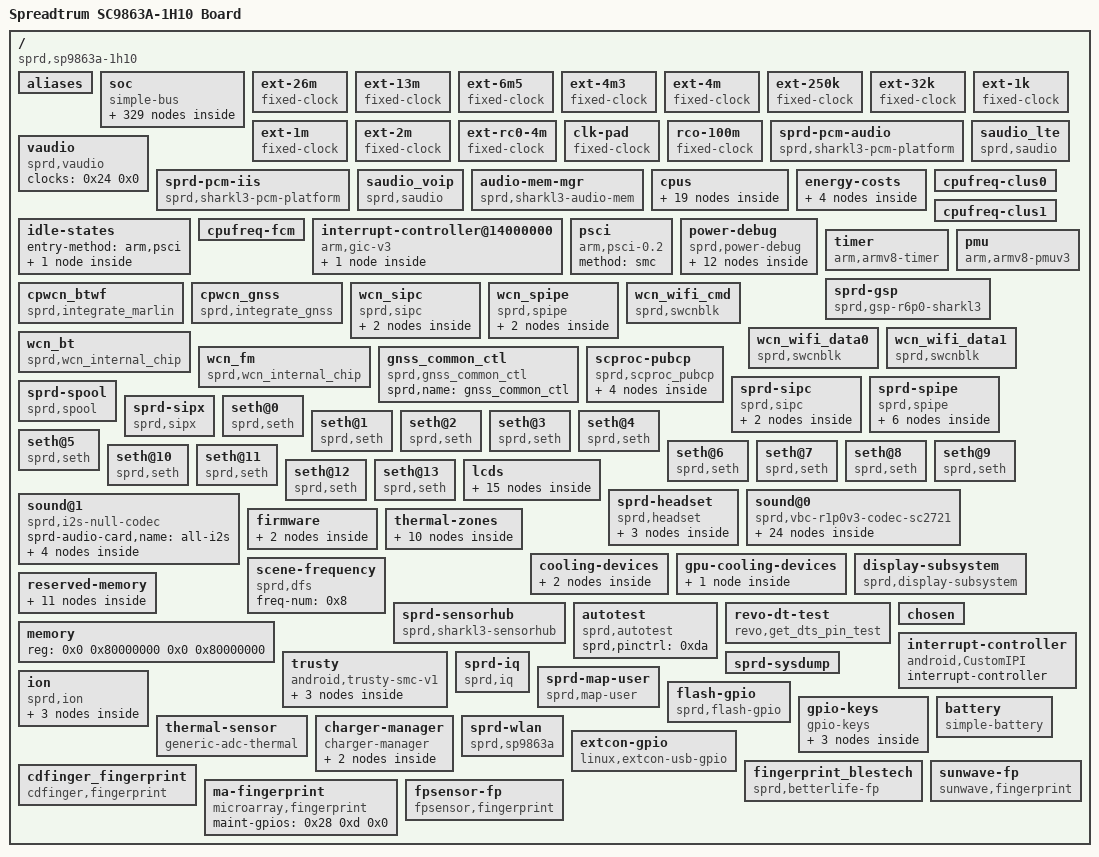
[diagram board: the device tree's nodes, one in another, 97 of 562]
/dts-v1/;

/ {
	interrupt-parent = <0x1>;
	#address-cells = <0x2>;
	#size-cells = <0x2>;
	cpuinfo_hardware = "Unisoc SC9863a";
	model = "Spreadtrum SC9863A-1H10 Board";
	compatible = "sprd,sp9863a-1h10", "sprd,sc9863a";
	sprd,sc-id = <0x2687 0x1 0x20000>;

	aliases {
		i2c0 = "/soc/ap-apb/i2c@70500000";
		i2c1 = "/soc/ap-apb/i2c@70600000";
		i2c2 = "/soc/ap-apb/i2c@70700000";
		i2c3 = "/soc/ap-apb/i2c@70800000";
		i2c4 = "/soc/ap-apb/i2c@70900000";
		i2c5 = "/soc/ap-apb/i2c@71500000";
		i2c6 = "/soc/ap-apb/i2c@71600000";
		i2c7 = "/soc/aon/i2c@40080000";
		spi0 = "/soc/ap-apb/spi@70a00000";
		spi1 = "/soc/ap-apb/spi@70b00000";
		spi2 = "/soc/ap-apb/spi@70c00000";
		spi3 = "/soc/ap-apb/spi@71400000";
		spi4 = "/soc/aon/spi@41800000";
		seth0 = "/seth@0";
		seth1 = "/seth@1";
		seth2 = "/seth@2";
		seth3 = "/seth@3";
		seth4 = "/seth@4";
		seth5 = "/seth@5";
		seth6 = "/seth@6";
		seth7 = "/seth@7";
		seth8 = "/seth@8";
		seth9 = "/seth@9";
		seth10 = "/seth@10";
		seth11 = "/seth@11";
		seth12 = "/seth@12";
		seth13 = "/seth@13";
		cooling-device0 = "/cooling-devices/cluster0-cooling";
		cooling-device1 = "/cooling-devices/cluster1-cooling";
		gpu-cooling0 = "/gpu-cooling-devices/gpu-cooling0";
		thm-sensor11 = "/thermal-zones/cpu-thmzone";
		serial0 = "/soc/ap-apb/serial@70000000";
		serial1 = "/soc/ap-apb/serial@70100000";
	};

	soc {
		compatible = "simple-bus";
		#address-cells = <0x2>;
		#size-cells = <0x2>;
		ranges;
		phandle = <0xe6>;

		modem-dbg-log@1000c000 {
			compatible = "sprd,dbg-log-sharkl3";
			reg = <0x0 0x1000c000 0x0 0x4000>;
			sprd,syscon-aon-apb = <0x2>;
			sprd,syscon-dsi-apb = <0x3>;
			sprd,syscon-pll-apb = <0x4>;
			sprd,ch-name = "TRAINING", "WTL", "MDAR", "TPIU", "DBUS", "WCN";
			sprd,ch-index = <0xf 0x1 0x0 0x2 0x3 0x4>;
			sprd,dcfix;
			sprd,mm;
			status = "okay";
			clock-names = "serdes_eb", "src0", "src1", "src2";
			clocks = <0x5 0x68 0x6 0x0 0x6 0x18 0x6 0x14>;
			phandle = <0xe7>;
		};

		syscon@20e00000 {
			compatible = "syscon";
			#syscon-cells = <0x2>;
			reg = <0x0 0x20e00000 0x0 0x10000>;
			phandle = <0x20>;
		};

		syscon@300e0000 {
			compatible = "syscon";
			#syscon-cells = <0x2>;
			reg = <0x0 0x300e0000 0x0 0x10000>;
			phandle = <0xbd>;
		};

		syscon@300f0000 {
			compatible = "syscon";
			#syscon-cells = <0x2>;
			reg = <0x0 0x300f0000 0x0 0x10000>;
			phandle = <0x73>;
		};

		mailbox@400a0000 {
			compatible = "sprd,mailbox";
			reg = <0x0 0x400a0000 0x0 0x8000 0x0 0x400a8000 0x0 0x8000>;
			syscons = <0x2 0x4 0x200000>;
			syscon-names = "clk";
			interrupts = <0x0 0x44 0x4 0x0 0x45 0x4 0x0 0x77 0x4>;
			sprd,sensor = <0x7>;
			sprd,core-cnt = <0x8>;
			sprd,version = <0x102>;
			phandle = <0xe8>;
		};

		syscon@40200000 {
			compatible = "syscon";
			#syscon-cells = <0x2>;
			reg = <0x0 0x40200000 0x0 0x10000>;
			phandle = <0xe9>;
		};

		syscon@402b0000 {
			compatible = "syscon";
			#syscon-cells = <0x2>;
			reg = <0x0 0x402b0000 0x0 0x10000>;
			phandle = <0x7>;
		};

		power-domain@402b0058 {
			compatible = "sprd,sharkl3-disp-domain";
			reg = <0x0 0x402b0058 0x0 0x20>;
			syscons = <0x7 0x58 0x2000000>;
			syscon-names = "power";
			#power-domain-cells = <0x0>;
			phandle = <0x60>;
		};

		syscon@402e0000 {
			compatible = "syscon";
			#syscon-cells = <0x2>;
			reg = <0x0 0x402e0000 0x0 0x10000>;
			phandle = <0x2>;
		};

		syscon@40350000 {
			compatible = "syscon";
			#syscon-cells = <0x2>;
			reg = <0x0 0x40350000 0x0 0x3000>;
			phandle = <0x3>;
		};

		syscon@40353000 {
			compatible = "syscon";
			#syscon-cells = <0x2>;
			reg = <0x0 0x40353000 0x0 0x6000>;
			phandle = <0x4>;
		};

		syscon@40359000 {
			compatible = "syscon";
			#syscon-cells = <0x2>;
			reg = <0x0 0x40359000 0x0 0x3000>;
			phandle = <0x21>;
		};

		syscon@4035c000 {
			compatible = "syscon";
			#syscon-cells = <0x2>;
			reg = <0x0 0x4035c000 0x0 0x3000>;
			phandle = <0x75>;
		};

		syscon@40363000 {
			compatible = "syscon";
			#syscon-cells = <0x2>;
			reg = <0x0 0x40363000 0x0 0x3000>;
			phandle = <0x29>;
		};

		syscon@40366000 {
			compatible = "syscon";
			#syscon-cells = <0x2>;
			reg = <0x0 0x40366000 0x0 0x3000>;
			phandle = <0xbe>;
		};

		syscon@403a0000 {
			compatible = "syscon";
			#syscon-cells = <0x2>;
			reg = <0x0 0x403a0000 0x0 0x10000>;
			phandle = <0xbf>;
		};

		syscon@60800000 {
			compatible = "syscon";
			#syscon-cells = <0x2>;
			reg = <0x0 0x60800000 0x0 0x10000>;
			phandle = <0x6c>;
		};

		syscon@62000000 {
			compatible = "syscon";
			#syscon-cells = <0x2>;
			reg = <0x0 0x62000000 0x0 0x10000>;
			phandle = <0x63>;
		};

		syscon@71300000 {
			compatible = "syscon";
			#syscon-cells = <0x2>;
			reg = <0x0 0x71300000 0x0 0x40000>;
			phandle = <0x1c>;
		};

		syscon@40500000 {
			compatible = "syscon";
			#syscon-cells = <0x2>;
			reg = <0x0 0x40500000 0x0 0x10000>;
			phandle = <0xaa>;
		};

		syscon@40510000 {
			compatible = "syscon";
			#syscon-cells = <0x2>;
			reg = <0x0 0x40510000 0x0 0x10000>;
			phandle = <0xab>;
		};

		syscon@40520000 {
			compatible = "syscon";
			#syscon-cells = <0x2>;
			reg = <0x0 0x40520000 0x0 0x10000>;
			phandle = <0xac>;
		};

		syscon@40530000 {
			compatible = "syscon";
			#syscon-cells = <0x2>;
			reg = <0x0 0x40530000 0x0 0x10000>;
			phandle = <0xad>;
		};

		syscon@40540000 {
			compatible = "syscon";
			#syscon-cells = <0x2>;
			reg = <0x0 0x40540000 0x0 0x10000>;
			phandle = <0xae>;
		};

		syscon@40550000 {
			compatible = "syscon";
			#syscon-cells = <0x2>;
			reg = <0x0 0x40550000 0x0 0x10000>;
			phandle = <0xaf>;
		};

		ap-apb {
			compatible = "simple-bus";
			#address-cells = <0x1>;
			#size-cells = <0x1>;
			ranges;

			serial@70000000 {
				compatible = "sprd,sc9863-uart", "sprd,sc9836-uart";
				reg = <0x70000000 0x100>;
				interrupts = <0x0 0x2 0x4>;
				clock-names = "enable", "uart", "source";
				clocks = <0x8 0xc 0x9 0x9 0xa>;
				status = "okay";
				phandle = <0xea>;
			};

			serial@70100000 {
				compatible = "sprd,sc9863-uart", "sprd,sc9836-uart";
				reg = <0x70100000 0x100>;
				interrupts = <0x0 0x3 0x4>;
				clock-names = "enable", "uart", "source";
				clocks = <0x8 0xd 0x9 0xa 0xa>;
				status = "okay";
				phandle = <0xeb>;
			};

			serial@70200000 {
				compatible = "sprd,sc9863-uart", "sprd,sc9836-uart";
				reg = <0x70200000 0x100>;
				interrupts = <0x0 0x4 0x4>;
				clock-names = "enable", "uart", "source";
				clocks = <0x8 0xe 0x9 0xb 0xa>;
				status = "disabled";
				phandle = <0xec>;
			};

			serial@70300000 {
				compatible = "sprd,sc9863-uart", "sprd,sc9836-uart";
				reg = <0x70300000 0x100>;
				interrupts = <0x0 0x5 0x4>;
				clock-names = "enable", "uart", "source";
				clocks = <0x8 0xf 0x9 0xc 0xa>;
				status = "disabled";
				phandle = <0xed>;
			};

			serial@70400000 {
				compatible = "sprd,sc9863-uart", "sprd,sc9836-uart";
				reg = <0x70400000 0x100>;
				interrupts = <0x0 0x6 0x4>;
				clock-names = "enable", "uart", "source";
				clocks = <0x8 0x10 0x9 0xd 0xa>;
				status = "disabled";
				phandle = <0xee>;
			};

			i2c@70500000 {
				compatible = "sprd,sharkl3-i2c";
				reg = <0x70500000 0x1000>;
				interrupts = <0x0 0xb 0x4>;
				clock-names = "enable", "i2c", "source";
				clock-frequency = <0x61a80>;
				#address-cells = <0x1>;
				#size-cells = <0x0>;
				status = "okay";
				clocks = <0x8 0x7 0x9 0xe 0xa>;
				phandle = <0xef>;

				sensor-main@20 {
					compatible = "sprd,sensor-main";
					reg = <0x20>;
					clock-names = "clk_src", "sensor_eb", "clk_96m", "clk_76m8", "clk_48m", "clk_26m";
					clocks = <0xb 0x30 0xc 0xb 0x6 0x4 0x6 0x10 0x6 0x5 0xa>;
					vddio-supply = <0xd>;
					vddcama-supply = <0xe>;
					vddcamd-supply = <0xf>;
					vddcammot-supply = <0x10>;
					sprd,phyid = <0x1>;
					csi = <0x11>;
					reset-gpios = <0x12 0x2c 0x0>;
					power-down-gpios = <0x12 0x2e 0x0>;
					avdd-gpios = <0x12 0x49 0x0>;
					phandle = <0xf0>;
				};
			};

			i2c@70600000 {
				compatible = "sprd,sharkl3-i2c";
				reg = <0x70600000 0x1000>;
				interrupts = <0x0 0xc 0x4>;
				clock-names = "enable", "i2c", "source";
				clock-frequency = <0x61a80>;
				#address-cells = <0x1>;
				#size-cells = <0x0>;
				status = "okay";
				clocks = <0x8 0x8 0x9 0xf 0xa>;
				phandle = <0xf1>;

				sensor-sub@20 {
					compatible = "sprd,sensor-sub";
					reg = <0x20>;
					clock-names = "clk_src", "sensor_eb", "clk_96m", "clk_76m8", "clk_48m", "clk_26m";
					clocks = <0xb 0x31 0xc 0xc 0x6 0x4 0x6 0x10 0x6 0x5 0xa>;
					vddio-supply = <0xd>;
					vddcama-supply = <0xe>;
					vddcamd-supply = <0xf>;
					vddcammot-supply = <0x10>;
					sprd,phyid = <0x0>;
					csi = <0x11>;
					reset-gpios = <0x12 0x29 0x0>;
					power-down-gpios = <0x12 0x28 0x0>;
					phandle = <0xf2>;
				};

				sensor-main2@6C {
					compatible = "sprd,sensor-main2";
					reg = <0x6c>;
					clock-names = "clk_src", "sensor_eb", "clk_96m", "clk_76m8", "clk_48m", "clk_26m";
					clocks = <0xb 0x31 0xc 0xc 0x6 0x4 0x6 0x10 0x6 0x5 0xa>;
					vddio-supply = <0xd>;
					vddcama-supply = <0xe>;
					vddcamd-supply = <0xf>;
					vddcammot-supply = <0x10>;
					sprd,phyid = <0x2>;
					csi = <0x13>;
					dvdd-gpios = <0x12 0x3e 0x0>;
					reset-gpios = <0x12 0x2d 0x0>;
					power-down-gpios = <0x12 0x2f 0x0>;
					phandle = <0xf3>;
				};
			};

			i2c@70700000 {
				compatible = "sprd,sharkl3-i2c";
				reg = <0x70700000 0x1000>;
				interrupts = <0x0 0xd 0x4>;
				clock-names = "enable", "i2c", "source";
				clock-frequency = <0x186a0>;
				#address-cells = <0x1>;
				#size-cells = <0x0>;
				status = "disabled";
				clocks = <0x8 0x9 0x9 0x10 0xa>;
				phandle = <0xf4>;
			};

			i2c@70800000 {
				compatible = "sprd,sharkl3-i2c";
				reg = <0x70800000 0x1000>;
				interrupts = <0x0 0xe 0x4>;
				clock-names = "enable", "i2c", "source";
				clock-frequency = <0x61a80>;
				#address-cells = <0x1>;
				#size-cells = <0x0>;
				status = "okay";
				clocks = <0x8 0xa 0x9 0x11 0xa>;
				phandle = <0xf5>;

				goodix_ts@5d {
					compatible = "goodix,gt1x";
					reg = <0x5d>;
					pinctrl-names = "pmx_ts_wakeup", "pmx_ts_normal", "pmx_ts_poweroff", "pmx_ts_sleep";
					pinctrl-0 = <0x14 0x15>;
					pinctrl-1 = <0x16 0x15>;
					pinctrl-2 = <0x17 0x18>;
					pinctrl-3 = <0x17 0x15>;
					reset-gpio = <0x12 0x91 0x0>;
					irq-gpio = <0x12 0x90 0x0>;
					goodix,default-config0 = [4b d0 02 f0 05 25 34 08 20 41 04 0a 78 5a 53 01 01 01 00 00 14 17 19 1d 18 04 00 00 0c 0f 00 00 53 00 14 00 00 00 00 00 00 00 00 64 28 32 8b 2d 0c 3c 3e a2 07 61 3b 62 1b 02 24 00 00 32 5a c0 14 02 00 00 53 a4 38 96 3f 8a 45 7f 4c 78 53 71 00 00 00 00 00 00 00 f0 50 3c aa aa 07 00 00 00 00 00 00 00 00 00 00 00 00 00 00 00 00 3c 00 00 00 00 00 00 00 00 00 00 00 00 00 00 00 00 00 00 df 07 32 10 64 50 50 00 00 00 00 00 01 08 02 09 03 0a 04 0b 05 0c 06 0d ff ff 00 01 02 03 04 05 06 07 08 09 0a 0b 17 16 15 14 13 12 11 10 0f 0e 0d 0c 18 19 00 00 00 00 00 00 00 00 00 00 00 00 00 20 1e 00 05 1e 00 03 1c 1e 19 14 02 00 03 0a 05 32 64 00 00 00 03 00 01 ff e4 84 33 03 eb 06 18 00 14 1e 44 28 3c 28 20 00 00 08 13 94 01];
				};

				tlsc6x@2e {
					compatible = "tlsc6x,tlsc6x_ts";
					reg = <0x2e>;
					reset-gpio = <0x12 0x91 0x0>;
					irq-gpio = <0x12 0x90 0x0>;
				};

				msg2xxx@26 {
					compatible = "msg,msg2xxx";
					reg = <0x26>;
					reset-gpio = <0x12 0x91 0x0>;
					irq-gpio = <0x12 0x90 0x0>;
				};

				focaltech@38 {
					compatible = "focaltech,fts";
					reg = <0x38>;
					reset-gpio = <0x12 0x91 0x0>;
					irq-gpio = <0x12 0x90 0x0>;
					pinctrl-names = "pmx_ts_active", "pmx_ts_suspend", "pmx_ts_release";
					pinctrl-0 = <0x16 0x15>;
					pinctrl-1 = <0x17 0x15>;
					pinctrl-2 = <0x17 0x18>;
					focaltech,reset-gpio = <0x12 0x91 0x0>;
					focaltech,irq-gpio = <0x12 0x90 0x0>;
					focaltech,max-touch-number = <0xa>;
				};

				cst3xx@1a {
					compatible = "cst3xx,cst3xx_ts";
					reg = <0x1a>;
					reset-gpio = <0x12 0x91 0x0>;
					irq-gpio = <0x12 0x90 0x0>;
				};

				himax@48 {
					compatible = "himax,himax_ts";
					reg = <0x48>;
					reset-gpio = <0x12 0x91 0x0>;
					irq-gpio = <0x12 0x90 0x0>;
				};

				ilitek@41 {
					compatible = "tchip,ilitek";
					reg = <0x41>;
					touch,irq-gpio = <0x12 0x90 0x1>;
					touch,reset-gpio = <0x12 0x91 0x1>;
				};
			};

			i2c@70900000 {
				compatible = "sprd,sharkl3-i2c";
				reg = <0x70900000 0x1000>;
				interrupts = <0x0 0xf 0x4>;
				clock-names = "enable", "i2c", "source";
				clock-frequency = <0x61a80>;
				#address-cells = <0x1>;
				#size-cells = <0x0>;
				status = "okay";
				clocks = <0x8 0xb 0x9 0x12 0xa>;
				phandle = <0xf6>;

				charger@6a {
					compatible = "fairchild,fan54015_chg";
					reg = <0x6a>;
					phys = <0x19>;
					monitored-battery = <0x1a>;
					extcon = <0x1b>;
					phandle = <0xf7>;

					otg-vbus {
						regulator-name = "vddvbus";
						phandle = <0x1f>;
					};
				};

				flash-ic@63 {
					compatible = "sprd,flash-ocp8137";
					reg = <0x63>;
					sprd,flash-ic = <0x1fc9>;
					sprd,torch = <0x1>;
					sprd,preflash = <0x1>;
					sprd,highlight = <0x1>;
					sprd,torch-level = <0x80>;
					sprd,preflash-level = <0x80>;
					sprd,highlight-level = <0x80>;
					sprd,lvfm-enable = <0x1>;
					flash-torch-en-gpios = <0x12 0x58 0x0>;
					flash-chip-en-gpios = <0x12 0x59 0x0>;
					flash-en-gpios = <0x12 0x4c 0x0>;
					flash-sync-gpios = <0x12 0x8d 0x0>;
					phandle = <0xf8>;
				};
			};

			spi@70a00000 {
				compatible = "sprd,sc9863-spi";
				reg = <0x70a00000 0x1000>;
				interrupts = <0x0 0x7 0x4>;
				#address-cells = <0x1>;
				#size-cells = <0x0>;
				status = "okay";
				clock-names = "enable", "spi", "source";
				clocks = <0x8 0x4 0x9 0x15 0x6 0x3>;
				phandle = <0xf9>;
			};

			spi@70b00000 {
				compatible = "sprd,sc9863-spi";
				reg = <0x70b00000 0x1000>;
				interrupts = <0x0 0x8 0x4>;
				#address-cells = <0x1>;
				#size-cells = <0x0>;
				status = "disabled";
				clock-names = "enable", "spi", "source";
				clocks = <0x8 0x5 0x9 0x16 0x6 0x3>;
				phandle = <0xfa>;
			};

			spi@70c00000 {
				compatible = "sprd,sc9863-spi";
				reg = <0x70c00000 0x1000>;
				interrupts = <0x0 0x9 0x4>;
				#address-cells = <0x1>;
				#size-cells = <0x0>;
				status = "disabled";
				clock-names = "enable", "spi", "source";
				clocks = <0x8 0x6 0x9 0x17 0x6 0x3>;
				phandle = <0xfb>;
			};

			i2s@70d00000 {
				compatible = "sprd,i2s";
				reg = <0x70d00000 0x100000>;
				sprd,dai_name = "i2s_bt_sco0";
				sprd,hw_port = <0x0>;
				sprd,syscon-ap-apb = <0x1c>;
				#sound-dai-cells = <0x0>;
				status = "okay";
				clock-names = "clk_iis0", "clk_twpll_128m", "clk_twpll_153m6";
				clocks = <0x9 0x19 0x6 0xa 0x6 0xf>;
				sprd,config_type = "pcm";
				sprd,slave_timeout = <0xf11>;
				sprd,_hw_port = <0x0>;
				sprd,fs = <0x1f40>;
				sprd,bus_type = <0x1>;
				sprd,rtx_mode = <0x3>;
				sprd,byte_per_chan = <0x1>;
				sprd,slave_mode = <0x0>;
				sprd,lsb = <0x0>;
				sprd,lrck = <0x0>;
				sprd,low_for_left = <0x1>;
				sprd,clk_inv = <0x0>;
				sprd,pcm_short_frame = <0x1>;
				sprd,pcm_slot = <0x1>;
				sprd,pcm_cycle = <0x1>;
				sprd,tx_watermark = <0xc>;
				sprd,rx_watermark = <0x14>;
				phandle = <0xd1>;
			};

			spi@71400000 {
				compatible = "sprd,sc9863-spi";
				reg = <0x71400000 0x1000>;
				interrupts = <0x0 0x13 0x4>;
				#address-cells = <0x1>;
				#size-cells = <0x0>;
				status = "disabled";
				clock-names = "enable", "spi", "source";
				clocks = <0x8 0x12 0x9 0x18 0x6 0x3>;
				phandle = <0xfc>;
			};

			i2c@71500000 {
				compatible = "sprd,sharkl3-i2c";
				reg = <0x71500000 0x1000>;
				interrupts = <0x0 0x74 0x4>;
				clock-names = "enable", "i2c", "source";
				clock-frequency = <0x186a0>;
				#address-cells = <0x1>;
				#size-cells = <0x0>;
				status = "disabled";
				clocks = <0x8 0x13 0x9 0x13 0xa>;
				phandle = <0xfd>;
			};

			i2c@71600000 {
				compatible = "sprd,sharkl3-i2c";
				reg = <0x71600000 0x1000>;
				interrupts = <0x0 0x75 0x4>;
				clock-names = "enable", "i2c", "source";
				clock-frequency = <0x186a0>;
				#address-cells = <0x1>;
				#size-cells = <0x0>;
				status = "disabled";
				clocks = <0x8 0x14 0x9 0x14 0xa>;
				phandle = <0xfe>;
			};
		};

		ap-ahb {
			compatible = "simple-bus";
			#address-cells = <0x1>;
			#size-cells = <0x1>;
			ranges;

			dma-controller@20100000 {
				compatible = "sprd,sharkl3-dma";
				reg = <0x20100000 0x4000>;
				interrupts = <0x0 0x32 0x4>;
				#dma-cells = <0x1>;
				#dma-channels = <0x1c>;
				clock-names = "enable";
				clocks = <0x1d 0x1>;
				phandle = <0x9b>;
			};

			usb@20200000 {
				compatible = "sprd,sharkl3-musb";
				reg = <0x20200000 0x2000>;
				interrupts = <0x0 0x37 0x4>;
				interrupt-names = "mc";
				clocks = <0x1d 0x0>;
				clock-names = "core_clk";
				phy-type = "usb20_sprd_phy";
				usb-phy = <0x19>;
				phy-names = "usb";
				dr-mode = "peripheral";
				sprd,cable-detection-method = "typec";
				extcon = <0x1b 0x1e>;
				vbus-supply = <0x1f>;
				phandle = <0xff>;
			};

			hsphy@20e00000 {
				compatible = "sprd,sharkl3-phy";
				reg = <0x20e00000 0x3030>;
				reg-names = "phy_glb_regs";
				sprd,syscon-enable = <0x2>;
				sprd,syscon-apahb = <0x20>;
				sprd,syscon-anag4 = <0x21>;
				sprd,vdd-voltage = <0x2e8a10>;
				io-channels = <0x22 0x1e 0x22 0x1f>;
				io-channel-names = "dp", "dm";
				#phy-cells = <0x0>;
				vdd-supply = <0x23>;
				extcon = <0x1b>;
				phandle = <0x19>;
			};

			sdio@20600000 {
				compatible = "sprd,sdhc-r11p1";
				reg = <0x20600000 0x1000>;
				interrupts = <0x0 0x3c 0x4>;
				status = "okay";
				clock-names = "sdio_clk", "sdio_clk_source", "sdio_ahb_enable";
				clocks = <0xb 0x21 0x24 0x2 0x1d 0x7>;
				sprd,hs400es-dly = <0x55 0x7f 0x38 0x38>;
				sprd,hs400-dly = <0x55 0xd3 0x35 0x35>;
				sprd,hs200-dly = <0x7f 0xcd 0xcd 0xcd>;
				sprd,ddr52-dly = <0x32 0x23 0x18 0x18>;
				vmmc-supply = <0x25>;
				voltage-ranges = <0xbb8 0xbb8>;
				bus-width = <0x8>;
				non-removable;
				cap-mmc-hw-reset;
				mmc-hs400-enhanced-strobe;
				mmc-hs400-1_8v;
				mmc-hs200-1_8v;
				mmc-ddr-1_8v;
				sprd,name = "sdio_emmc";
				sprd,sdio-adma;
				no-sdio;
				no-sd;
				phandle = <0x100>;
			};

			sdio@20300000 {
				compatible = "sprd,sdhc-r11p1";
				reg = <0x20300000 0x1000>;
				interrupts = <0x0 0x39 0x4>;
				status = "okay";
				clock-names = "sdio_clk", "sdio_clk_source", "sdio_ahb_enable";
				clocks = <0xb 0x1e 0x24 0x2 0x1d 0x4>;
				sprd,sdr104-dly = <0x7f 0xd1 0xd1 0xd1>;
				sprd,sdr50-dly = <0x7f 0xff 0xff 0xff>;
				sprd,sdhs-dly = <0x7f 0x23 0x22 0x22>;
				vmmc-supply = <0x26>;
				vqmmc-supply = <0x27>;
				voltage-ranges = <0xbb8 0xbb8>;
				bus-width = <0x4>;
				sd-uhs-sdr104;
				sd-uhs-sdr50;
				sprd,name = "sdio_sd";
				sprd,sdio-adma;
				no-sdio;
				no-mmc;
				cd-gpios = <0x28 0x9 0x0>;
				phandle = <0x101>;
			};
		};

		aon {
			compatible = "simple-bus";
			#address-cells = <0x1>;
			#size-cells = <0x1>;
			ranges;

			audio-codec@40000000 {
				compatible = "sprd,sharkl3-audio-codec";
				reg = <0x40000000 0x2000>;
				interrupts = <0x0 0x14 0x0>;
				sprd,syscon-aon-apb = <0x2>;
				sprd,anlg-phy-g-syscon = <0x29>;
				phandle = <0x5e>;
			};

			vbc@40020000 {
				compatible = "sprd,vbc-r1p0v3";
				#sound-dai-cells = <0x1>;
				reg = <0x40020000 0x10000>;
				sprd,clk-stable = <0x402d0060 0x4>;
				sprd,syscon-aon-apb = <0x2>;
				sprd,syscon-pmu-apb = <0x7>;
				sprd,dynamic-eq-support = <0x0>;
				sprd,vbc-iis-lr-invert = <0x0 0x1 0x1>;
				sprd,vbc-use-dma-type = <0x0 0x0 0x0 0x0>;
				sprd,vbc-use-ad01-only = <0x1>;
				sprd,iis_bt_fm_loop = <0x3 0x4>;
				pinctrl-names = "vbc_iis1_0", "ap_iis0_0", "ap_iis1_0", "tgdsp_iis0_0", "tgdsp_iis1_0", "pubcp_iis0_0", "vbc_iis1_3", "ap_iis0_3", "tgdsp_iis0_3", "tgdsp_iis1_3", "pubcp_iis0_3", "wcn_iis0_3", "vbc_iis1_4", "ap_iis0_4", "tgdsp_iis0_4", "tgdsp_iis1_4", "pubcp_iis0_4", "wcn_iis0_4", "iis_bt_fm_loop_3_4_enable", "iis_bt_fm_loop_3_4_disable";
				pinctrl-0 = <0x2a>;
				pinctrl-1 = <0x2b>;
				pinctrl-2 = <0x2c>;
				pinctrl-3 = <0x2d>;
				pinctrl-4 = <0x2e>;
				pinctrl-5 = <0x2f>;
				pinctrl-6 = <0x30>;
				pinctrl-7 = <0x31>;
				pinctrl-8 = <0x32>;
				pinctrl-9 = <0x33>;
				pinctrl-10 = <0x34>;
				pinctrl-11 = <0x35>;
				pinctrl-12 = <0x36>;
				pinctrl-13 = <0x37>;
				pinctrl-14 = <0x38>;
				pinctrl-15 = <0x39>;
				pinctrl-16 = <0x3a>;
				pinctrl-17 = <0x3b>;
				pinctrl-18 = <0x3c>;
				pinctrl-19 = <0x3d>;
				phandle = <0xcd>;
			};

			dma-controller@40100000 {
				compatible = "sprd,sharkl3-dma";
				reg = <0x40100000 0x4000>;
				#dma-cells = <0x1>;
				#dma-channels = <0x9>;
				clock-names = "enable";
				clocks = <0x5 0x32>;
				phandle = <0x9a>;
			};

			gpio@40210000 {
				compatible = "sprd,sharkl3-eic-debounce";
				reg = <0x40210000 0x80 0x40370000 0x80>;
				gpio-controller;
				#gpio-cells = <0x2>;
				interrupt-controller;
				#interrupt-cells = <0x2>;
				interrupts = <0x0 0x25 0x4>;
				phandle = <0xe5>;
			};

			gpio@40210080 {
				compatible = "sprd,sharkl3-eic-latch";
				reg = <0x40210080 0x20 0x40370080 0x20>;
				gpio-controller;
				#gpio-cells = <0x2>;
				interrupt-controller;
				#interrupt-cells = <0x2>;
				interrupts = <0x0 0x25 0x4>;
				phandle = <0x102>;
			};

			gpio@402100a0 {
				compatible = "sprd,sharkl3-eic-async";
				reg = <0x402100a0 0x20 0x403700a0 0x20>;
				gpio-controller;
				#gpio-cells = <0x2>;
				interrupt-controller;
				#interrupt-cells = <0x2>;
				interrupts = <0x0 0x25 0x4>;
				phandle = <0x28>;
			};

			gpio@402100c0 {
				compatible = "sprd,sharkl3-eic-sync";
				reg = <0x402100c0 0x20 0x403700c0 0x20>;
				gpio-controller;
				#gpio-cells = <0x2>;
				interrupt-controller;
				#interrupt-cells = <0x2>;
				interrupts = <0x0 0x25 0x4>;
				phandle = <0x103>;
			};

			timer@40230000 {
				compatible = "sprd,syst-timer";
				reg = <0x40230000 0x10>;
				clocks = <0x3e>;
				phandle = <0x104>;
			};

			timer@40040000 {
				compatible = "sprd,sysfrt-timer";
				reg = <0x40040000 0x10>;
				clocks = <0x3f>;
				phandle = <0x105>;
			};

			timer@40050000 {
				compatible = "sprd,sharkl3-timer";
				reg = <0x40050000 0x14>;
				interrupts = <0x0 0x1b 0x4>;
				clocks = <0x3f>;
			};

			timer@40050020 {
				compatible = "sprd,sharkl3-suspend-timer";
				reg = <0x40050020 0x14>;
				interrupts = <0x0 0x1c 0x4>;
				clocks = <0x3f>;
			};

			efuse@40240000 {
				compatible = "sprd,sharkl3-efuse";
				reg = <0x40240000 0x10000>;
				clock-names = "enable";
				hwlocks = <0x40 0x8>;
				clocks = <0x5 0xd>;
				phandle = <0x106>;

				gthm-delta@21 {
					reg = <0x21 0x4>;
					bits = <0x1 0x7>;
					phandle = <0x51>;
				};

				cthm-sign@22 {
					reg = <0x22 0x4>;
					bits = <0x0 0x1>;
					phandle = <0x52>;
				};

				cthm-ratio@22 {
					reg = <0x22 0x4>;
					bits = <0x1 0x7>;
					phandle = <0x53>;
				};

				cthm-delta@23 {
					reg = <0x23 0x4>;
					bits = <0x0 0x7>;
					phandle = <0x54>;
				};

				wcn-alpha@14 {
					reg = <0x14 0x4>;
					phandle = <0xc3>;
				};

				wcn-beta@18 {
					reg = <0x18 0x4>;
					phandle = <0xc4>;
				};

				wcn-gamma@1c {
					reg = <0x1c 0x4>;
					phandle = <0xc5>;
				};

				wcn-delta@20 {
					reg = <0x20 0x4>;
					phandle = <0xc7>;
				};

				dvfs-bin-dsu@a {
					reg = <0xa 0x4>;
					bits = <0x4 0x4>;
					phandle = <0xa9>;
				};

				dvfs-bin-cpu0@9 {
					reg = <0x9 0x4>;
					bits = <0x0 0x4>;
					phandle = <0xa5>;
				};

				dvfs-bin-cpu1@9 {
					reg = <0x9 0x4>;
					bits = <0x4 0x4>;
					phandle = <0xa7>;
				};
			};

			pwm@40260000 {
				compatible = "sprd,sharkl3-pwm", "sprd,sharkl5-pwm";
				reg = <0x40260000 0x10000>;
				clock-names = "clk_parent", "clk_pwm0", "clk_pwm0_eb", "clk_pwm1", "clk_pwm1_eb", "clk_pwm2", "clk_pwm2_eb";
				clocks = <0xa 0xb 0xf 0x5 0x4 0xb 0x10 0x5 0x5 0xb 0x11 0x5 0x6>;
				#pwm-cells = <0x2>;
				phandle = <0x107>;
			};

			pinctrl@402a0000 {
				compatible = "sprd,sharkl3-pinctrl";
				reg = <0x402a0000 0x10000>;
				pinctrl-names = "gpio_121", "gpio_122", "gpio_123", "gpio_124", "gpio_125", "gpio_126", "gpio_144", "gpio_145", "gpio_146", "gpio_147", "shutdown";
				pinctrl-0 = <0x41>;
				pinctrl-1 = <0x42>;
				pinctrl-2 = <0x43>;
				pinctrl-3 = <0x44>;
				pinctrl-4 = <0x45>;
				pinctrl-5 = <0x46>;
				pinctrl-6 = <0x47>;
				pinctrl-7 = <0x48>;
				pinctrl-8 = <0x49>;
				pinctrl-9 = <0x4a>;
				pinctrl-10 = <0x4b 0x4c 0x4d 0x4e 0x4f 0x50>;
				phandle = <0xda>;

				iismtx-inf0-8 {
					pins = "SHARKL3_IIS_INF0_SYS_SEL";
					sprd,control = <0x8>;
					phandle = <0x2a>;
				};

				iismtx-inf0-0 {
					pins = "SHARKL3_IIS_INF0_SYS_SEL";
					sprd,control = <0x0>;
					phandle = <0x2b>;
				};

				iismtx-inf0-1 {
					pins = "SHARKL3_IIS_INF0_SYS_SEL";
					sprd,control = <0x1>;
					phandle = <0x2c>;
				};

				iismtx-inf0-4 {
					pins = "SHARKL3_IIS_INF0_SYS_SEL";
					sprd,control = <0x4>;
					phandle = <0x2d>;
				};

				iismtx-inf0-5 {
					pins = "SHARKL3_IIS_INF0_SYS_SEL";
					sprd,control = <0x5>;
					phandle = <0x2e>;
				};

				iismtx-inf0-3 {
					pins = "SHARKL3_IIS_INF0_SYS_SEL";
					sprd,control = <0x3>;
					phandle = <0x2f>;
				};

				iismtx-inf3-8 {
					pins = "SHARKL3_IIS_INF3_SYS_SEL";
					sprd,control = <0x8>;
					phandle = <0x30>;
				};

				iismtx-inf3-0 {
					pins = "SHARKL3_IIS_INF3_SYS_SEL";
					sprd,control = <0x0>;
					phandle = <0x31>;
				};

				iismtx-inf3-4 {
					pins = "SHARKL3_IIS_INF3_SYS_SEL";
					sprd,control = <0x4>;
					phandle = <0x32>;
				};

				iismtx-inf3-5 {
					pins = "SHARKL3_IIS_INF3_SYS_SEL";
					sprd,control = <0x5>;
					phandle = <0x33>;
				};

				iismtx-inf3-3 {
					pins = "SHARKL3_IIS_INF3_SYS_SEL";
					sprd,control = <0x3>;
					phandle = <0x34>;
				};

				iismtx-inf3-11 {
					pins = "SHARKL3_IIS_INF3_SYS_SEL";
					sprd,control = <0xb>;
					phandle = <0x35>;
				};

				iismtx-inf4-8 {
					pins = "SHARKL3_IIS_INF4_SYS_SEL";
					sprd,control = <0x8>;
					phandle = <0x36>;
				};

				iismtx-inf4-0 {
					pins = "SHARKL3_IIS_INF4_SYS_SEL";
					sprd,control = <0x0>;
					phandle = <0x37>;
				};

				iismtx-inf4-4 {
					pins = "SHARKL3_IIS_INF4_SYS_SEL";
					sprd,control = <0x4>;
					phandle = <0x38>;
				};

				iismtx-inf4-5 {
					pins = "SHARKL3_IIS_INF4_SYS_SEL";
					sprd,control = <0x5>;
					phandle = <0x39>;
				};

				iismtx-inf4-3 {
					pins = "SHARKL3_IIS_INF4_SYS_SEL";
					sprd,control = <0x3>;
					phandle = <0x3a>;
				};

				iismtx-inf4-11 {
					pins = "SHARKL3_IIS_INF4_SYS_SEL";
					sprd,control = <0xb>;
					phandle = <0x3b>;
				};

				iismtx-inf3-inf4-loop-1 {
					pins = "SHARKL3_IIS_INF4_INF3_LOOP";
					sprd,control = <0x1>;
					phandle = <0x3c>;
				};

				iismtx-inf3-inf4-loop-0 {
					pins = "SHARKL3_IIS_INF4_INF3_LOOP";
					sprd,control = <0x0>;
					phandle = <0x3d>;
				};

				ts_int_pullup {
					pins = "SHARKL3_EXTINT0_MISC";
					drive-strength = <0x8>;
					bias-pull-up;
					phandle = <0x14>;
				};

				ts_int_nopull {
					pins = "SHARKL3_EXTINT0_MISC";
					drive-strength = <0x2>;
					bias-disable;
					phandle = <0x16>;
				};

				ts_int_pulldown {
					pins = "SHARKL3_EXTINT0_MISC";
					drive-strength = <0x2>;
					bias-pull-down;
					phandle = <0x17>;
				};

				ts_reset_pullup {
					pins = "SHARKL3_EXTINT1_MISC";
					drive-strength = <0x8>;
					bias-pull-up;
					phandle = <0x15>;
				};

				ts_reset_pulldown {
					pins = "SHARKL3_EXTINT1_MISC";
					drive-strength = <0x2>;
					bias-pull-down;
					phandle = <0x18>;
				};

				keyout0 {
					pins = "SHARKL3_KEYOUT0";
					function = "func4";
					phandle = <0x41>;
				};

				keyout1 {
					pins = "SHARKL3_KEYOUT1";
					function = "func4";
					phandle = <0x42>;
				};

				keyout2 {
					pins = "SHARKL3_KEYOUT2";
					function = "func4";
					phandle = <0x43>;
				};

				keyin0 {
					pins = "SHARKL3_KEYIN0";
					function = "func4";
					phandle = <0x44>;
				};

				keyin1 {
					pins = "SHARKL3_KEYIN1";
					function = "func4";
					phandle = <0x45>;
				};

				keyin2 {
					pins = "SHARKL3_KEYIN2";
					function = "func4";
					phandle = <0x46>;
				};

				extint0 {
					pins = "SHARKL3_EXTINT0";
					function = "func4";
					phandle = <0x47>;
				};

				extint1 {
					pins = "SHARKL3_EXTINT1";
					function = "func4";
					phandle = <0x48>;
				};

				scl3 {
					pins = "SHARKL3_SCL3";
					function = "func4";
					phandle = <0x49>;
				};

				sda3 {
					pins = "SHARKL3_SDA3";
					function = "func4";
					phandle = <0x4a>;
				};

				rfsen0 {
					pins = "SHARKL3_RFSEN0";
					function = "func4";
					phandle = <0x4b>;
				};

				rfsck0 {
					pins = "SHARKL3_RFSCK0";
					function = "func4";
					phandle = <0x4c>;
				};

				rfsda0 {
					pins = "SHARKL3_RFSDA0";
					function = "func4";
					phandle = <0x4d>;
				};

				rfsen1 {
					pins = "SHARKL3_RFSEN1";
					function = "func4";
					phandle = <0x4e>;
				};

				rfsck1 {
					pins = "SHARKL3_RFSCK1";
					function = "func4";
					phandle = <0x4f>;
				};

				rfsda1 {
					pins = "SHARKL3_RFSDA1";
					function = "func4";
					phandle = <0x50>;
				};
			};

			gpio-controller@402c0000 {
				compatible = "sprd,sharkl3-gpio-plus";
				reg = <0x402c0000 0x1000>;
				gpio-controller;
				#gpio-cells = <0x2>;
				interrupt-controller;
				#interrupt-cells = <0x2>;
				interrupts = <0x0 0x82 0x4>;
				phandle = <0x12>;
			};

			gpu-thm@402f0000 {
				compatible = "sprd,sharkl3-thermal";
				reg = <0x402f0000 0x10000>;
				clock-names = "enable";
				clocks = <0x5 0x20>;
				#thermal-sensor-cells = <0x1>;
				sprd,algor_ver = <0x2>;
				nvmem-cells = <0x51>;
				nvmem-cell-names = "thm_delta_cal";
				phandle = <0xd6>;
			};

			cpu-thm@40390000 {
				compatible = "sprd,sharkl3-thermal";
				reg = <0x40390000 0x10000>;
				clock-names = "enable";
				clocks = <0x5 0x20>;
				#thermal-sensor-cells = <0x1>;
				sprd,algor_ver = <0x1>;
				nvmem-cells = <0x52 0x53 0x54>;
				nvmem-cell-names = "thm_sign_cal", "thm_ratio_cal", "thm_delta_cal";
				phandle = <0xd2>;
			};

			hwspinlock@40060000 {
				compatible = "sprd,hwspinlock-r3p0";
				reg = <0x40060000 0x10000>;
				#hwlock-cells = <0x1>;
				clock-names = "enable";
				clocks = <0x5 0x16>;
				phandle = <0x40>;
			};

			i2c@40080000 {
				compatible = "sprd,sharkl3-hw-i2c";
				reg = <0x40080000 0x1000>;
				interrupts = <0x0 0x22 0x4>;
				clock-names = "enable", "i2c", "source", "clk_hw_i2c";
				clock-frequency = <0x61a80>;
				#address-cells = <0x1>;
				#size-cells = <0x0>;
				status = "okay";
				phandle = <0x108>;

				regulator@60 {
					compatible = "fcs,fan53555";
					reg = <0x60>;
					regulator-name = "fan53555";
					regulator-min-microvolt = <0x93378>;
					regulator-max-microvolt = <0x1587b8>;
					regulator-ramp-delay = <0xfa00>;
					regulator-always-on;
					fcs,suspend-voltage-selector = <0x1>;
					phandle = <0x9c>;
				};
			};

			hwdvfs@40300000 {
				compatible = "sprd,sharkl3-hwdvfs";
				sprd,syscon-enable = <0x2>;
				sprd,anlg-phy-g4-ctrl = <0x21>;
				reg = <0x40300000 0x1000>;
				interrupts = <0x0 0x79 0x4>;
				phandle = <0x109>;

				cluster@0 {
					reg = <0x0>;
					dcdc-ctrl = <0x55>;
					phandle = <0x10a>;
				};

				cluster@1 {
					reg = <0x1>;
					dcdc-ctrl = <0x56>;
					phandle = <0x10b>;
				};

				dsu@0 {
					reg = <0x0>;
					dcdc-ctrl = <0x56>;
					phandle = <0x10c>;
				};

				dcdc-controller@0 {
					reg = <0x0 0x0>;
					volt-via-adi;
					volt-hold-us = <0x32>;
					volt-pause-us = <0x5>;
					volt-timeout-us = <0x320>;
					volt-stable-us = <0x5>;
					volt-max-step-microvolt = <0x61a8>;
					phandle = <0x56>;
				};

				dcdc-controller@1 {
					reg = <0x1 0x2>;
					volt-via-i2c;
					volt-hold-us = <0x19>;
					volt-pause-us = <0x14>;
					volt-timeout-us = <0x320>;
					volt-stable-us = <0x19>;
					volt-max-step-microvolt = <0x124f84>;
					phandle = <0x55>;
				};
			};

			sprd-swdvfs {
				compatible = "sprd,sharkl3-swdvfs";
				phandle = <0x10d>;
			};

			watchdog@40310000 {
				compatible = "sprd,sharkl3-wdt";
				reg = <0x40310000 0x1000>;
				interrupts = <0x0 0x7c 0x4>;
				timeout-sec = <0x1e>;
				clock-names = "enable", "rtc_enable";
				clocks = <0x5 0x26 0x5 0x42>;
			};

			djtag@40340000 {
				compatible = "sprd,djtag";
				reg = <0x40340000 0x1000>;
				syscon-names = "soft_rst";
				syscons = <0x2 0x130 0x80>;
				clock-names = "enable", "tck";
				clocks = <0x5 0x30 0x5 0x29>;
				hwlocks = <0x40 0xa>;
				hwlock-names = "djtag";
				#address-cells = <0x1>;
				#size-cells = <0x0>;
				phandle = <0x10e>;

				aon-busmonitor@3 {
					compatible = "sprd,sharkl3-busmonitor";
					interrupts = <0x0 0x5c 0x4>;
					reg = <0x3>;
					sprd,bm-num = <0x7>;
					sprd,bm-name = "AP", "WTLCP", "PUBCP", "SP", "DMA", "EAXI", "WCN";
					sprd,bm-type = <0x1 0x1 0x1 0x1 0x1 0x1 0x1>;
					sprd,bm-dap = <0x0 0x2 0x1 0x3 0x4 0x5 0x9>;
					sprd,bm-config = <0x0 0x1 0x1 0x0 0x1 0x1 0x0 0x1 0x1 0x0 0x1 0x1 0x0 0x1 0x1 0x0 0x1 0x1 0x0 0x1 0x1>;
					sprd,bm-id = <0x0 0x0 0x0 0x0 0x0 0x0 0x0 0x0 0x0 0x0 0x0 0x0 0x0 0x0 0x0 0x0 0x0 0x0 0x0 0x0 0x0>;
					sprd,bm-ranges = <0x0 0x0 0x0 0x0 0x0 0x0 0x0 0x0 0x0 0x0 0x0 0x0 0x0 0x0>;
				};

				apcpu-busmonitor@7 {
					compatible = "sprd,sharkl3-busmonitor";
					interrupts = <0x0 0x57 0x4>;
					reg = <0x7>;
					sprd,bm-num = <0x2>;
					sprd,bm-name = "ACE", "AP";
					sprd,bm-type = <0x1 0x1>;
					sprd,bm-dap = <0x1 0x2>;
					sprd,bm-config = <0x0 0x1 0x1 0x0 0x1 0x1>;
					sprd,bm-id = <0x0 0x0 0x0 0x0 0x0 0x0>;
					sprd,bm-ranges = <0x0 0x0 0x0 0x0>;
				};
			};

			spi@41800000 {
				compatible = "sprd,sharkl3-adi";
				reg = <0x41800000 0x200000>;
				#address-cells = <0x1>;
				#size-cells = <0x0>;
				sprd,hw-channels = <0x21 0x8c20 0x23 0x8cc4 0x24 0x8cd0 0x13 0x8c44 0x14 0x8c44 0x15 0x8c44 0x16 0x8c44>;
				phandle = <0x10f>;

				pmic@0 {
					compatible = "sprd,sc2721";
					reg = <0x0>;
					spi-max-frequency = <0x18cba80>;
					interrupts = <0x0 0x26 0x4>;
					interrupt-controller;
					#interrupt-cells = <0x2>;
					#address-cells = <0x1>;
					#size-cells = <0x0>;
					phandle = <0x57>;

					led-controller@180 {
						compatible = "sprd,sc27xx-bltc", "sprd,sc2721-bltc";
						#address-cells = <0x1>;
						#size-cells = <0x0>;
						reg = <0x180>;

						led@0 {
							label = "red";
							reg = <0x0>;
						};

						led@1 {
							label = "green";
							reg = <0x1>;
						};

						led@2 {
							label = "blue";
							reg = <0x2>;
						};
					};

					rtc@200 {
						compatible = "sprd,sc27xx-rtc", "sprd,sc2721-rtc";
						reg = <0x200>;
						interrupt-parent = <0x57>;
						interrupts = <0x1 0x4>;
					};

					gpio-controller@280 {
						compatible = "sprd,sc27xx-eic", "sprd,sc2721-eic";
						reg = <0x280>;
						interrupts = <0x4 0x4>;
						interrupt-parent = <0x57>;
						gpio-controller;
						#gpio-cells = <0x2>;
						interrupt-controller;
						#interrupt-cells = <0x2>;
						phandle = <0x5c>;
					};

					flash@2a8 {
						compatible = "sprd,sc27xx-flash", "sprd,sc2721-flash", "sprd,isink-flash";
						reg = <0x2a8>;
						status = "okay";
						phandle = <0x110>;
					};

					prox_kpled {
						compatible = "sprd,sc27xx-keypad-led", "sprd,prox-kpled";
						status = "okay";
					};

					efuse@300 {
						compatible = "sprd,sc27xx-efuse", "sprd,sc2721-efuse";
						reg = <0x300>;
						#address-cells = <0x1>;
						#size-cells = <0x1>;
						hwlocks = <0x40 0xc>;

						calib@6 {
							reg = <0x6 0x2>;
							phandle = <0x5d>;
						};

						calib@24 {
							reg = <0x24 0x2>;
							phandle = <0x5a>;
						};

						calib@26 {
							reg = <0x26 0x2>;
							phandle = <0x5b>;
						};

						calib@1a {
							reg = <0x1a 0x2>;
							phandle = <0x58>;
						};

						calib@0 {
							reg = <0x0 0x2>;
							phandle = <0xc8>;
						};

						calib@28 {
							reg = <0x28 0x2>;
							phandle = <0xc9>;
						};

						calib@2c {
							reg = <0x2c 0x2>;
							phandle = <0xca>;
						};
					};

					typec@380 {
						compatible = "sprd,sc27xx-typec", "sprd,sc2721-typec";
						interrupt-parent = <0x57>;
						interrupts = <0xa 0x4>;
						reg = <0x380>;
						mode = <0x2>;
						nvmem-cells = <0x58>;
						nvmem-cell-names = "cc_calib";
						status = "okay";
						phandle = <0x1e>;
					};

					adc@400 {
						compatible = "sprd,sc27xx-adc", "sprd,sc2721-adc";
						reg = <0x400>;
						verf-supply = <0x59>;
						interrupt-parent = <0x57>;
						interrupts = <0x0 0x4>;
						#io-channel-cells = <0x1>;
						hwlocks = <0x40 0x4>;
						nvmem-cells = <0x5a 0x5b>;
						nvmem-cell-names = "big_scale_calib", "small_scale_calib";
						phandle = <0x22>;
					};

					fgu@a00 {
						compatible = "sprd,sc27xx-fgu", "sprd,sc2720-fgu", "sprd,sc2721-fgu";
						reg = <0xa00>;
						bat-detect-gpio = <0x5c 0x9 0x0>;
						nvmem-cell-names = "fgu_calib";
						nvmem-cells = <0x5d>;
						io-channels = <0x22 0x0 0x22 0xe>;
						io-channel-names = "bat-temp", "charge-vol";
						interrupt-parent = <0x57>;
						interrupts = <0x3 0x4>;
						monitored-battery = <0x1a>;
						sprd,calib-resistance-real = <0x4dbc>;
						sprd,calib-resistance-spec = <0x4e20>;
						first-calib-voltage = <0x36a060>;
						first-calib-capacity = <0x28>;
						phandle = <0x111>;
					};

					syscon@c00 {
						compatible = "sprd,sc27xx-syscon";
						reg = <0xc00 0xecc 0xec0>;
					};

					audio-codec@700 {
						compatible = "sprd,sc2721-audio-codec", "sprd,sc27xx-audio-codec";
						#sound-dai-cells = <0x1>;
						reg = <0x700>;
						interrupts = <0x6 0x0>;
						sprd,syscon-pmu-apb = <0x7>;
						status = "okay";
						digital-codec = <0x5e>;
						phandle = <0xce>;
					};

					power-controller@c00 {
						compatible = "sprd,sc27xx-regulator", "sprd,sc2721-regulator";

						DCDC_CPU {
							regulator-name = "vddcpu";
							regulator-min-microvolt = <0x61a80>;
							regulator-max-microvolt = <0x1e74e0>;
							regulator-ramp-delay = <0x61a8>;
							regulator-always-on;
							phandle = <0xa1>;
						};

						DCDC_CORE {
							regulator-name = "vddcore";
							regulator-min-microvolt = <0x61a80>;
							regulator-max-microvolt = <0x1e74e0>;
							regulator-ramp-delay = <0x61a8>;
							regulator-always-on;
							phandle = <0x112>;
						};

						DCDC_MEM {
							regulator-name = "vddmem";
							regulator-min-microvolt = <0x61a80>;
							regulator-max-microvolt = <0x36e24b>;
							regulator-ramp-delay = <0x61a8>;
							regulator-always-on;
							phandle = <0x113>;
						};

						DCDC_GEN {
							regulator-name = "vddgen";
							regulator-min-microvolt = <0x927c0>;
							regulator-max-microvolt = <0x39ef8b>;
							regulator-ramp-delay = <0x61a8>;
							regulator-always-on;
							phandle = <0x114>;
						};

						LDO_VDDCAMA {
							regulator-name = "vddcama";
							regulator-min-microvolt = <0x124f80>;
							regulator-max-microvolt = <0x393870>;
							regulator-ramp-delay = <0x61a8>;
							phandle = <0xe>;
						};

						LDO_VDDCAMMOT {
							regulator-name = "vddcammot";
							regulator-min-microvolt = <0x124f80>;
							regulator-max-microvolt = <0x393870>;
							regulator-ramp-delay = <0x61a8>;
							phandle = <0x10>;
						};

						LDO_VDDSIM2 {
							regulator-name = "vddsim2";
							regulator-min-microvolt = <0x124f80>;
							regulator-max-microvolt = <0x393870>;
							regulator-ramp-delay = <0x61a8>;
							status = "disabled";
							phandle = <0x115>;
						};

						LDO_VDDEMMCCORE {
							regulator-name = "vddemmccore";
							regulator-min-microvolt = <0x124f80>;
							regulator-max-microvolt = <0x393870>;
							regulator-ramp-delay = <0x61a8>;
							phandle = <0x25>;
						};

						LDO_VDDSDCORE {
							regulator-name = "vddsdcore";
							regulator-min-microvolt = <0x124f80>;
							regulator-max-microvolt = <0x393870>;
							regulator-ramp-delay = <0x61a8>;
							phandle = <0x26>;
						};

						LDO_VDDSDIO {
							regulator-name = "vddsdio";
							regulator-min-microvolt = <0x124f80>;
							regulator-max-microvolt = <0x393870>;
							regulator-ramp-delay = <0x61a8>;
							phandle = <0x27>;
						};

						LDO_VDD28 {
							regulator-name = "vdd28";
							regulator-min-microvolt = <0x124f80>;
							regulator-max-microvolt = <0x393870>;
							regulator-ramp-delay = <0x61a8>;
							regulator-always-on;
							phandle = <0x59>;
						};

						LDO_VDDWIFIPA {
							regulator-name = "vddwifipa";
							regulator-min-microvolt = <0x124f80>;
							regulator-max-microvolt = <0x393870>;
							regulator-ramp-delay = <0x61a8>;
							phandle = <0xc2>;
						};

						LDO_VDDDCXO {
							regulator-name = "vdddcxo";
							regulator-min-microvolt = <0x124f80>;
							regulator-max-microvolt = <0x393870>;
							regulator-ramp-delay = <0x61a8>;
							regulator-always-on;
							phandle = <0x116>;
						};

						LDO_VDDUSB33 {
							regulator-name = "vddusb33";
							regulator-min-microvolt = <0x124f80>;
							regulator-max-microvolt = <0x393870>;
							regulator-ramp-delay = <0x61a8>;
							phandle = <0x23>;
						};

						LDO_VDDCAMD {
							regulator-name = "vddcamd";
							regulator-min-microvolt = <0xf5aaa>;
							regulator-max-microvolt = <0x16e360>;
							regulator-ramp-delay = <0x61a8>;
							phandle = <0xf>;
						};

						LDO_VDDCON {
							regulator-name = "vddcon";
							regulator-min-microvolt = <0x10e14a>;
							regulator-max-microvolt = <0x186a00>;
							regulator-ramp-delay = <0x61a8>;
							phandle = <0xc1>;
						};

						LDO_VDDCAMIO {
							regulator-name = "vddcamio";
							regulator-min-microvolt = <0x10e14a>;
							regulator-max-microvolt = <0x1cfde0>;
							regulator-ramp-delay = <0x61a8>;
							phandle = <0xd>;
						};

						LDO_VDD18 {
							regulator-name = "vdd18";
							regulator-min-microvolt = <0x10e14a>;
							regulator-max-microvolt = <0x1cfde0>;
							regulator-ramp-delay = <0x61a8>;
							regulator-always-on;
							phandle = <0x117>;
						};

						LDO_VDDRF18 {
							regulator-name = "vddrf18";
							regulator-min-microvolt = <0x10e14a>;
							regulator-max-microvolt = <0x1cfde0>;
							regulator-ramp-delay = <0x61a8>;
							regulator-always-on;
							phandle = <0x118>;
						};

						LDO_VDDRF125 {
							regulator-name = "vddrf125";
							regulator-min-microvolt = <0x10e14a>;
							regulator-max-microvolt = <0x155cc0>;
							regulator-ramp-delay = <0x61a8>;
							regulator-always-on;
							phandle = <0x119>;
						};

						LDO_VDDLDOMEM {
							regulator-name = "vddldomem";
							regulator-min-microvolt = <0x10e14a>;
							regulator-max-microvolt = <0x155cc0>;
							regulator-ramp-delay = <0x61a8>;
							regulator-always-on;
							phandle = <0x11a>;
						};

						LDO_VDDKPLED {
							regulator-name = "vddkpled";
							regulator-min-microvolt = <0x124f80>;
							regulator-max-microvolt = <0x393870>;
							regulator-ramp-delay = <0x61a8>;
							phandle = <0x11b>;
						};
					};

					poweroff@c20 {
						compatible = "sprd,sc27xx-poweroff", "sprd,sc2721-poweroff";
						reg = <0xc20>;
					};

					vibrator@eb4 {
						compatible = "sprd,sc27xx-vibrator", "sprd,sc2721-vibrator";
						reg = <0xeb4>;
					};

					hw_reset@eec {
						compatible = "sprd,sc27xx-7sreset", "sprd,sc2721-7sreset";
						reg = <0xf1c 0xeec>;
					};

					charger@ec0 {
						compatible = "sprd,sc27xx-charger", "sprd,sc2721-charger";
						reg = <0xec0>;
						nvmem-cell-names = "cccv_calib";
						nvmem-cells = <0x58>;
						status = "okay";
						phys = <0x19>;
						monitored-battery = <0x1a>;
						phandle = <0x11c>;
					};
				};
			};
		};

		mm {
			compatible = "simple-bus";
			#address-cells = <0x1>;
			#size-cells = <0x1>;
			ranges;

			cam-domain {
				compatible = "sprd,cam-domain";
				syscons = <0x7 0x1c 0x1000000 0x7 0x1c 0x2000000 0x7 0xbc 0xf8000000 0x7 0x6ec 0x80000 0x2 0x50 0x1f3f8>;
				syscon-names = "shutdown_en", "force_shutdown", "pwr_status0", "bus_status0", "init_dis_bits";
				clock-names = "clk_cphy_cfg_gate_eb", "clk_mm_eb", "clk_mm_ahb", "clk_mm_ahb_parent", "clk_mm_emc", "clk_mm_emc_parent";
				clocks = <0x5 0x66 0x5 0x19 0xb 0x2a 0x6 0xf 0xb 0x29 0x6 0x8>;
				phandle = <0x11d>;
			};

			gpu@60000000 {
				compatible = "sprd,rogue";
				reg = <0x60000000 0x100000>;
				syscons = <0x7 0x20 0x2000000 0x7 0x124 0x2000000 0x7 0x124 0x1000000>;
				syscon-names = "top_force_shutdown", "core_force_shutdown", "core_auto_shutdown";
				interrupts = <0x0 0x27 0x4>;
				operating-points = <0x3e800 0x0 0x5dc00 0x0 0x86470 0x0>;
				sprd,dvfs-lists = <0x3e800 0x0 0x5 0x1 0x5dc00 0x0 0x7 0x1 0x86470 0x0 0x9 0x1>;
				sprd,dvfs-default = <0x0>;
				sprd,dvfs-scene-extreme = <0x2>;
				sprd,dvfs-scene-high = <0x1>;
				sprd,dvfs-scene-medium = <0x1>;
				sprd,dvfs-scene-low = <0x0>;
				sprd,dvfs-range-max = <0x2>;
				sprd,dvfs-range-min = <0x0>;
				clocks = <0x5 0x4c 0xb 0x27 0xb 0x28 0x6 0xf 0x6 0x3 0x6 0x9 0x6 0xc 0x6 0x2 0x6 0x8 0x6 0x17>;
				phandle = <0x11e>;
			};

			dpu@63000000 {
				compatible = "sprd,display-processor";
				reg = <0x63000000 0x1000>;
				interrupts = <0x0 0x2e 0x4>;
				status = "okay";
				iommus = <0x5f>;
				power-domains = <0x60>;
				dma-coherent;
				sprd,ip = "dpu-r2p0";
				sprd,soc = "sharkl3";
				sprd,logo-memory = <0x61>;
				syscons = <0x2 0xc 0x100000>;
				syscon-names = "reset";
				clock-names = "clk_src_128m", "clk_src_153m6", "clk_src_192m", "clk_src_256m", "clk_src_384m", "clk_dpu_core", "clk_dpu_dpi", "clk_aon_apb_disp_eb";
				clocks = <0x6 0xa 0x6 0xf 0x6 0x3 0x6 0x9 0x6 0x2 0xb 0x22 0xb 0x23 0x5 0x4d>;
				phandle = <0x11f>;

				port {
					phandle = <0xd8>;

					endpoint {
						remote-endpoint = <0x62>;
						phandle = <0x68>;
					};
				};
			};

			gsp@63000000 {
				compatible = "sprd,gsp-core";
				reg = <0x63000000 0x2000>;
				core-id = <0x0>;
				kcfg-num = <0x10>;
				interrupts = <0x0 0x33 0x4>;
				iommus = <0x5f>;
				clock-names = "clk_dpu_core_src", "clk_dpu_core", "clk_aon_apb_disp_eb";
				clocks = <0x6 0x2 0xb 0x22 0x5 0x4d>;
				phandle = <0xbc>;
			};

			iommu@63000000 {
				compatible = "sprd,iommuexl3-dispc";
				reg = <0x63000000 0x800 0x63000800 0x80>;
				iova-base = <0x30000000>;
				iova-size = <0x10000000>;
				reg_name = "mmu_interrupt_reg", "mmu_reg";
				status = "okay";
				#iommu-cells = <0x0>;
				phandle = <0x5f>;
			};

			video-codec@62200000 {
				compatible = "sprd,sharkl3-vsp";
				reg = <0x62200000 0xc000>;
				interrupts = <0x0 0x2b 0x4>;
				syscons = <0x63 0x4 0xc 0x7 0x30 0x2000000 0x7 0x30 0x1000000 0x7 0x128 0x1f 0x2 0x4 0x4000>;
				syscon-names = "reset", "pmu_vsp_force_shutdown", "pmu_vsp_auto_shutdown", "pmu_pwr_status", "vsp_domain_eb";
				iommus = <0x64>;
				status = "okay";
				clock-names = "clk_mm_eb", "clk_ahb_gate_vsp_eb", "clk_axi_gate_vsp", "clk_vsp_ahb_mmu_eb", "clk_ahb_vsp", "clk_ahb_vsp_parent", "clk_emc_vsp", "clk_emc_vsp_parent", "clk_src_76m8", "clk_src_128m", "clk_src_256m", "clk_src_307m2", "clk_src_384m", "clk_vsp";
				clocks = <0x5 0x2c 0x5 0x51 0x65 0x0 0x65 0x1 0xb 0x34 0x6 0xf 0xb 0x33 0x6 0x19 0x6 0x10 0x6 0xa 0x6 0x9 0x6 0xc 0x6 0x2 0xb 0x35>;
				phandle = <0x120>;
			};

			iommu@62201000 {
				compatible = "sprd,iommuexl3-vsp";
				reg = <0x62201000 0xb000 0x62200000 0x80>;
				iova-base = <0x20000000>;
				iova-size = <0x10000000>;
				reg_name = "mmu_interrupt_reg", "mmu_reg";
				status = "okay";
				#iommu-cells = <0x0>;
				phandle = <0x64>;
			};

			jpeg-codec@62300000 {
				compatible = "sprd,sharkl3-jpg";
				reg = <0x62300000 0x8000>;
				interrupts = <0x0 0x2a 0x4>;
				syscons = <0x63 0x4 0x20 0x2 0x0 0x2000000>;
				syscon-names = "reset", "aon_apb_eb";
				iommus = <0x66>;
				status = "okay";
				clock-names = "jpg_domain_eb", "clk_aon_jpg_emc_eb", "jpg_dev_eb", "jpg_ckg_eb", "clk_ahb_vsp", "clk_ahb_vsp_parent", "clk_emc_vsp", "clk_emc_vsp_parent", "clk_src_256m", "clk_src_307m2", "jpg_clk";
				clocks = <0x5 0x2c 0x5 0x51 0x65 0x0 0x65 0x2 0xb 0x34 0x6 0xf 0xb 0x33 0x6 0x19 0x6 0x9 0x6 0xc 0xb 0x2e>;
				phandle = <0x121>;
			};

			iommu@62300000 {
				compatible = "sprd,iommuexl3-jpg";
				reg = <0x62300000 0x300 0x62300300 0x400>;
				iova-base = <0x70000000>;
				iova-size = <0x10000000>;
				reg_name = "mmu_interrupt_reg", "mmu_reg";
				status = "okay";
				#iommu-cells = <0x0>;
				phandle = <0x66>;
			};

			dsi@63100000 {
				compatible = "sprd,dsi-host";
				reg = <0x63100000 0x1000>;
				interrupts = <0x0 0x30 0x4 0x0 0x31 0x4>;
				status = "okay";
				power-domains = <0x60>;
				sprd,ip = "sprd,dsi-ctrl", "r3p0";
				sprd,soc = "sharkl3";
				syscons = <0x2 0x628 0x4>;
				syscon-names = "reset";
				clock-names = "clk_aon_apb_disp_eb";
				clocks = <0x5 0x4d>;
				#address-cells = <0x1>;
				#size-cells = <0x0>;
				phandle = <0x122>;

				ports {
					#address-cells = <0x1>;
					#size-cells = <0x0>;

					port@0 {
						reg = <0x0>;

						endpoint {
							remote-endpoint = <0x67>;
							phandle = <0x6b>;
						};
					};

					port@1 {
						reg = <0x1>;

						endpoint {
							remote-endpoint = <0x68>;
							phandle = <0x62>;
						};
					};
				};

				panel {
					compatible = "sprd,generic-mipi-panel";
					#address-cells = <0x1>;
					#size-cells = <0x0>;
					reg = <0x0>;
					avdd-gpio = <0x12 0x4 0x0>;
					avee-gpio = <0x12 0x5 0x0>;
					reset-gpio = <0x12 0x32 0x0>;
					phandle = <0x123>;

					port {
						reg = <0x1>;

						endpoint {
							remote-endpoint = <0x69>;
							phandle = <0x6a>;
						};
					};
				};
			};

			dphy {
				compatible = "sprd,dsi-phy";
				#address-cells = <0x1>;
				#size-cells = <0x0>;
				reg = <0x63100000 0x1000>;
				status = "okay";
				sprd,ip = "sprd,megacores-sharkle";
				sprd,soc = "sharkl3";
				syscons = <0x2 0xb0 0x1800000 0x2 0x24 0x8000 0x2 0x24 0x4000 0x2 0x24 0x8000000>;
				syscon-names = "enable", "power_small", "power_large", "power_iso";
				sprd,ulps-disabled;
				phandle = <0x124>;

				port@0 {
					reg = <0x0>;

					endpoint {
						remote-endpoint = <0x6a>;
						phandle = <0x69>;
					};
				};

				port@1 {
					reg = <0x1>;

					endpoint {
						remote-endpoint = <0x6b>;
						phandle = <0x67>;
					};
				};
			};

			mipi-csi-phy0 {
				compatible = "sprd,mipi-csi-phy";
				sprd,phyid = <0x0>;
				sprd,phyname = "2p2";
				status = "disabled";
				phandle = <0x125>;
			};

			mipi-csi-phy1 {
				compatible = "sprd,mipi-csi-phy";
				sprd,phyid = <0x1>;
				sprd,phyname = "4lane";
				status = "disabled";
				phandle = <0x126>;
			};

			mipi-csi-phy2 {
				compatible = "sprd,mipi-csi-phy";
				sprd,phyid = <0x2>;
				sprd,phyname = "2lane";
				status = "disabled";
				phandle = <0x127>;
			};

			mipi-csi-phy0-s {
				compatible = "sprd,mipi-csi-phy";
				sprd,phyid = <0x3>;
				sprd,phyname = "2p2_m";
				status = "disabled";
				phandle = <0x128>;
			};

			mipi-csi-phy0-m {
				compatible = "sprd,mipi-csi-phy";
				sprd,phyid = <0x4>;
				sprd,phyname = "2p2_s";
				status = "disabled";
				phandle = <0x129>;
			};

			mipi-csi-phy0-m1 {
				compatible = "sprd,mipi-csi-phy";
				sprd,phyid = <0x4>;
				sprd,phyname = "2p2_s";
				status = "disabled";
				phandle = <0x12a>;
			};

			dcam@60a00000 {
				compatible = "sprd,sharkl3-cam";
				reg = <0x60a00000 0x1000 0x60a01000 0x1000 0x60a02000 0x1000 0x60a03000 0x1000>;
				reg_name = "dcam0_reg", "dcam1_reg", "dcam2_reg", "axi_ctrl_reg";
				interrupts = <0x0 0x2d 0x4 0x0 0x9e 0x4 0x0 0x9f 0x4>;
				interrupts_name = "dcam0", "dcam1", "dcam2";
				syscons = <0x6c 0x4 0x40 0x6c 0x4 0x4 0x6c 0x4 0x8 0x6c 0x4 0x10>;
				syscon-names = "dcam_all_reset", "dcam0_reset", "dcam1_reset", "dcam2_reset";
				sprd,aon-apb-syscon = <0x2>;
				sprd,cam-ahb-syscon = <0x6c>;
				sprd,isp = <0x6d>;
				sprd,dcam-count = <0x3>;
				sprd,project-id = <0x0>;
				iommus = <0x6e>;
				status = "okay";
				clock-names = "dcam_eb", "dcam_axi_eb", "clk_cphy_cfg_gate_eb", "clk_mm_eb", "clk_mm_ahb", "clk_mm_ahb_parent", "clk_mm_emc", "clk_mm_emc_parent", "dcam_clk", "dcam_clk_256m", "dcam_clk_307m2", "dcam_clk_384m", "dcam_clk_parent", "dcam_bpc_clk", "dcam_bpc_clk_parent";
				clocks = <0xc 0x1 0xc 0x6 0x5 0x66 0x5 0x19 0xb 0x2a 0x6 0xf 0xb 0x29 0x6 0x8 0xb 0x2c 0x6 0x9 0x6 0xc 0x6 0x2 0x6 0x2 0xb 0x2b 0x6f 0x3>;
				phandle = <0x12b>;
			};

			iommu@60a00040 {
				compatible = "sprd,iommuexl3-dcam";
				reg = <0x60a00000 0xc000 0x60a0c000 0x60>;
				iova-base = <0x40000000>;
				iova-size = <0x20000000>;
				reg_name = "mmu_interrupt_reg", "mmu_reg", "iova pool";
				status = "okay";
				#iommu-cells = <0x0>;
				phandle = <0x6e>;
			};

			isp@60b00000 {
				compatible = "sprd,isp";
				reg = <0x60b00000 0x100000>;
				interrupts = <0x0 0x2c 0x4 0x0 0x7d 0x4>;
				interrupts_name = "ch0", "ch1";
				syscons = <0x6c 0x4 0x80>;
				syscon-names = "reset";
				sprd,cam-ahb-syscon = <0x6c>;
				sprd,isp-count = <0x1>;
				iommus = <0x70>;
				status = "okay";
				clock-names = "isp_eb", "isp_axi_eb", "isp_clk", "isp_clk_128m", "isp_clk_256m", "isp_clk_307m2", "isp_clk_384m", "isp_clk_468m", "isp_clk_parent";
				clocks = <0xc 0x2 0xc 0x7 0xb 0x2d 0x6 0xa 0x6 0x9 0x6 0xc 0x6 0x2 0x6 0x19 0x6 0x19>;
				phandle = <0x6d>;
			};

			iommu@60b00000 {
				compatible = "sprd,iommuexl3-isp";
				reg = <0x60b00000 0xffc00 0x60bffc00 0x400>;
				iova-base = <0x50000000>;
				iova-size = <0x20000000>;
				reg_name = "mmu_interrupt_reg", "mmu_reg", "iova pool";
				status = "okay";
				#iommu-cells = <0x0>;
				phandle = <0x70>;
			};

			csi@60c00000 {
				compatible = "sprd,csi-controller";
				reg = <0x60c00000 0x1000>;
				interrupts = <0x0 0x28 0x4 0x0 0x29 0x4>;
				sprd,aon-apb-syscon = <0x2>;
				sprd,cam-ahb-syscon = <0x6c>;
				sprd,anlg_phy_g1_controller = <0x3>;
				sprd,csi-id = <0x0>;
				sprd,dcam-id = <0x0>;
				sprd,ip-version = <0x200>;
				status = "okay";
				clock-names = "clk_mipi_csi_gate_eb", "clk_csi_eb", "mipi_csi_src_eb", "clk_gate_eb";
				clocks = <0xc 0x8 0xc 0x3 0x71 0x0 0xc 0x0>;
				phandle = <0x11>;
			};

			csi@60d00000 {
				compatible = "sprd,csi-controller";
				reg = <0x60d00000 0x1000>;
				interrupts = <0x0 0x47 0x4 0x0 0x48 0x4>;
				sprd,aon-apb-syscon = <0x2>;
				sprd,cam-ahb-syscon = <0x6c>;
				sprd,anlg_phy_g1_controller = <0x3>;
				sprd,csi-id = <0x1>;
				sprd,dcam-id = <0x1>;
				sprd,ip-version = <0x200>;
				status = "okay";
				clock-names = "clk_mipi_csi_gate_eb", "clk_csi_eb", "mipi_csi_src_eb", "clk_gate_eb";
				clocks = <0xc 0x9 0xc 0x4 0x71 0x1 0xc 0x0>;
				phandle = <0x13>;
			};

			csi@60e00000 {
				compatible = "sprd,csi-controller";
				reg = <0x60e00000 0x1000>;
				interrupts = <0x0 0x9c 0x4 0x0 0x9d 0x4>;
				sprd,aon-apb-syscon = <0x2>;
				sprd,cam-ahb-syscon = <0x6c>;
				sprd,anlg_phy_g1_controller = <0x3>;
				sprd,csi-id = <0x2>;
				sprd,dcam-id = <0x2>;
				sprd,ip-version = <0x200>;
				status = "okay";
				clock-names = "clk_mipi_csi_gate_eb", "clk_csi_eb", "mipi_csi_src_eb", "clk_gate_eb";
				clocks = <0xc 0xa 0xc 0x5 0x71 0x2 0xc 0x0>;
				phandle = <0x12c>;
			};

			cpp@62400000 {
				compatible = "sprd,cpp";
				reg = <0x62400000 0x1000>;
				interrupts = <0x0 0x7e 0x4>;
				syscons = <0x63 0x4 0x3c0 0x63 0x4 0x80 0x63 0x4 0x100 0x63 0x4 0x200>;
				syscon-names = "cpp_rst", "path0_rst", "path1_rst", "dma_rst";
				iommus = <0x72>;
				status = "okay";
				clock-names = "cpp_eb", "cpp_clk", "cpp_clk_parent", "clk_mm_vsp_eb", "clk_mm_vsp_emc", "clk_mm_vsp_emc_parent";
				clocks = <0x65 0x3 0xb 0x2f 0x6 0xc 0x5 0x2c 0xb 0x33 0x6 0x19>;
				phandle = <0x12d>;
			};

			iommu@62400000 {
				compatible = "sprd,iommuexl3-cpp";
				reg = <0x62400000 0x200 0x62400200 0x60>;
				iova-base = <0x60000000>;
				iova-size = <0x8000000>;
				reg_name = "mmu_interrupt_reg", "mmu_reg", "iova pool";
				status = "okay";
				#iommu-cells = <0x0>;
				phandle = <0x72>;
			};
		};

		pub {
			compatible = "simple-bus";
			#address-cells = <0x2>;
			#size-cells = <0x2>;
			ranges;

			dmc-controller@30000000 {
				compatible = "sprd,sharkl3-dmc";
				reg = <0x0 0x30000000 0x0 0x1000>;
				phandle = <0x12e>;
			};

			ptm@30010000 {
				compatible = "sprd,sharkl3-ptm";
				reg = <0x0 0x30010000 0x0 0x10000 0x0 0x10001000 0x0 0x1000 0x0 0x10003000 0x0 0x1000 0x0 0x10004000 0x0 0x1000>;
				interrupts = <0x0 0x56 0x4>;
				clock-names = "clk_cs", "cs_src";
				clocks = <0xb 0x18 0x6 0xf>;
				sprd,funnel-port = <0x2>;
				sprd,ddr-chn = <0x8>;
				sprd,chn-name = "MM", "GPU", "DPU", "CPU", "AP/PUBCP", "WTLCP", "WCN/AON/ETR", "VSP";
				phandle = <0x12f>;
			};

			dmc-mpu@300e0000 {
				compatible = "sprd,sharkl3-dmc-mpu";
				reg = <0x0 0x300e0000 0x0 0x10000>;
				interrupts = <0x0 0x3d 0x4>;
				syscon-names = "irq_clr", "irq_en";
				syscons = <0x73 0x40 0x2 0x73 0x40 0x1>;
				sprd,channel-num = <0x8>;
				sprd,mpu-num = <0x10>;
				sprd,channel-names = "MM", "GPU", "DPU", "CPU", "AP/PUBCP", "WTLCP", "AON/WCN/ETR", "VSP", "SHARED0", "SHARED1", "SHARED2", "SHARED3", "SHARED4", "SHARED5", "SHARED6", "SHARED7";
				sprd,ranges = <0x0 0x0 0x0 0x0 0x0 0x0 0x0 0x0 0x0 0x0 0x0 0x0 0x0 0x0 0x0 0x0 0x0 0x0 0x0 0x0 0x0 0x0 0x0 0x0 0x0 0x0 0x0 0x0 0x0 0x0 0x0 0x0 0x0 0x0 0x0 0x0 0x0 0x0 0x0 0x0 0x0 0x0 0x0 0x0 0x0 0x0 0x0 0x0 0x0 0x0 0x0 0x0 0x0 0x0 0x0 0x0 0x0 0x0 0x0 0x0 0x0 0x0 0x0 0x0>;
				sprd,chn-config = <0x0 0x1 0x1 0x0 0x1 0x1 0x0 0x1 0x1 0x0 0x1 0x1 0x0 0x1 0x1 0x0 0x1 0x1 0x0 0x1 0x1 0x0 0x1 0x1 0x0 0x1 0x1 0x0 0x1 0x1 0x0 0x1 0x1 0x0 0x1 0x1 0x0 0x1 0x1 0x0 0x1 0x1 0x0 0x1 0x1 0x0 0x1 0x1>;
				sprd,id-config = <0x0 0x0 0xffff 0x0 0x0 0xffff 0x0 0x0 0xffff 0x0 0x0 0xffff 0x0 0x0 0xffff 0x0 0x0 0xffff 0x0 0x0 0xffff 0x0 0x0 0xffff 0x0 0x0 0xffff 0x0 0x0 0xffff 0x0 0x0 0xffff 0x0 0x0 0xffff 0x0 0x0 0xffff 0x0 0x0 0xffff 0x0 0x0 0xffff 0x0 0x0 0xffff>;
				sprd,port-map = <0x0 0x1 0x2 0x3 0x4 0x5 0x6 0x7 0x0 0x0 0x0 0x0 0x0 0x0 0x0 0x0>;
				sprd,ddr-offset = <0x80000000>;
				status = "disabled";
				phandle = <0x130>;
			};
		};

		pmu-gate {
			compatible = "sprd,sc9863a-pmu-gate";
			sprd,syscon = <0x7>;
			clocks = <0xa>;
			#clock-cells = <0x1>;
			phandle = <0x74>;
		};

		pll {
			compatible = "sprd,sc9863a-pll";
			sprd,syscon = <0x4>;
			clocks = <0x74 0x0>;
			#clock-cells = <0x1>;
			phandle = <0x6>;
		};

		mpll {
			compatible = "sprd,sc9863a-mpll";
			sprd,syscon = <0x21>;
			clocks = <0x74 0x0>;
			#clock-cells = <0x1>;
			phandle = <0xa6>;
		};

		rpll {
			compatible = "sprd,sc9863a-rpll";
			sprd,syscon = <0x75>;
			clocks = <0x74 0x0>;
			#clock-cells = <0x1>;
			phandle = <0x24>;
		};

		dpll {
			compatible = "sprd,sc9863a-dpll";
			sprd,syscon = <0x29>;
			clocks = <0x74 0x0>;
			#clock-cells = <0x1>;
			phandle = <0x6f>;
		};

		clock-controller@21500000 {
			compatible = "sprd,sc9863a-ap-clk";
			reg = <0x0 0x21500000 0x0 0x1000>;
			clocks = <0x3f 0xa 0x6 0x0 0x24 0x0>;
			#clock-cells = <0x1>;
			phandle = <0x9>;
		};

		clock-controller@402d0000 {
			compatible = "sprd,sc9863a-aon-clk";
			reg = <0x0 0x402d0000 0x0 0x1000>;
			clocks = <0xa 0x6 0x0 0x24 0x0 0x6f 0x0>;
			#clock-cells = <0x1>;
			phandle = <0xb>;
		};

		apahb-gate {
			compatible = "sprd,sc9863a-apahb-gate";
			sprd,syscon = <0x20>;
			clocks = <0xb 0x1d>;
			#clock-cells = <0x1>;
			phandle = <0x1d>;
		};

		aonapb-gate {
			compatible = "sprd,sc9863a-aonapb-gate";
			sprd,syscon = <0x2>;
			clocks = <0xb 0x9>;
			#clock-cells = <0x1>;
			phandle = <0x5>;
		};

		clock-controller@60900000 {
			compatible = "sprd,sc9863a-mm-clk";
			reg = <0x0 0x60900000 0x0 0x1000>;
			clocks = <0xb 0x2a>;
			#clock-cells = <0x1>;
			phandle = <0x71>;
		};

		mm-gate {
			compatible = "sprd,sc9863a-mm-gate";
			sprd,syscon = <0x6c>;
			syscons = <0x2 0x0 0x2000000 0x7 0x1c 0x2000000>;
			syscon-names = "enable", "power";
			clocks = <0xb 0x2a>;
			#clock-cells = <0x1>;
			phandle = <0xc>;
		};

		vspahb-gate {
			compatible = "sprd,sc9863a-vspahb-gate";
			sprd,syscon = <0x63>;
			syscons = <0x2 0x4 0x4000 0x7 0x30 0x2000000>;
			syscon-names = "enable", "power";
			clocks = <0xb 0x2a>;
			#clock-cells = <0x1>;
			phandle = <0x65>;
		};

		apapb-gate {
			compatible = "sprd,sc9863a-apapb-gate";
			sprd,syscon = <0x1c>;
			clocks = <0xa>;
			#clock-cells = <0x1>;
			phandle = <0x8>;
		};

		funnel@10001000 {
			compatible = "arm,coresight-funnel", "arm,primecell";
			reg = <0x0 0x10001000 0x0 0x1000>;
			clocks = <0xa>;
			clock-names = "apb_pclk";

			ports {
				#address-cells = <0x1>;
				#size-cells = <0x0>;

				port@0 {
					reg = <0x0>;

					endpoint {
						remote-endpoint = <0x76>;
						phandle = <0x78>;
					};
				};

				port@1 {
					reg = <0x0>;

					endpoint {
						slave-mode;
						remote-endpoint = <0x77>;
						phandle = <0x82>;
					};
				};
			};
		};

		etb@10003000 {
			compatible = "arm,coresight-tmc", "arm,primecell";
			reg = <0x0 0x10003000 0x0 0x1000>;
			clocks = <0xa>;
			clock-names = "apb_pclk";

			port {

				endpoint {
					slave-mode;
					remote-endpoint = <0x78>;
					phandle = <0x76>;
				};
			};
		};

		funnel@12001000 {
			compatible = "arm,coresight-funnel", "arm,primecell";
			reg = <0x0 0x12001000 0x0 0x1000>;
			clocks = <0xa>;
			clock-names = "apb_pclk";

			ports {
				#address-cells = <0x1>;
				#size-cells = <0x0>;

				port@0 {
					reg = <0x0>;

					endpoint {
						remote-endpoint = <0x79>;
						phandle = <0x7f>;
					};
				};

				port@1 {
					reg = <0x0>;

					endpoint {
						slave-mode;
						remote-endpoint = <0x7a>;
						phandle = <0x8b>;
					};
				};

				port@2 {
					reg = <0x1>;

					endpoint {
						slave-mode;
						remote-endpoint = <0x7b>;
						phandle = <0x8d>;
					};
				};

				port@3 {
					reg = <0x2>;

					endpoint {
						slave-mode;
						remote-endpoint = <0x7c>;
						phandle = <0x8f>;
					};
				};

				port@4 {
					reg = <0x3>;

					endpoint {
						slave-mode;
						remote-endpoint = <0x7d>;
						phandle = <0x91>;
					};
				};
			};
		};

		etf@12002000 {
			compatible = "arm,coresight-tmc", "arm,primecell";
			reg = <0x0 0x12002000 0x0 0x1000>;
			clocks = <0xa>;
			clock-names = "apb_pclk";

			port@0 {

				endpoint {
					remote-endpoint = <0x7e>;
					phandle = <0x83>;
				};
			};

			port@1 {

				endpoint {
					slave-mode;
					remote-endpoint = <0x7f>;
					phandle = <0x79>;
				};
			};
		};

		etf@12003000 {
			compatible = "arm,coresight-tmc", "arm,primecell";
			reg = <0x0 0x12003000 0x0 0x1000>;
			clocks = <0xa>;
			clock-names = "apb_pclk";

			port@0 {

				endpoint {
					remote-endpoint = <0x80>;
					phandle = <0x84>;
				};
			};

			port@1 {

				endpoint {
					slave-mode;
					remote-endpoint = <0x81>;
					phandle = <0x85>;
				};
			};
		};

		funnel@12004000 {
			compatible = "arm,coresight-funnel", "arm,primecell";
			reg = <0x0 0x12004000 0x0 0x1000>;
			clocks = <0xa>;
			clock-names = "apb_pclk";

			ports {
				#address-cells = <0x1>;
				#size-cells = <0x0>;

				port@0 {
					reg = <0x0>;

					endpoint {
						remote-endpoint = <0x82>;
						phandle = <0x77>;
					};
				};

				port@1 {
					reg = <0x0>;

					endpoint {
						slave-mode;
						remote-endpoint = <0x83>;
						phandle = <0x7e>;
					};
				};

				port@2 {
					reg = <0x1>;

					endpoint {
						slave-mode;
						remote-endpoint = <0x84>;
						phandle = <0x80>;
					};
				};
			};
		};

		funnel@12005000 {
			compatible = "arm,coresight-funnel", "arm,primecell";
			reg = <0x0 0x12005000 0x0 0x1000>;
			clocks = <0xa>;
			clock-names = "apb_pclk";

			ports {
				#address-cells = <0x1>;
				#size-cells = <0x0>;

				port@0 {
					reg = <0x0>;

					endpoint {
						remote-endpoint = <0x85>;
						phandle = <0x81>;
					};
				};

				port@1 {
					reg = <0x0>;

					endpoint {
						slave-mode;
						remote-endpoint = <0x86>;
						phandle = <0x93>;
					};
				};

				port@2 {
					reg = <0x1>;

					endpoint {
						slave-mode;
						remote-endpoint = <0x87>;
						phandle = <0x95>;
					};
				};

				port@3 {
					reg = <0x2>;

					endpoint {
						slave-mode;
						remote-endpoint = <0x88>;
						phandle = <0x97>;
					};
				};

				port@4 {
					reg = <0x3>;

					endpoint {
						slave-mode;
						remote-endpoint = <0x89>;
						phandle = <0x99>;
					};
				};
			};
		};

		etm@13040000 {
			compatible = "arm,coresight-etm4x", "arm,primecell";
			reg = <0x0 0x13040000 0x0 0x1000>;
			cpu = <0x8a>;
			clocks = <0xa>;
			clock-names = "apb_pclk";

			port {

				endpoint {
					remote-endpoint = <0x8b>;
					phandle = <0x7a>;
				};
			};
		};

		etm@13140000 {
			compatible = "arm,coresight-etm4x", "arm,primecell";
			reg = <0x0 0x13140000 0x0 0x1000>;
			cpu = <0x8c>;
			clocks = <0xa>;
			clock-names = "apb_pclk";

			port {

				endpoint {
					remote-endpoint = <0x8d>;
					phandle = <0x7b>;
				};
			};
		};

		etm@13240000 {
			compatible = "arm,coresight-etm4x", "arm,primecell";
			reg = <0x0 0x13240000 0x0 0x1000>;
			cpu = <0x8e>;
			clocks = <0xa>;
			clock-names = "apb_pclk";

			port {

				endpoint {
					remote-endpoint = <0x8f>;
					phandle = <0x7c>;
				};
			};
		};

		etm@13340000 {
			compatible = "arm,coresight-etm4x", "arm,primecell";
			reg = <0x0 0x13340000 0x0 0x1000>;
			cpu = <0x90>;
			clocks = <0xa>;
			clock-names = "apb_pclk";

			port {

				endpoint {
					remote-endpoint = <0x91>;
					phandle = <0x7d>;
				};
			};
		};

		etm@13440000 {
			compatible = "arm,coresight-etm4x", "arm,primecell";
			reg = <0x0 0x13440000 0x0 0x1000>;
			cpu = <0x92>;
			clocks = <0xa>;
			clock-names = "apb_pclk";

			port {

				endpoint {
					remote-endpoint = <0x93>;
					phandle = <0x86>;
				};
			};
		};

		etm@13540000 {
			compatible = "arm,coresight-etm4x", "arm,primecell";
			reg = <0x0 0x13540000 0x0 0x1000>;
			cpu = <0x94>;
			clocks = <0xa>;
			clock-names = "apb_pclk";

			port {

				endpoint {
					remote-endpoint = <0x95>;
					phandle = <0x87>;
				};
			};
		};

		etm@13640000 {
			compatible = "arm,coresight-etm4x", "arm,primecell";
			reg = <0x0 0x13640000 0x0 0x1000>;
			cpu = <0x96>;
			clocks = <0xa>;
			clock-names = "apb_pclk";

			port {

				endpoint {
					remote-endpoint = <0x97>;
					phandle = <0x88>;
				};
			};
		};

		etm@13740000 {
			compatible = "arm,coresight-etm4x", "arm,primecell";
			reg = <0x0 0x13740000 0x0 0x1000>;
			cpu = <0x98>;
			clocks = <0xa>;
			clock-names = "apb_pclk";

			port {

				endpoint {
					remote-endpoint = <0x99>;
					phandle = <0x89>;
				};
			};
		};
	};

	ext-26m {
		compatible = "fixed-clock";
		#clock-cells = <0x0>;
		clock-frequency = <0x18cba80>;
		clock-output-names = "ext-26m";
		phandle = <0xa>;
	};

	ext-13m {
		compatible = "fixed-clock";
		#clock-cells = <0x0>;
		clock-frequency = <0xc65d40>;
		clock-output-names = "ext_13m";
		phandle = <0x131>;
	};

	ext-6m5 {
		compatible = "fixed-clock";
		#clock-cells = <0x0>;
		clock-frequency = <0x632ea0>;
		clock-output-names = "ext_6m5";
		phandle = <0x132>;
	};

	ext-4m3 {
		compatible = "fixed-clock";
		#clock-cells = <0x0>;
		clock-frequency = <0x419ce0>;
		clock-output-names = "ext_4m3";
		phandle = <0x133>;
	};

	ext-4m {
		compatible = "fixed-clock";
		#clock-cells = <0x0>;
		clock-frequency = <0x3d0900>;
		clock-output-names = "ext_4m";
		phandle = <0x134>;
	};

	ext-250k {
		compatible = "fixed-clock";
		#clock-cells = <0x0>;
		clock-frequency = <0x3d090>;
		clock-output-names = "ext_250k";
		phandle = <0x135>;
	};

	ext-32k {
		compatible = "fixed-clock";
		#clock-cells = <0x0>;
		clock-frequency = <0x8000>;
		clock-output-names = "ext_32k";
		phandle = <0x3f>;
	};

	ext-1k {
		compatible = "fixed-clock";
		#clock-cells = <0x0>;
		clock-frequency = <0x400>;
		clock-output-names = "ext_1k";
		phandle = <0x3e>;
	};

	ext-1m {
		compatible = "fixed-clock";
		#clock-cells = <0x0>;
		clock-frequency = <0xf4240>;
		clock-output-names = "ext_1m";
		phandle = <0x136>;
	};

	ext-2m {
		compatible = "fixed-clock";
		#clock-cells = <0x0>;
		clock-frequency = <0x1e8480>;
		clock-output-names = "ext_2m";
		phandle = <0x137>;
	};

	ext-rc0-4m {
		compatible = "fixed-clock";
		#clock-cells = <0x0>;
		clock-frequency = <0x3d0900>;
		clock-output-names = "ext_rc0_4m";
		phandle = <0x138>;
	};

	clk-pad {
		compatible = "fixed-clock";
		#clock-cells = <0x0>;
		clock-frequency = <0x3d09000>;
		clock-output-names = "clk_pad";
		phandle = <0x139>;
	};

	rco-100m {
		compatible = "fixed-clock";
		#clock-cells = <0x0>;
		clock-frequency = <0x5f5e100>;
		clock-output-names = "rco-100m";
		phandle = <0x13a>;
	};

	sprd-pcm-audio {
		compatible = "sprd,sharkl3-pcm-platform";
		#sound-dai-cells = <0x0>;
		dmas = <0x9a 0x1 0x9a 0x2 0x9a 0x3 0x9a 0x4 0x9a 0x5 0x9a 0x6 0x9a 0x7 0x9a 0x8 0x9a 0x5 0x9a 0x6>;
		dma-names = "da01-l", "da01-r", "da23-l", "da23-r", "normal-2stage-p", "normal-2stage-c", "deep-2stage-p", "ad23-2stage-c", "ad01-l", "ad01-r";
		sprd,dma-2stage-usecase = <0x2>;
		sprd,node-count-2stage-level-1 = <0x1>;
		sprd,syscon-pmu-apb = <0x7>;
		sprd,dma-2stage-level-1-int-source = <0x1>;
		phandle = <0xcc>;
	};

	vaudio {
		compatible = "sprd,vaudio";
		#sound-dai-cells = <0x1>;
		clock-names = "tuned_26m";
		clocks = <0x24 0x0>;
		phandle = <0xcf>;
	};

	sprd-pcm-iis {
		compatible = "sprd,sharkl3-pcm-platform";
		#sound-dai-cells = <0x0>;
		dmas = <0x9b 0x5 0x9b 0x6>;
		dma-names = "iis0_tx", "iis0_rx";
		sprd,dma-2stage-usecase = <0x2>;
		sprd,node-count-2stage-level-1 = <0x1>;
		sprd,syscon-pmu-apb = <0x7>;
		sprd,dma-2stage-level-1-int-source = <0x1>;
		phandle = <0xd0>;
	};

	saudio_lte {
		compatible = "sprd,saudio";
		sprd,saudio-dst-id = <0x5>;
		sprd,ctrl_channel = <0xa>;
		sprd,playback_channel = <0xb 0x83 0x84>;
		sprd,capture_channel = <0xc>;
		sprd,monitor_channel = <0xd>;
		sprd,device = <0x3>;
		sprd,saudio-names = "saudiolte";
	};

	saudio_voip {
		compatible = "sprd,saudio";
		sprd,saudio-dst-id = <0x5>;
		sprd,ctrl_channel = <0xe>;
		sprd,playback_channel = <0xf 0x97>;
		sprd,capture_channel = <0x10>;
		sprd,monitor_channel = <0x11>;
		sprd,device = <0x2>;
		sprd,saudio-names = "saudiovoip";
	};

	audio-mem-mgr {
		compatible = "sprd,sharkl3-audio-mem";
		sprd,iram_phy_addr = <0x2000 0xb000>;
		sprd,iram_normal = <0x2000 0x0>;
		sprd,iram_deepbuf = <0x2000 0xa000>;
		sprd,iram_4arm7 = <0xc000 0x1000>;
	};

	cpus {
		#address-cells = <0x2>;
		#size-cells = <0x0>;

		cpu-map {

			cluster0 {

				core0 {
					cpu = <0x8a>;
				};

				core1 {
					cpu = <0x8c>;
				};

				core2 {
					cpu = <0x8e>;
				};

				core3 {
					cpu = <0x90>;
				};
			};

			cluster1 {

				core0 {
					cpu = <0x92>;
				};

				core1 {
					cpu = <0x94>;
				};

				core2 {
					cpu = <0x96>;
				};

				core3 {
					cpu = <0x98>;
				};
			};
		};

		cpu@0 {
			device_type = "cpu";
			compatible = "arm,cortex-a55", "arm,armv8";
			reg = <0x0 0x0>;
			enable-method = "psci";
			cpu-supply = <0x9c>;
			cpufreq-data-v1 = <0x9d>;
			cpu-idle-states = <0x9e>;
			sched-energy-costs = <0x9f 0xa0>;
			capacity-dmips-mhz = <0x400>;
			sugov_slack_timer;
			phandle = <0x8a>;
		};

		cpu@100 {
			device_type = "cpu";
			compatible = "arm,cortex-a55", "arm,armv8";
			reg = <0x0 0x100>;
			enable-method = "psci";
			cpu-supply = <0x9c>;
			cpufreq-data-v1 = <0x9d>;
			cpu-idle-states = <0x9e>;
			sched-energy-costs = <0x9f 0xa0>;
			capacity-dmips-mhz = <0x400>;
			phandle = <0x8c>;
		};

		cpu@200 {
			device_type = "cpu";
			compatible = "arm,cortex-a55", "arm,armv8";
			reg = <0x0 0x200>;
			enable-method = "psci";
			cpu-supply = <0x9c>;
			cpufreq-data-v1 = <0x9d>;
			cpu-idle-states = <0x9e>;
			sched-energy-costs = <0x9f 0xa0>;
			capacity-dmips-mhz = <0x400>;
			phandle = <0x8e>;
		};

		cpu@300 {
			device_type = "cpu";
			compatible = "arm,cortex-a55", "arm,armv8";
			reg = <0x0 0x300>;
			enable-method = "psci";
			cpu-supply = <0x9c>;
			cpufreq-data-v1 = <0x9d>;
			cpu-idle-states = <0x9e>;
			sched-energy-costs = <0x9f 0xa0>;
			capacity-dmips-mhz = <0x400>;
			phandle = <0x90>;
		};

		cpu@400 {
			device_type = "cpu";
			compatible = "arm,cortex-a55", "arm,armv8";
			reg = <0x0 0x400>;
			enable-method = "psci";
			cpu-supply = <0xa1>;
			cpufreq-data-v1 = <0xa2>;
			cpu-idle-states = <0x9e>;
			sched-energy-costs = <0xa3 0xa4>;
			capacity-dmips-mhz = <0x400>;
			phandle = <0x92>;
		};

		cpu@500 {
			device_type = "cpu";
			compatible = "arm,cortex-a55", "arm,armv8";
			reg = <0x0 0x500>;
			enable-method = "psci";
			cpu-supply = <0xa1>;
			cpufreq-data-v1 = <0xa2>;
			cpu-idle-states = <0x9e>;
			sched-energy-costs = <0xa3 0xa4>;
			capacity-dmips-mhz = <0x400>;
			phandle = <0x94>;
		};

		cpu@600 {
			device_type = "cpu";
			compatible = "arm,cortex-a55", "arm,armv8";
			reg = <0x0 0x600>;
			enable-method = "psci";
			cpu-supply = <0xa1>;
			cpufreq-data-v1 = <0xa2>;
			cpu-idle-states = <0x9e>;
			sched-energy-costs = <0xa3 0xa4>;
			capacity-dmips-mhz = <0x400>;
			phandle = <0x96>;
		};

		cpu@700 {
			device_type = "cpu";
			compatible = "arm,cortex-a55", "arm,armv8";
			reg = <0x0 0x700>;
			enable-method = "psci";
			cpu-supply = <0xa1>;
			cpufreq-data-v1 = <0xa2>;
			cpu-idle-states = <0x9e>;
			sched-energy-costs = <0xa3 0xa4>;
			capacity-dmips-mhz = <0x400>;
			phandle = <0x98>;
		};
	};

	energy-costs {

		core-cost0 {
			busy-cost-data = <0x1ec 0x50 0x236 0x65 0x280 0x7d 0x2c0 0x97 0x300 0xb5>;
			idle-cost-data = <0x19 0x19 0x0>;
			phandle = <0x9f>;
		};

		core-cost1 {
			busy-cost-data = <0x1ec 0x6e 0x2a0 0xa0 0x310 0xce 0x380 0x102 0x3c0 0x131 0x400 0x160>;
			idle-cost-data = <0x2c 0x2c 0x0>;
			phandle = <0xa3>;
		};

		cluster-cost0 {
			busy-cost-data = <0x1ec 0x1 0x236 0x2 0x280 0x3 0x2c0 0x4 0x300 0x5>;
			idle-cost-data = <0x0 0x0 0x0>;
			phandle = <0xa0>;
		};

		cluster-cost1 {
			busy-cost-data = <0x1ec 0x44 0x2a0 0x55 0x310 0x6a 0x380 0x82 0x3c0 0x99 0x400 0xb3>;
			idle-cost-data = <0x2a 0x2a 0x2a>;
			phandle = <0xa4>;
		};
	};

	idle-states {
		entry-method = "arm,psci";

		core_pd {
			compatible = "arm,idle-state";
			entry-latency-us = <0x3e8>;
			exit-latency-us = <0x1f4>;
			min-residency-us = <0x9c4>;
			local-timer-stop;
			arm,psci-suspend-param = <0x10000>;
			phandle = <0x9e>;
		};
	};

	cpufreq-clus0 {
		cpufreq-cluster-id = <0x0>;
		nvmem-cells = <0xa5>;
		nvmem-cell-names = "dvfs_bin";
		sprd,cpufreq-temp-threshold = <0x41>;
		clocks = <0xb 0x36 0xb 0x37 0xb 0x38 0xb 0x39 0x6 0x1 0xa6 0x0>;
		clock-names = "core_clk", "core1_clk", "core2_clk", "core3_clk", "low_freq_clk_parent", "high_freq_clk_parent";
		clock-latency = <0xc350>;
		voltage-tolerance = <0x190d>;
		volt-share-masters-bits = <0x1>;
		operating-points = <0x124f80 0x111e53 0x10c8e0 0x106738 0xf4240 0xfb01d 0xd7d20 0xee098 0xbb800 0xe04de>;
		operating-points-1 = <0x124f80 0x100590 0x10c8e0 0xf5aaa 0xf4240 0xea38f 0xd7d20 0xdc7d5 0xbb800 0xdbba0>;
		operating-points-2 = <0x124f80 0x10c8e0 0x10c8e0 0x101dfa 0xf4240 0xf66df 0xd7d20 0xe8b25 0xbb800 0xdbba0>;
		operating-points-3 = <0x124f80 0x118c30 0x10c8e0 0x10e14a 0xf4240 0x102a2f 0xd7d20 0xf4e75 0xbb800 0xe7ef0>;
		operating-points-1-65 = <0x124f80 0x105b03 0x10c8e0 0xfa3e8 0xf4240 0xeeccd 0xd7d20 0xe1d48 0xbb800 0xdbba0>;
		operating-points-2-65 = <0x124f80 0x111e53 0x10c8e0 0x106738 0xf4240 0xfb01d 0xd7d20 0xee098 0xbb800 0xe04de>;
		operating-points-3-65 = <0x10c8e0 0x112a88 0xf4240 0x10736d 0xd7d20 0xfa3e8 0xbb800 0xec82e>;
		phandle = <0x9d>;
	};

	cpufreq-clus1 {
		cpufreq-cluster-id = <0x1>;
		nvmem-cells = <0xa7>;
		nvmem-cell-names = "dvfs_bin";
		sprd,cpufreq-temp-threshold = <0x41>;
		cpufreq-sub-clusters = <0xa8>;
		clocks = <0xb 0x3a 0xb 0x3b 0xb 0x3c 0xb 0x3d 0x6 0x1 0xa6 0x1>;
		clock-names = "core_clk", "core1_clk", "core2_clk", "core3_clk", "low_freq_clk_parent", "high_freq_clk_parent";
		clock-latency = <0xc350>;
		voltage-tolerance = <0x0>;
		volt-share-masters-bits = <0xa>;
		freq-sync-slaves-bits = <0x8>;
		operating-points = <0x186a00 0x111e53 0x16e360 0x108bd7 0x155cc0 0x100590 0x12b128 0xf0537 0x100590 0xe1113 0xbb800 0xdbba0>;
		operating-points-1 = <0x186a00 0x100590 0x16e360 0xf7f49 0x155cc0 0xeeccd 0x12b128 0xdf8a9 0x100590 0xdbba0 0xbb800 0xdbba0>;
		operating-points-2 = <0x186a00 0x10c8e0 0x16e360 0x104299 0x155cc0 0xfb01d 0x12b128 0xebbf9 0x100590 0xdc7d5 0xbb800 0xdbba0>;
		operating-points-3 = <0x186a00 0x118c30 0x16e360 0x1105e9 0x155cc0 0x10736d 0x12b128 0xf7f49 0x100590 0xe8b25 0xbb800 0xdbba0>;
		operating-points-1-65 = <0x186a00 0x105b03 0x16e360 0xfc887 0x155cc0 0xf4240 0x12b128 0xe41e7 0x100590 0xdbba0 0xbb800 0xdbba0>;
		operating-points-2-65 = <0x186a00 0x111e53 0x16e360 0x108bd7 0x155cc0 0x100590 0x12b128 0xf0537 0x100590 0xe1113 0xbb800 0xdbba0>;
		operating-points-3-65 = <0x16e360 0x114f27 0x155cc0 0x10c8e0 0x12b128 0xfc887 0x100590 0xed463 0xbb800 0xdbba0>;
		phandle = <0xa2>;
	};

	cpufreq-fcm {
		cpufreq-cluster-id = <0x3>;
		nvmem-cells = <0xa9>;
		nvmem-cell-names = "dvfs_bin";
		sprd,cpufreq-temp-threshold = <0x41>;
		clocks = <0xb 0x3e 0x6 0x1 0xa6 0x2>;
		clock-names = "clk", "clk_low", "clk_high";
		clock-latency = <0xc350>;
		voltage-tolerance = <0x0>;
		volt-share-masters-bits = <0xa>;
		freq-sync-hosts-bits = <0x2>;
		operating-points = <0x1312d0 0x111e53 0x11e220 0x108bd7 0x10b558 0x100590 0xea218 0xf0537 0xc92c0 0xe1113 0xbb800 0xdbba0>;
		operating-points-1 = <0x1312d0 0x100590 0x11e220 0xf7f49 0x10b558 0xeeccd 0xea218 0xdf8a9 0xc92c0 0xdbba0 0xbb800 0xdbba0>;
		operating-points-2 = <0x1312d0 0x10c8e0 0x11e220 0x104299 0x10b558 0xfb01d 0xea218 0xebbf9 0xc92c0 0xdc7d5 0xbb800 0xdbba0>;
		operating-points-3 = <0x1312d0 0x118c30 0x11e220 0x1105e9 0x10b558 0x10736d 0xea218 0xf7f49 0xc92c0 0xe8b25 0xbb800 0xe1d48>;
		operating-points-1-65 = <0x1312d0 0x105b03 0x11e220 0xfc887 0x10b558 0xf4240 0xea218 0xe41e7 0xc92c0 0xdbba0 0xbb800 0xdbba0>;
		operating-points-2-65 = <0x1312d0 0x111e53 0x11e220 0x108bd7 0x10b558 0x100590 0xea218 0xf0537 0xc92c0 0xe1113 0xbb800 0xe04de>;
		operating-points-3-65 = <0x11e220 0x114f27 0x10b558 0x10c8e0 0xea218 0xfc887 0xc92c0 0xed463 0xbb800 0xec82e>;
		phandle = <0xa8>;
	};

	interrupt-controller@14000000 {
		compatible = "arm,gic-v3";
		#interrupt-cells = <0x3>;
		#address-cells = <0x2>;
		#size-cells = <0x2>;
		ranges;
		redistributor-stride = <0x0 0x20000>;
		#redistributor-regions = <0x1>;
		interrupt-controller;
		reg = <0x0 0x14000000 0x0 0x20000 0x0 0x14040000 0x0 0x100000>;
		interrupts = <0x1 0x9 0x4>;
		phandle = <0x1>;

		v2m@0 {
			compatible = "arm,gic-v2m-frame";
			msi-controller;
			reg = <0x0 0x0 0x0 0x1000>;
			phandle = <0x13b>;
		};
	};

	psci {
		compatible = "arm,psci-0.2";
		method = "smc";
	};

	power-debug {
		compatible = "sprd,power-debug";
		#address-cells = <0x1>;
		#size-cells = <0x0>;
		sprd,sys-ap-ahb = <0x20>;
		sprd,ap-ahb-reg-tbl = <0x0 0xf8000ff0 0x0>;
		sprd,sys-ap-apb = <0x1c>;
		sprd,ap-apb-reg-tbl = <0x0 0x3fffef 0x0>;
		sprd,sys-pmu-apb = <0x7>;
		sprd,pmu-apb-reg-tbl = <0xcc 0x7f3f3f3f 0xffffffff 0xd4 0xf0ffff 0x0 0x270 0xffffffff 0xffffffff 0xd0 0xffc11d77 0x0 0x2a0 0xffffffff 0x0 0x2a4 0xffffffff 0x0 0x2a8 0xffffffff 0x0 0x2ac 0xffffffff 0x0 0x2b0 0xffffffff 0x0 0x2b4 0xffffffff 0x0 0x2b8 0xffffffff 0x0 0x2bc 0xffff 0x0 0x2c0 0xffffffff 0x0 0x2c4 0xffff 0x0>;
		sprd,sys-aon-apb = <0x2>;
		sprd,aon-apb-reg-tbl = <0x0 0xf7ffffff 0x0 0x4 0xffffffbf 0x0 0xb0 0x1fffefff 0x0>;
		sprd,sys-ap-intc = <0xaa 0xab 0xac 0xad 0xae 0xaf>;
		sprd,ap-intc = <0xb0 0xb1 0xb2 0xb3 0xb4 0xb5>;
		sprd,pdm-name = <0xb6 0xb7 0xb8 0xb9 0xba 0xbb>;
		phandle = <0x13c>;

		pwr-status@bc {
			reg = <0xbc>;
			sprd,bit-width = <0x5>;
			sprd,bit-index = <0x0 0x5 0xa 0x11 0x16 0x1b>;
			sprd,pdm-names = "PD_CPU_TOP_STATE", "PD_CA53_LIT_MP2_STATE", "PD_CA53_BIG_MP2_STATE", "PD_AP_SYS_STATE", "PD_GPU_TOP_STATE", "PD_MM_TOP_STATE";
			phandle = <0xb6>;
		};

		pwr-status@c0 {
			reg = <0xc0>;
			sprd,bit-width = <0x5>;
			sprd,bit-index = <0x0 0x5 0xa 0xf 0x14 0x19>;
			sprd,pdm-names = "PD_WTLCP_HU3GE_B_STATE", "PD_WTLCP_HU3GE_A_STATE", "PD_WTLCP_TGDSP_STATE", "PD_WTLCP_LDSP_STATE", "PD_WTLCP_LTE_P2_STATE", "PD_WTLCP_LTE_P1_STATE";
			phandle = <0xb7>;
		};

		pwr-status@c4 {
			reg = <0xc4>;
			sprd,bit-width = <0x5>;
			sprd,bit-index = <0x0 0x5 0xa 0xf 0x14 0x19>;
			sprd,pdm-names = "PD_WTLCP_SYS", "PD_PUBCP_SYS", "PD_WTLCP_LTE_P3", "PD_DISP", "PD_PUB_SYS", "PD_WTLCP_TD";
			phandle = <0xb8>;
		};

		pwr-status@48c {
			reg = <0x48c>;
			sprd,bit-width = <0x5>;
			sprd,bit-index = <0x0 0x5 0xa 0xf>;
			sprd,pdm-names = "PD_CPU_LIT_C0", "PD_CPU_LIT_C1", "PD_CPU_BIG_C0", "PD_CPU_BIG_C1";
			phandle = <0xb9>;
		};

		pwr-status@490 {
			reg = <0x490>;
			sprd,bit-width = <0x5>;
			sprd,bit-index = <0x0 0x5 0xa 0xf 0x14>;
			sprd,pdm-names = "PD_DBG_SYS", "PD_CPU_MP8", "PD_WCN_SYS", "PD_WIFI_WRAP", "PD_GNSS_WRAP";
			phandle = <0xba>;
		};

		pwr-status@128 {
			reg = <0x128>;
			sprd,bit-width = <0x5>;
			sprd,bit-index = <0x0 0x5 0xa 0xf 0x14 0x19>;
			sprd,pdm-names = "PD_MM_VSP", "PD_GPU_CORE", "PD_CPU_LIT_C2", "PD_CPU_LIT_C3", "PD_CPU_BIG_C2", "PD_CPU_BIG_C3";
			phandle = <0xbb>;
		};

		ap-intc@0 {
			reg = <0x0>;
			sprd,int-names = "null", "null", "AP_UART0", "AP_UART1", "AP_UART2", "AP_UART3", "AP_UART4", "AP_SPI0", "AP_SPI1", "AP_SPI2", "AP_SIM", "AP_I2C0", "AP_I2C1", "AP_I2C2", "AP_I2C3", "AP_I2C4", "AP_IIS0", "AP_IIS1", "AP_IIS2", "AP_SPI3", "AUD", "AON_VBC_DAC23", "AON_VBC_DAC01", "AON_VBC_ADC01", "null", "ADI", "THM0", "AON_TMR0", "AON_TMR1", "AON_TMR2", "AON_FOR_AP", "AP_SYST";
			phandle = <0xb0>;
		};

		ap-intc@1 {
			reg = <0x0>;
			sprd,int-names = "null", "null", "I2C", "GPIO", "KPD", "EIC", "ANA", "GPU", "CSI2_R1", "CSI2_R2", "JPG", "VSP", "ISP_CH0", "DCAM0", "AP_DISPC", "AP_DSI_PLL", "AP_DSI_0", "AP_DSI_1", "AP_DMA", "AP_GSP", "AP_SEC_DMA", "AP_CE_SEC", "AP_CE_PUB", "AP_OTG", "AON_SEC_CNT", "AP_SDIO0", "AP_SDIO1", "AP_SDIO2", "AP_EMMC", "MPU_VIO", "SEC_EIC", "SEC_GPIO";
			phandle = <0xb1>;
		};

		ap-intc@2 {
			reg = <0x0>;
			sprd,int-names = "null", "null", "AP_NANDC", "null", "MBOX_SRC_AP", "MBOX_TAR_AP", "AON_DMA_AP", "CSI2_R2_S", "CSI2_R1_S", "SEC_RME2", "SEC_TMR1", "SEC_TMR0", "CSI_CAL_DONE", "null", "CHN_START_CHN_0", "CHN_START_CHN_1", "CHN_START_CHN_2", "CHN_START_CHN_3", "SEC_REQ_DMA", "PCP_WDG", "CP1_WDG", "SEC_WDG", "PUB_BUSMON", "APCPU_BUSMON", "null", "null", "WTLCP_BUSMON", "PUBCP_BUSMON", "AON_ANY_BUSMON", "BUSMON_AXI_BDG", "GPU_BUSMON", "CSI2_CAL_FAILED";
			phandle = <0xb2>;
		};

		ap-intc@3 {
			reg = <0x0>;
			sprd,int-names = "null", "null", "NCOMMIR_0", "NCOMMIR_1", "NCOMMIR_2", "NCOMMIR_3", "NCOMMIR_4", "NCOMMIR_5", "NCOMMIR_6", "NCOMMIR_7", "NCTIIRQ_0", "NCTIIRQ_1", "NCTIIRQ_2", "NCTIIRQ_3", "NCTIIRQ_4", "NCTIIRQ_5", "NCTIIRQ_6", "NCTIIRQ_7", "WDG_WCN_GNSS", "WDG_WCN_BTWF", "AP_I2C5", "AP_I2C6", "null", "MBOX_TAR_AP_UNWAKE", "null", "DVFS_IRQ_LVL", "SCC", "AP_WDG", "CA53_WDG", "ISP_CH1", "CPP", "CLK_32K_DET";
			phandle = <0xb3>;
		};

		ap-intc@4 {
			reg = <0x0>;
			sprd,int-names = "null", "null", "GPIO_PLUS_AP", "GPIO_PLUS_AP_SEC", "null", "null", "null", "null", "NCNTVIRQ_0", "NCNTVIRQ_1", "NCNTVIRQ_2", "NCNTVIRQ_3", "NCNTVIRQ_4", "NCNTVIRQ_5", "NCNTVIRQ_6", "NCNTVIRQ_7", "NPMUIRQ_0", "NPMUIRQ_1", "NPMUIRQ_2", "NPMUIRQ_3", "NPMUIRQ_4", "NPMUIRQ_5", "NPMUIRQ_6", "NPMUIRQ_7", "SLV_FW", "MEM_FW", "NCLUSTERPMUIRQ", "SYSMON_EVENT_IRQ_AP", "CSI2_R2_T", "CSI2_R1_T", "DCAM1", "DCAM2";
			phandle = <0xb4>;
		};

		ap-intc@5 {
			reg = <0x0>;
			sprd,int-names = "null", "null", "APCPU_GIC_PMU_INT", "APCPU_GIC_FAULT_INT", "NCNTHPIRQ_0", "NCNTHPIRQ_1", "NCNTHPIRQ_2", "NCNTHPIRQ_3", "NCNTHPIRQ_4", "NCNTHPIRQ_5", "NCNTHPIRQ_6", "NCNTHPIRQ_7", "NCNTPSIRQ_0", "NCNTPSIRQ_1", "NCNTPSIRQ_2", "NCNTPSIRQ_3", "NCNTPSIRQ_4", "NCNTPSIRQ_5", "NCNTPSIRQ_6", "NCNTPSIRQ_7", "NCNTPNSIRQ_0", "NCNTPNSIRQ_1", "NCNTPNSIRQ_2", "NCNTPNSIRQ_3", "NCNTPNSIRQ_4", "NCNTPNSIRQ_5", "NCNTPNSIRQ_6", "NCNTPNSIRQ_7", "APCPU_GIC_ERR_INT", "APCPU_CLUSTER_NFAULT", "APCPU_CLUSTER_NERRIRQ", "null";
			phandle = <0xb5>;
		};
	};

	timer {
		compatible = "arm,armv8-timer";
		interrupts = <0x1 0xd 0x4 0x1 0xe 0x4 0x1 0xb 0x4 0x1 0xa 0x4>;
		arm,no-tick-in-suspend;
	};

	pmu {
		compatible = "arm,armv8-pmuv3";
		interrupts = <0x0 0x90 0x4 0x0 0x91 0x4 0x0 0x92 0x4 0x0 0x93 0x4 0x0 0x94 0x4 0x0 0x95 0x4 0x0 0x96 0x4 0x0 0x97 0x4>;
	};

	sprd-gsp {
		compatible = "sprd,gsp-r6p0-sharkl3";
		core-cnt = <0x1>;
		io-cnt = <0x7>;
		cores = <0xbc>;
		power-domains = <0x60>;
		phandle = <0xd9>;
	};

	cpwcn_btwf {
		compatible = "sprd,integrate_marlin";
		sprd,name = "wcn_btwf";
		sprd,syscon-ap-apb = <0x2>;
		sprd,syscon-ap-pmu = <0x7>;
		sprd,syscon-ap-pub-apb = <0xbd>;
		sprd,syscon-anlg-wrap-wcn = <0xbe>;
		sprd,syscon-wcn-reg = <0xbf>;
		sprd,syscon-anlg-phy-g5 = <0x75>;
		sprd,ctrl-probe-num = <0x2>;
		sprd,ctrl-reg = <0x2004 0x3198 0x2100 0x20cc 0x20b0 0x1008>;
		sprd,ctrl-mask = <0x3000000 0x7ff 0x3000000 0x80000 0x10400 0x80>;
		sprd,ctrl-value = <0x3000000 0x102 0x3000000 0x80000 0x10400 0x80>;
		sprd,ctrl-rw-offset = <0x2000 0x0 0x2000 0x2000 0x2000 0x1000>;
		sprd,ctrl-us-delay = <0xa 0xa 0xa 0xa 0xa 0xa>;
		sprd,ctrl-type = <0x3 0x0 0x1 0x1 0x1 0x3>;
		sprd,ctrl-shutdown-reg = <0x2008 0x10b0>;
		sprd,ctrl-shutdown-mask = <0x80 0x400>;
		sprd,ctrl-shutdown-value = <0x80 0x400>;
		sprd,ctrl-shutdown-rw-offset = <0x2000 0x1000>;
		sprd,ctrl-shutdown-us-delay = <0xa 0xa>;
		sprd,ctrl-shutdown-type = <0x3 0x1>;
		reg = <0x0 0x84000000 0x0 0x180000>;
		sprd,file-name = "/dev/block/platform/soc/soc:ap-ahb/20600000.sdio/by-name/wcnmodem";
		sprd,file-length = <0x178000>;
		memory_region = <0xc0>;
		vddwcn-supply = <0xc1>;
		vddwifipa-supply = <0xc2>;
		#address-cells = <0x1>;
		#size-cells = <0x1>;
		nvmem-cells = <0xc3 0xc4 0xc5>;
		nvmem-cell-names = "wcn_efuse_blk0", "wcn_efuse_blk1", "wcn_efuse_blk2";
		phandle = <0x13d>;
	};

	cpwcn_gnss {
		compatible = "sprd,integrate_gnss";
		sprd,name = "wcn_gnss";
		sprd,syscon-ap-apb = <0x2>;
		sprd,syscon-ap-pmu = <0x7>;
		sprd,syscon-ap-pub-apb = <0xbd>;
		sprd,syscon-anlg-wrap-wcn = <0xbe>;
		sprd,syscon-wcn-reg = <0xbf>;
		sprd,syscon-anlg-phy-g5 = <0x75>;
		sprd,ctrl-probe-num = <0x2>;
		sprd,ctrl-reg = <0x1004 0x3198 0x2100 0x20cc 0x20b0 0x1008>;
		sprd,ctrl-mask = <0xffffff 0x7ff 0x3000000 0x80000 0x10800 0x40>;
		sprd,ctrl-value = <0x300000 0x102 0x3000000 0x80000 0x10800 0x40>;
		sprd,ctrl-rw-offset = <0x1000 0x0 0x2000 0x2000 0x2000 0x1000>;
		sprd,ctrl-us-delay = <0xa 0xa 0xa 0xa 0xa 0xa>;
		sprd,ctrl-type = <0x3 0x0 0x1 0x1 0x1 0x3>;
		sprd,ctrl-shutdown-reg = <0x2008 0x10b0>;
		sprd,ctrl-shutdown-mask = <0x40 0x800>;
		sprd,ctrl-shutdown-value = <0x40 0x800>;
		sprd,ctrl-shutdown-rw-offset = <0x2000 0x1000>;
		sprd,ctrl-shutdown-us-delay = <0xa 0xa>;
		sprd,ctrl-shutdown-type = <0x3 0x1>;
		reg = <0x0 0x84300000 0x0 0x100000>;
		sprd,file-name = "/dev/block/platform/soc/soc:ap-ahb/20600000.sdio/by-name/gpsgl";
		sprd,file-name-ext = "/dev/block/platform/soc/soc:ap-ahb/20600000.sdio/by-name/gpsbd";
		sprd,file-length = <0x100000>;
		memory_region = <0xc6>;
		vddwcn-supply = <0xc1>;
		#address-cells = <0x1>;
		#size-cells = <0x1>;
		nvmem-cells = <0xc7 0xc4 0xc5>;
		nvmem-cell-names = "gnss_efuse_blk0", "gnss_efuse_blk1", "gnss_efuse_blk2";
		phandle = <0x13e>;
	};

	wcn_sipc {
		compatible = "sprd,sipc";

		sipc@84180000 {
			sprd,name = "sipc-wcn";
			sprd,dst = <0x3 0x5>;
			sprd,smem-info = <0x84180000 0x180000 0x180000>;
			phandle = <0x13f>;
		};

		sipc@8441b000 {
			sprd,name = "sipc-gnss";
			sprd,dst = <0x4 0x6>;
			sprd,smem-info = <0x8441b000 0x11b000 0x32000>;
			phandle = <0x140>;
		};
	};

	wcn_spipe {
		compatible = "sprd,spipe";

		spipe_cpwcn {
			sprd,name = "spipe_wcn";
			sprd,dst = <0x3>;
			sprd,channel = <0x4>;
			sprd,ringnr = <0x10>;
			sprd,size-rxbuf = <0x2400>;
			sprd,size-txbuf = <0x2400>;
		};

		spipe_gnss {
			sprd,name = "sttygnss0";
			sprd,dst = <0x4>;
			sprd,channel = <0x4>;
			sprd,ringnr = <0x1>;
			sprd,size-rxbuf = <0x19000>;
			sprd,size-txbuf = <0xc800>;
		};
	};

	wcn_wifi_cmd {
		compatible = "sprd,swcnblk";
		sprd,name = "wcn_wifi_cmd";
		sprd,dst = <0x3>;
		sprd,channel = <0x7>;
		sprd,tx-blksize = <0x800>;
		sprd,tx-blknum = <0x4>;
		sprd,rx-blksize = <0x800>;
		sprd,rx-blknum = <0x10>;
	};

	wcn_wifi_data0 {
		compatible = "sprd,swcnblk";
		sprd,name = "wcn_wifi_data0";
		sprd,dst = <0x3>;
		sprd,channel = <0x8>;
		sprd,tx-blksize = <0x680>;
		sprd,tx-blknum = <0x40>;
		sprd,rx-blksize = <0x680>;
		sprd,rx-blknum = <0x100>;
	};

	wcn_wifi_data1 {
		compatible = "sprd,swcnblk";
		sprd,name = "wcn_wifi_data1";
		sprd,dst = <0x3>;
		sprd,channel = <0x9>;
		sprd,tx-blksize = <0x680>;
		sprd,tx-blknum = <0x40>;
		sprd,rx-blksize = <0x0>;
		sprd,rx-blknum = <0x0>;
	};

	wcn_bt {
		compatible = "sprd,wcn_internal_chip";
		sprd,name = "ttyBT";
		sprd,dst = <0x3>;
		sprd,channel = <0x4>;
		sprd,tx_bufid = <0xb>;
		sprd,rx_bufid = <0xa>;
	};

	wcn_fm {
		compatible = "sprd,wcn_internal_chip";
		sprd,name = "fm";
		sprd,dst = <0x3>;
		sprd,tx_channel = <0x4>;
		sprd,rx_channel = <0x4>;
		sprd,tx_bufid = <0xe>;
		sprd,rx_bufid = <0xd>;
	};

	gnss_common_ctl {
		compatible = "sprd,gnss_common_ctl";
		sprd,name = "gnss_common_ctl";
	};

	scproc-pubcp {
		compatible = "sprd,scproc_pubcp";
		#address-cells = <0x2>;
		#size-cells = <0x2>;
		ranges;

		scproc@800000 {
			sprd,name = "pmic";
			syscons = <0x2 0xff 0x0 0x7 0xff 0x100000 0x7 0xb0 0x80 0x2 0xff 0x0 0x2 0xff 0x0>;
			syscon-names = "shutdown", "deepsleep", "corereset", "sysreset", "getstatus";
			reg = <0x0 0x800000 0x0 0x40000>;
			#address-cells = <0x1>;
			#size-cells = <0x1>;
			ranges = <0x0 0x0 0x800000 0x3b000 0x3b000 0x0 0x83b000 0x5000>;
			phandle = <0xde>;

			pm-sys@0 {
				cproc,name = "pm_sys";
				reg = <0x0 0x3b000>;
			};

			cali_lib@3b000 {
				cproc,name = "cali_lib";
				reg = <0x3b000 0x5000>;
			};
		};

		scproc@f000 {
			sprd,decoup = "cproc-use-decoup";
			sprd,name = "cptl";
			syscons = <0x7 0x48 0x2000000 0x7 0xcc 0x40000 0x2 0x284 0x400 0x7 0xb0 0x2 0x2 0xff 0x0 0x2 0x130 0x30000>;
			syscon-names = "shutdown", "deepsleep", "corereset", "sysreset", "getstatus", "dspreset";
			reg = <0x0 0xf000 0x0 0x1000>;
			interrupts = <0x0 0x53 0x0>;
			phandle = <0x141>;
		};
	};

	sprd-sipc {
		compatible = "sprd,sipc";

		sipc@87800000 {
			sprd,name = "sipc-lte";
			sprd,dst = <0x5 0x2>;
			sprd,smem-info = <0x87800000 0x87800000 0x800000>;
			phandle = <0x142>;
		};

		sipc@d000 {
			sprd,name = "sipc-pmsys";
			sprd,dst = <0x6 0x1 0x7>;
			sprd,smem-info = <0xd000 0x2000b000 0x2000>;
			phandle = <0x143>;
		};
	};

	sprd-spipe {
		compatible = "sprd,spipe";

		spipe@0 {
			sprd,name = "spipe_pm";
			sprd,dst = <0x6>;
			sprd,channel = <0x4>;
			sprd,ringnr = <0x2>;
			sprd,size-rxbuf = <0xb00>;
			sprd,size-txbuf = <0x180>;
		};

		spipe@1 {
			sprd,name = "slog_pm";
			sprd,dst = <0x6>;
			sprd,channel = <0x5>;
			sprd,ringnr = <0x1>;
			sprd,size-rxbuf = <0x5c0>;
			sprd,size-txbuf = <0x20>;
		};

		spipe@2 {
			sprd,name = "sctl_pm";
			sprd,dst = <0x6>;
			sprd,channel = <0x6>;
			sprd,ringnr = <0x1>;
			sprd,size-rxbuf = <0x40>;
			sprd,size-txbuf = <0x20>;
		};

		spipe@3 {
			sprd,name = "spipe_lte";
			sprd,dst = <0x5>;
			sprd,channel = <0x4>;
			sprd,ringnr = <0xf>;
			sprd,size-rxbuf = <0x1000>;
			sprd,size-txbuf = <0x1000>;
		};

		spipe@4 {
			sprd,name = "sdiag_lte";
			sprd,dst = <0x5>;
			sprd,channel = <0x15>;
			sprd,ringnr = <0x1>;
			sprd,size-rxbuf = <0x20000>;
			sprd,size-txbuf = <0x8000>;
		};

		spipe@5 {
			sprd,name = "stty_lte";
			sprd,dst = <0x5>;
			sprd,channel = <0x6>;
			sprd,ringnr = <0x20>;
			sprd,size-rxbuf = <0x800>;
			sprd,size-txbuf = <0x800>;
		};
	};

	sprd-spool {
		compatible = "sprd,spool";
		sprd,name = "slog_lte";
		sprd,dst = <0x5>;
		sprd,channel = <0x5>;
		sprd,tx-blksize = <0x0>;
		sprd,tx-blknum = <0x0>;
		sprd,rx-blksize = <0x10000>;
		sprd,rx-blknum = <0x4>;
	};

	sprd-sipx {
		compatible = "sprd,sipx";
		sprd,name = "sipx_lte";
		sprd,dst = <0x5>;
		sprd,dl-pool = <0x800>;
		sprd,dl-ack-pool = <0x40>;
		sprd,ul-pool = <0x800>;
		sprd,ul-ack-pool = <0x400>;
	};

	seth@0 {
		compatible = "sprd,seth";
		sprd,dst = <0x5>;
		sprd,channel = <0x7>;
		sprd,blknum = <0x100>;
		phandle = <0x144>;
	};

	seth@1 {
		compatible = "sprd,seth";
		sprd,dst = <0x5>;
		sprd,channel = <0x8>;
		sprd,blknum = <0x100>;
		phandle = <0x145>;
	};

	seth@2 {
		compatible = "sprd,seth";
		sprd,dst = <0x5>;
		sprd,channel = <0x9>;
		sprd,blknum = <0x100>;
		phandle = <0x146>;
	};

	seth@3 {
		compatible = "sprd,seth";
		sprd,dst = <0x5>;
		sprd,channel = <0x12>;
		sprd,blknum = <0x100>;
		phandle = <0x147>;
	};

	seth@4 {
		compatible = "sprd,seth";
		sprd,dst = <0x5>;
		sprd,channel = <0x13>;
		sprd,blknum = <0x100>;
		phandle = <0x148>;
	};

	seth@5 {
		compatible = "sprd,seth";
		sprd,dst = <0x5>;
		sprd,channel = <0x14>;
		sprd,blknum = <0x100>;
		phandle = <0x149>;
	};

	seth@6 {
		compatible = "sprd,seth";
		sprd,dst = <0x5>;
		sprd,channel = <0x18>;
		sprd,blknum = <0x100>;
		phandle = <0x14a>;
	};

	seth@7 {
		compatible = "sprd,seth";
		sprd,dst = <0x5>;
		sprd,channel = <0x19>;
		sprd,blknum = <0x100>;
		phandle = <0x14b>;
	};

	seth@8 {
		compatible = "sprd,seth";
		sprd,dst = <0x5>;
		sprd,channel = <0x1a>;
		sprd,blknum = <0x100>;
		phandle = <0x14c>;
	};

	seth@9 {
		compatible = "sprd,seth";
		sprd,dst = <0x5>;
		sprd,channel = <0x1b>;
		sprd,blknum = <0x100>;
		phandle = <0x14d>;
	};

	seth@10 {
		compatible = "sprd,seth";
		sprd,dst = <0x5>;
		sprd,channel = <0x1c>;
		sprd,blknum = <0x100>;
		phandle = <0x14e>;
	};

	seth@11 {
		compatible = "sprd,seth";
		sprd,dst = <0x5>;
		sprd,channel = <0x1d>;
		sprd,blknum = <0x100>;
		phandle = <0x14f>;
	};

	seth@12 {
		compatible = "sprd,seth";
		sprd,dst = <0x5>;
		sprd,channel = <0x1e>;
		sprd,blknum = <0x100>;
		phandle = <0x150>;
	};

	seth@13 {
		compatible = "sprd,seth";
		sprd,dst = <0x5>;
		sprd,channel = <0x1f>;
		sprd,blknum = <0x100>;
		phandle = <0x151>;
	};

	lcds {

		lcd_dummy_mipi_hd {
			sprd,dsi-work-mode = <0x1>;
			sprd,dsi-lane-number = <0x4>;
			sprd,dsi-color-format = "rgb888";
			sprd,initial-command = [13 78 00 01 11 13 64 00 01 29];
			sprd,sleep-in-command = [13 0a 00 01 28 13 78 00 01 10];
			sprd,sleep-out-command = [13 78 00 01 11 13 64 00 01 29];
			phandle = <0x152>;

			display-timings {

				timing0 {
					clock-frequency = <0x493e000>;
					hactive = <0x2d0>;
					vactive = <0x500>;
					hback-porch = <0x3c>;
					hfront-porch = <0x50>;
					vback-porch = <0xc>;
					vfront-porch = <0x26>;
					hsync-len = <0x3c>;
					vsync-len = <0x4>;
				};
			};
		};

		lcd_hx83102d_mipi {
			sprd,dsi-work-mode = <0x1>;
			sprd,dsi-lane-number = <0x3>;
			sprd,dsi-color-format = "rgb888";
			sprd,phy-bit-clock = <0xb3b00>;
			sprd,width-mm = <0x4b>;
			sprd,height-mm = <0x96>;
			sprd,esd-check-enable = <0x0>;
			sprd,esd-check-mode = <0x1>;
			sprd,esd-check-period = <0x7d0>;
			sprd,esd-check-register = <0xa>;
			sprd,esd-check-value = <0x9d>;
			sprd,reset-on-sequence = <0x1 0x5 0x0 0xa 0x1 0x32>;
			sprd,reset-off-sequence = <0x0 0x14>;
			sprd,initial-command = [23 64 00 02 11 00 39 00 00 04 b9 83 10 2d 39 00 00 0c b1 22 22 31 31 31 41 43 25 08 08 08 39 00 00 0f b2 00 00 06 40 00 08 be 37 00 00 00 00 14 a0 39 00 00 0f b4 01 5c 01 5c 01 5c 01 5c 03 ff 03 03 00 ff 23 00 00 02 cc 02 39 00 00 1d d3 00 00 01 00 00 08 00 37 00 33 4f 0f 0f 00 00 32 10 0b 00 0b 32 16 4f 06 4f 32 10 00 39 00 00 2d d5 25 24 19 19 18 18 18 18 18 18 18 18 18 18 07 06 07 06 05 04 05 04 03 02 03 02 01 00 01 00 21 20 18 18 18 18 18 18 18 18 18 18 18 18 39 00 00 2d d6 20 21 18 18 18 18 18 18 19 19 18 18 18 18 00 01 00 01 02 03 02 03 04 05 04 05 06 07 06 07 24 25 18 18 18 18 18 18 18 18 18 18 18 18 39 00 00 03 e7 ff 0f 23 00 00 02 bd 01 23 00 00 02 e7 01 23 00 00 02 bd 00 39 00 00 04 b6 45 45 e0 39 00 00 2f e0 00 3b 4a 52 5a aa be c1 c2 ba cd cc cb d3 cb cc d0 dd d8 68 6e 77 7f 00 3b 4a 52 5a aa be c1 c2 ba cd cc cb d3 cb cc d0 dd d8 68 6e 77 7f 39 00 00 14 ba 71 23 a8 93 b2 c0 c0 01 10 00 00 00 0d 3d 82 77 04 01 40 39 00 00 08 bf fc 00 04 9e f6 00 5d 39 00 00 06 cb 00 13 00 02 58 23 00 00 02 bd 01 23 00 00 02 cb 01 23 00 00 02 bd 02 39 00 00 09 b4 42 00 33 00 33 88 b3 00 39 00 00 04 b1 7f 03 f5 23 00 00 02 bd 00 39 00 00 07 c0 30 30 00 00 19 21 23 00 00 02 35 00 23 0a 00 02 29 00];
			sprd,sleep-in-command = [13 32 00 01 28 13 78 00 01 10];
			sprd,sleep-out-command = [13 78 00 01 11 13 32 00 01 29];
			phandle = <0x153>;

			display-timings {

				timing0 {
					clock-frequency = <0x493e000>;
					hactive = <0x2d0>;
					vactive = <0x640>;
					hfront-porch = <0x18>;
					hback-porch = <0x14>;
					hsync-len = <0x13>;
					vfront-porch = <0xbe>;
					vback-porch = <0x10>;
					vsync-len = <0x2>;
				};
			};
		};

		lcd_ft8006_mipi {
			sprd,dsi-work-mode = <0x1>;
			sprd,dsi-lane-number = <0x4>;
			sprd,dsi-color-format = "rgb888";
			sprd,phy-bit-clock = <0xa8b38>;
			sprd,width-mm = <0x41>;
			sprd,height-mm = <0x91>;
			sprd,esd-check-enable = <0x0>;
			sprd,esd-check-mode = <0x1>;
			sprd,esd-check-period = <0x7d0>;
			sprd,reset-on-sequence = <0x1 0x5 0x0 0xa 0x1 0x78>;
			sprd,reset-off-sequence = <0x0 0x14>;
			sprd,initial-command = [23 00 00 02 41 5a 23 00 00 02 4c 03 29 00 00 03 41 5a 24 23 00 00 02 90 5a 29 00 00 03 41 5a 03 29 00 00 03 80 05 01 29 00 00 03 41 5a 08 29 00 00 04 80 c8 2c 01 29 00 00 03 41 5a 09 29 00 00 11 80 5a 51 b5 2a 6c e5 4a 01 40 62 0f 82 20 08 f0 b7 29 00 00 11 90 00 24 42 0a e3 91 a4 f0 ae c3 66 20 2d a1 26 00 29 00 00 11 a0 51 55 55 00 a0 4c 06 11 0d 60 5a ff ff 03 a5 e6 29 00 00 11 b0 08 c9 16 64 0b 00 00 11 07 60 00 ff ff 03 ff 34 29 00 00 09 c0 0c 3f 1f 9f 0f 00 08 00 29 00 00 03 41 5a 0a 29 00 00 11 80 ff 51 a3 02 00 0d 1a 2a 3b 4e 53 86 5e 97 a1 6f 29 00 00 11 90 90 68 63 52 40 30 1d 0b 00 0d 1a 2a 3b 4e 53 86 29 00 00 0e a0 5e 97 a1 6f 90 68 63 52 40 30 1d 0b 00 29 00 00 03 41 5a 0b 29 00 00 11 80 00 00 20 44 08 00 60 47 00 00 10 22 04 00 b0 23 29 00 00 03 90 15 00 29 00 00 03 41 5a 0c 29 00 00 11 80 fa 68 68 01 32 64 20 08 00 60 15 00 50 15 56 51 29 00 00 11 90 15 55 61 15 00 60 15 00 50 15 56 51 15 55 61 95 29 00 00 11 a0 ab 18 00 05 00 05 00 05 80 4c 29 84 52 01 09 00 29 00 00 03 b0 00 00 29 00 00 03 41 5a 0d 29 00 00 08 80 f0 b1 71 ef 4b c0 80 29 00 00 03 41 5a 0e 29 00 00 09 80 ff 01 55 55 23 88 88 1c 29 00 00 03 41 5a 0f 29 00 00 11 80 d1 07 6e c0 12 08 64 08 52 51 58 49 03 52 4c 4c 29 00 00 11 90 68 68 68 4c 4c 7c 14 00 20 06 c2 00 04 06 0c 00 29 00 00 05 a0 00 92 00 00 29 00 00 03 41 5a 10 29 00 00 11 80 00 00 03 e7 1f 17 10 48 80 aa d0 18 30 88 41 8a 29 00 00 10 90 39 28 a9 c5 9a 7b f0 07 7e e0 07 7e 20 10 00 29 00 00 03 41 5a 11 29 00 00 11 80 46 77 03 40 ca f3 ff 83 30 08 c4 06 a1 d8 24 18 29 00 00 11 90 30 c6 66 c1 80 31 15 cb e5 d2 68 6c 36 1d 04 c8 29 00 00 11 a0 b0 d9 88 60 b0 81 40 1a 1b 48 63 03 b9 00 1c 80 29 00 00 11 b0 50 30 00 e0 e1 01 00 28 0e 06 43 55 55 55 55 55 29 00 00 11 c0 95 88 88 88 88 88 c8 08 86 c6 e3 81 00 20 00 21 29 00 00 11 d0 42 88 00 00 00 00 40 00 00 31 04 41 06 00 00 00 29 00 00 11 e0 00 92 04 00 92 04 00 00 00 00 92 04 00 85 11 0c 29 00 00 10 f0 00 00 40 00 00 00 00 5e 4a 01 78 00 08 00 00 29 00 00 03 41 5a 12 29 00 00 11 80 00 00 00 00 00 02 03 00 00 00 00 02 03 01 41 37 29 00 00 11 90 f1 e7 00 00 00 00 00 00 00 00 00 00 00 2d 23 05 29 00 00 08 a0 fb 08 2d 23 05 fb 0c 29 00 00 03 41 5a 13 29 00 00 11 80 fd 0f 00 0c 00 00 00 00 01 08 01 1c 44 0c ce e7 29 00 00 0f 90 62 0e 24 98 ac 21 01 00 d0 93 24 49 06 20 29 00 00 03 41 5a 14 29 00 00 11 80 01 02 41 36 e9 ef f7 fb fd 7e 01 00 00 90 c5 06 29 00 00 11 90 39 4d 20 26 c8 69 02 b3 40 4e 13 98 01 72 9a 00 29 00 00 11 a0 00 fc 7e 00 00 e0 f7 03 00 20 83 b5 e2 f7 47 00 29 00 00 11 b0 d8 89 df 1f 01 00 10 00 00 2c b2 22 2b 00 40 a1 29 00 00 11 c0 50 78 0f e4 f4 80 51 1c ef 80 9c 1e 30 8a e3 05 29 00 00 11 d0 90 d3 03 46 71 bc 04 72 7a c0 28 0e d7 40 4e 0b 29 00 00 11 e0 18 c5 e1 22 c8 69 01 a3 38 5c 05 39 2d 60 14 87 29 00 00 11 f0 cb 20 a7 05 8c e2 18 01 bf df 08 00 00 00 00 00 29 00 00 03 41 5a 15 29 00 00 11 80 00 00 00 00 00 00 00 00 00 00 00 00 02 d9 e0 f7 29 00 00 11 90 53 00 20 63 c5 a8 c5 07 c9 90 5d 31 6a f1 41 8c 29 00 00 11 a0 78 00 00 00 00 00 00 00 00 00 00 00 00 00 00 00 29 00 00 11 b0 00 00 00 00 00 00 00 00 13 00 f0 00 94 75 5d 2d 29 00 00 11 c0 ca 20 04 00 92 da b6 6d db b6 6d db b6 5d d7 35 29 00 00 11 d0 9a 8a 23 18 ae aa 6d db b6 6d db b6 6d db 75 5d 29 00 00 11 e0 af ea 28 86 20 9a da b6 6d db b6 6d db b6 5d d7 29 00 00 11 f0 15 92 08 03 10 2c aa 6d db b6 6d db b6 6d 5b c0 29 00 00 03 41 5a 16 29 00 00 11 80 c3 43 41 01 00 00 00 00 00 00 00 00 00 00 00 00 29 00 00 07 90 00 00 00 00 f0 20 29 00 00 03 41 5a 18 29 00 00 11 80 ef bd f7 de 7b ef bd 07 08 08 0a 0c 0c 0c 0c 0c 29 00 00 11 90 0c 0c 0c 5c 09 a8 aa aa aa aa aa aa aa aa aa 5a 29 00 00 11 a0 59 59 59 59 59 59 59 59 59 59 59 09 04 ff 00 80 29 00 00 10 b0 80 00 04 20 00 01 08 40 00 02 10 80 00 04 00 29 00 00 03 41 5a 19 29 00 00 11 80 c0 af a3 9b 92 8d 8a 86 84 83 82 81 00 50 f6 cf 29 00 00 11 90 fc 2f f3 ef cf bf 0f ff af b5 71 0e 6c 4a 69 08 29 00 00 05 a0 00 00 08 00 29 00 00 03 41 5a 1a 29 00 00 11 80 00 04 08 0c 00 10 14 18 1c 00 20 28 30 38 00 40 29 00 00 11 90 48 50 58 00 60 68 70 78 00 80 88 90 98 00 a0 a8 29 00 00 11 a0 b0 b8 00 c0 c8 d0 d8 00 e0 e8 f0 f8 00 fc fe ff 29 00 00 11 b0 00 00 04 08 0c 00 10 14 18 1c 00 20 28 30 38 00 29 00 00 11 c0 40 48 50 58 00 60 68 70 78 00 80 88 90 98 00 a0 29 00 00 11 d0 a8 b0 b8 00 c0 c8 d0 d8 00 e0 e8 f0 f8 00 fc fe 29 00 00 11 e0 ff 00 00 04 08 0c 00 10 14 18 1c 00 20 28 30 38 29 00 00 11 f0 00 40 48 50 58 00 60 68 70 78 00 80 88 90 98 00 29 00 00 03 41 5a 1b 29 00 00 11 80 a0 a8 b0 b8 00 c0 c8 d0 d8 00 e0 e8 f0 f8 00 fc 29 00 00 05 90 fe ff 00 00 29 00 00 03 41 5a 20 29 00 00 08 80 81 00 00 00 00 00 00 29 00 00 03 41 5a 22 29 00 00 0e 80 2d d3 00 55 55 55 55 55 55 55 55 9f 00 29 00 00 03 41 5a 23 29 00 00 11 80 01 05 00 05 00 00 00 00 00 00 00 00 00 00 00 00 29 00 00 0d 90 ff 0f 00 00 00 03 00 00 00 ff 07 35 29 00 00 03 41 5a 24 29 00 00 11 80 00 03 00 ff ff 20 00 00 00 00 00 00 00 00 8a 5c 29 00 00 11 90 5a 5a 5a 55 00 00 00 00 00 00 00 00 00 00 00 00 23 00 00 02 42 24 23 00 00 02 90 00 29 00 00 03 41 5a 2f 23 00 00 02 19 00 13 78 00 01 11 13 32 00 01 29];
			sprd,sleep-in-command = [13 0a 00 01 28 13 78 00 01 10];
			sprd,sleep-out-command = [13 78 00 01 11 13 64 00 01 29];
			phandle = <0x154>;

			display-timings {

				timing0 {
					clock-frequency = <0x5b8d800>;
					hactive = <0x2d0>;
					vactive = <0x640>;
					hfront-porch = <0x50>;
					hback-porch = <0x3c>;
					hsync-len = <0x10>;
					vfront-porch = <0x82>;
					vback-porch = <0x6a>;
					vsync-len = <0x8>;
				};
			};
		};

		lcd_hx93102d_mipi {
			sprd,dsi-work-mode = <0x1>;
			sprd,dsi-lane-number = <0x4>;
			sprd,dsi-color-format = "rgb888";
			sprd,phy-bit-clock = <0xa8b38>;
			sprd,width-mm = <0x4b>;
			sprd,height-mm = <0x96>;
			sprd,esd-check-enable = <0x0>;
			sprd,esd-check-mode = <0x1>;
			sprd,esd-check-period = <0x7d0>;
			sprd,esd-check-register = <0xa>;
			sprd,esd-check-value = <0x9d>;
			sprd,reset-on-sequence = <0x1 0x5 0x0 0xa 0x1 0x78 0x1 0x5 0x0 0xa 0x1 0x78>;
			sprd,reset-off-sequence = <0x0 0x14>;
			sprd,initial-command = [23 96 00 01 11 39 00 00 04 b9 83 10 2d 39 00 00 0c c0 33 33 00 00 19 42 00 08 00 1a 0a 39 00 00 0c b1 22 44 31 31 33 42 4d 2f 08 08 08 39 00 00 0f b2 00 00 06 40 00 0d 20 3d 13 00 00 01 85 a0 39 00 00 0f b4 08 1b 08 1b 02 4a 02 4a 0b ff 05 20 00 ff 23 00 00 02 cc 02 39 05 00 1a d3 00 00 01 01 00 00 00 7f 00 77 35 0c 0c 00 00 32 10 04 00 04 54 16 52 06 52 39 05 00 2d d5 25 24 19 19 18 18 18 18 18 18 18 18 18 18 0f 0e 07 06 0d 0c 05 04 0b 0a 03 02 09 08 01 00 21 20 21 20 18 18 18 18 18 18 18 18 18 18 39 05 00 2d d6 20 21 18 18 18 18 18 18 19 19 18 18 18 18 00 01 08 09 02 03 0a 0b 04 05 0c 0d 06 07 0e 0f 24 25 24 25 18 18 18 18 18 18 18 18 18 18 39 00 00 1e e7 ff 10 02 02 00 00 14 14 00 07 0f 84 3c 84 32 32 00 00 00 00 00 10 68 10 10 1d b9 23 b9 23 00 00 02 bd 01 23 00 00 08 e7 01 40 01 40 13 40 14 23 00 00 02 bd 02 23 00 00 11 e7 00 fe 00 fe 00 00 02 00 01 00 00 00 00 00 00 00 23 00 00 0d d8 ff ff ff ff ff f0 ff ff ff ff ff f0 23 00 00 02 bd 03 23 00 00 19 d8 aa aa aa aa aa a0 aa aa aa aa aa a0 ff ff ff ff ff f0 ff ff ff ff ff f0 23 00 00 02 bd 00 39 00 00 03 b6 4c 4c 39 05 00 2f e0 00 1a 3b 45 4f 99 b2 b8 be b8 ce d0 d1 db d4 d6 db e9 e5 6f 75 7c 7f 00 1a 3b 45 4f 99 b2 b8 be b8 ce d0 d1 db d4 d6 db e9 e5 6f 75 7c 7f 39 00 00 14 ba 70 23 a8 93 b2 c0 c0 01 10 00 00 00 0d 3d 82 77 04 01 04 39 00 00 08 bf fc 00 04 9e f6 00 5d 39 00 00 06 cb 00 13 00 02 66 23 00 00 02 bd 01 23 00 00 02 cb 01 23 00 00 02 bd 02 39 00 00 09 b4 42 00 33 00 33 88 b3 33 39 00 00 04 b1 7f 03 f5 23 00 00 02 bd 00 23 00 00 02 00 00 23 00 00 02 35 00 23 00 00 03 51 0f ff 23 00 00 02 53 2c 23 00 00 02 55 00 23 32 00 02 29];
			sprd,sleep-in-command = [13 0a 00 01 28 13 78 00 01 10];
			sprd,sleep-out-command = [13 78 00 01 11 13 32 00 01 29];
			phandle = <0x155>;

			display-timings {

				timing0 {
					clock-frequency = <0x5b8d800>;
					hactive = <0x2d0>;
					vactive = <0x640>;
					hfront-porch = <0x50>;
					hback-porch = <0x3c>;
					hsync-len = <0x14>;
					vfront-porch = <0xb9>;
					vback-porch = <0x10>;
					vsync-len = <0x2>;
				};
			};
		};

		lcd_ili9882n_mipi {
			sprd,dsi-work-mode = <0x1>;
			sprd,dsi-lane-number = <0x4>;
			sprd,dsi-color-format = "rgb888";
			sprd,phy-bit-clock = <0xa8b38>;
			sprd,width-mm = <0x4b>;
			sprd,height-mm = <0x96>;
			sprd,esd-check-enable = <0x0>;
			sprd,esd-check-mode = <0x1>;
			sprd,esd-check-period = <0x7d0>;
			sprd,esd-check-register = <0xa>;
			sprd,esd-check-value = <0x9d>;
			sprd,reset-on-sequence = <0x1 0x5 0x0 0xa 0x1 0x78>;
			sprd,reset-off-sequence = <0x0 0x14>;
			sprd,initial-command = [29 00 00 04 ff 98 82 01 23 00 00 02 00 44 23 00 00 02 01 13 23 00 00 02 02 10 23 00 00 02 03 20 23 00 00 02 04 ca 23 00 00 02 05 13 23 00 00 02 06 10 23 00 00 02 07 20 23 00 00 02 08 82 23 00 00 02 09 09 23 00 00 02 0a b3 23 00 00 02 0b 00 23 00 00 02 0c 17 23 00 00 02 0d 17 23 00 00 02 0e 04 23 00 00 02 0f 04 23 00 00 02 10 0a 23 00 00 02 11 0a 23 00 00 02 12 09 23 00 00 02 16 82 23 00 00 02 17 09 23 00 00 02 18 33 23 00 00 02 19 00 23 00 00 02 1a 17 23 00 00 02 1b 17 23 00 00 02 1c 04 23 00 00 02 1d 04 23 00 00 02 1e 0a 23 00 00 02 1f 0a 23 00 00 02 20 09 23 00 00 02 24 02 23 00 00 02 25 0b 23 00 00 02 26 10 23 00 00 02 27 20 23 00 00 02 2c 34 23 00 00 02 31 07 23 00 00 02 32 2a 23 00 00 02 33 2a 23 00 00 02 34 0d 23 00 00 02 35 28 23 00 00 02 36 29 23 00 00 02 37 11 23 00 00 02 38 13 23 00 00 02 39 15 23 00 00 02 3a 17 23 00 00 02 3b 19 23 00 00 02 3c 1b 23 00 00 02 3d 09 23 00 00 02 3e 07 23 00 00 02 3f 07 23 00 00 02 40 07 23 00 00 02 41 07 23 00 00 02 42 07 23 00 00 02 43 07 23 00 00 02 44 07 23 00 00 02 45 07 23 00 00 02 46 07 23 00 00 02 47 07 23 00 00 02 48 2a 23 00 00 02 49 2a 23 00 00 02 4a 0c 23 00 00 02 4b 28 23 00 00 02 4c 29 23 00 00 02 4d 10 23 00 00 02 4e 12 23 00 00 02 4f 14 23 00 00 02 50 16 23 00 00 02 51 18 23 00 00 02 52 1a 23 00 00 02 53 08 23 00 00 02 54 07 23 00 00 02 55 07 23 00 00 02 56 07 23 00 00 02 57 07 23 00 00 02 58 07 23 00 00 02 59 07 23 00 00 02 5a 07 23 00 00 02 5b 07 23 00 00 02 5c 07 23 00 00 02 61 07 23 00 00 02 62 2a 23 00 00 02 63 2a 23 00 00 02 64 0d 23 00 00 02 65 28 23 00 00 02 66 29 23 00 00 02 67 11 23 00 00 02 68 13 23 00 00 02 69 15 23 00 00 02 6a 17 23 00 00 02 6b 19 23 00 00 02 6c 1b 23 00 00 02 6d 09 23 00 00 02 6e 07 23 00 00 02 6f 07 23 00 00 02 70 07 23 00 00 02 71 07 23 00 00 02 72 07 23 00 00 02 73 07 23 00 00 02 74 07 23 00 00 02 75 07 23 00 00 02 76 07 23 00 00 02 77 07 23 00 00 02 78 2a 23 00 00 02 79 2a 23 00 00 02 7a 0c 23 00 00 02 7b 28 23 00 00 02 7c 29 23 00 00 02 7d 10 23 00 00 02 7e 12 23 00 00 02 7f 14 23 00 00 02 80 16 23 00 00 02 81 18 23 00 00 02 82 1a 23 00 00 02 83 08 23 00 00 02 84 07 23 00 00 02 85 07 23 00 00 02 86 07 23 00 00 02 87 07 23 00 00 02 88 07 23 00 00 02 89 07 23 00 00 02 8a 07 23 00 00 02 8b 07 23 00 00 02 8c 07 23 00 00 02 a0 01 23 00 00 02 a2 00 23 00 00 02 a3 00 23 00 00 02 a4 00 23 00 00 02 a5 00 23 00 00 02 a6 00 23 00 00 02 a7 00 23 00 00 02 a8 00 23 00 00 02 a9 04 23 00 00 02 aa 04 23 00 00 02 ab 00 23 00 00 02 ac 00 23 00 00 02 ad 04 23 00 00 02 ae 04 23 00 00 02 b0 33 23 00 00 02 b1 33 23 00 00 02 b2 00 23 00 00 02 b9 40 23 00 00 02 c3 ff 23 00 00 02 ca 44 23 00 00 02 d0 01 23 00 00 02 d1 00 23 00 00 02 dc 37 23 00 00 02 dd 42 23 00 00 02 e2 00 23 00 00 02 e6 23 23 00 00 02 e7 54 23 00 00 02 ed 00 29 00 00 04 ff 98 82 02 23 00 00 02 f1 1c 23 00 00 02 4b 5a 23 00 00 02 50 ca 23 00 00 02 51 00 23 00 00 02 06 8d 23 00 00 02 0b a0 23 00 00 02 0c 00 23 00 00 02 0d 1a 23 00 00 02 0e f8 23 00 00 02 4e 11 29 00 00 04 ff 98 82 05 23 00 00 02 03 01 23 00 00 02 04 13 23 00 00 02 63 9c 23 00 00 02 64 9c 23 00 00 02 68 8f 23 00 00 02 69 95 23 00 00 02 6a cb 23 00 00 02 6b bd 23 00 00 02 46 00 23 00 00 02 85 37 29 00 00 04 ff 98 82 06 23 00 00 02 c0 40 23 00 00 02 c1 16 29 00 00 04 ff 98 82 08 29 00 00 1c e0 00 24 51 75 a7 50 d3 f8 23 46 95 7f af da 04 aa 31 67 8a b7 fe de 12 52 88 03 ec 29 00 00 1c e1 00 24 51 75 a7 50 d3 f8 23 46 95 7f af da 04 aa 31 67 8a b7 fe de 12 52 88 03 ec 29 00 00 04 ff 98 82 0b 23 00 00 02 9a 44 23 00 00 02 9b 82 23 00 00 02 9c 03 23 00 00 02 9d 03 23 00 00 02 9e 71 23 00 00 02 9f 71 23 00 00 02 ab e0 29 00 00 04 ff 98 82 0e 23 00 00 02 11 10 23 00 00 02 13 10 23 00 00 02 00 a0 29 00 00 04 ff 98 82 00 23 00 00 02 35 00 23 78 00 01 11 23 14 00 01 29];
			sprd,sleep-in-command = [13 0a 00 01 28 13 78 00 01 10];
			sprd,sleep-out-command = [13 78 00 01 11 13 64 00 01 29];
			phandle = <0x156>;

			display-timings {

				timing0 {
					clock-frequency = <0x5b8d800>;
					hactive = <0x2d0>;
					vactive = <0x640>;
					hfront-porch = <0x32>;
					hback-porch = <0x32>;
					hsync-len = <0x1e>;
					vfront-porch = <0xf2>;
					vback-porch = <0x20>;
					vsync-len = <0x2>;
				};
			};
		};
	};

	sprd-headset {
		compatible = "sprd,headset";
		status = "okay";
		jack-type = <0x0>;
		io-channels = <0x22 0x14>;
		io-channel-names = "headmic_in_little";
		gpios = <0x5c 0x3 0x0 0x5c 0x8 0x0 0x5c 0xc 0x0 0x5c 0x5 0x0 0x5c 0xd 0x0>;
		gpio-trigger-levels = <0x1 0x1 0x1 0x1 0x1>;
		gpio-dbnc-intervals = <0xa 0x64 0x64 0x64 0x64>;
		gpio-names = "button", "detect_l", "detect_h", "detect_mic", "detect_all";
		adc-threshold-3pole-detect = <0xbee>;
		sprd,adc-gnd = <0x150>;
		sprd,stable-value = <0x8af>;
		sprd,coefficient = <0xe573c>;
		irq-threshold-button = <0x9>;
		nvmem-cells = <0xc8 0xc9 0xca>;
		nvmem-cell-names = "protectbit", "auxadc", "headmic";
		phandle = <0xcb>;

		headset-button@0 {
			adc-min = <0x0>;
			adc-max = <0x1ea>;
			code = <0xe2>;
		};

		headset-button@1 {
			adc-min = <0x21c>;
			adc-max = <0x3fc>;
			code = <0x73>;
		};

		headset-button@2 {
			adc-min = <0x442>;
			adc-max = <0x960>;
			code = <0x72>;
		};
	};

	sound@0 {
		compatible = "sprd,vbc-r1p0v3-codec-sc2721";
		status = "okay";
		sprd-audio-card,name = "sprdphone";
		sprd-audio-card,widgets = "Headphone", "inter HP PA", "Speaker", "inter Ear PA";
		sprd-audio-card,routing = "HPMIC", "HP Mic Jack", "MIC", "Mic Jack", "AUXMIC", "Aux Mic Jack", "inter HP PA", "HP PA", "Ext Spk", "HP PA", "inter Ear PA", "EAR", "DMIC", "DMic Jack", "DMIC1", "DMic1 Jack", "Aud input", "AD Clk", "Aud input1", "AD Clk", "Aud input", "Digital ADCL Switch", "Aud input", "Digital ADCR Switch", "Aud input1", "Digital ADC1L Switch", "Aud input1", "Digital ADC1R Switch";
		sprd-audio-card,headset = <0xcb>;
		sprd-audio-card,fm-open-src = <0x1>;
		sprd-audio-card,fm-hw-rate = <0x7d00>;
		sprd-audio-card,codec-replace-adc-rate = <0xbb80>;
		sprd,spk-ext-pa-info = <0x0 0x0 0x3 0x0>;
		sprd,spk-ext-pa-gpio = <0x12 0x48 0x0>;
		sprd,spk-ext-pa-names = "ext_spk_r";
		phandle = <0x157>;

		sprd-audio-card,dai-link@0 {

			plat {
				sound-dai = <0xcc>;
			};

			cpu {
				sound-dai = <0xcd 0x0>;
			};

			codec {
				sound-dai = <0xce 0x0>;
			};
		};

		sprd-audio-card,dai-link@1 {

			plat {
				sound-dai = <0xcc>;
			};

			cpu {
				sound-dai = <0xcf 0x0>;
			};

			codec {
				sound-dai = <0xce 0x1>;
			};
		};

		sprd-audio-card,dai-link@2 {

			plat {
				sound-dai = <0xcc>;
			};

			cpu {
				sound-dai = <0xcd 0x1>;
			};

			codec {
				sound-dai = <0xce 0x3>;
			};
		};

		sprd-audio-card,dai-link@3 {

			plat {
				sound-dai = <0xcc>;
			};

			cpu {
				sound-dai = <0xcf 0x1>;
			};

			codec {
				sound-dai = <0xce 0x4>;
			};
		};

		sprd-audio-card,dai-link@4 {
			ops = <0x0>;

			plat {
				sound-dai = <0xcc>;
			};

			cpu {
				sound-dai = <0xcd 0x2>;
			};

			codec {
				sound-dai = <0xce 0x5>;
			};
		};

		sprd-audio-card,dai-link@5 {

			plat {
				sound-dai = <0xcc>;
			};

			cpu {
				sound-dai = <0xcd 0x3>;
			};

			codec {
				sound-dai = <0xce 0x6>;
			};
		};
	};

	sound@1 {
		compatible = "sprd,i2s-null-codec";
		status = "okay";
		sprd-audio-card,name = "all-i2s";
		phandle = <0x158>;

		sprd-audio-card,dai-link@0 {

			plat {
				sound-dai = <0xd0>;
			};

			cpu {
				sound-dai = <0xd1>;
			};

			codec {
				sound-dai = <0x0 0x0>;
			};
		};
	};

	firmware {

		android {
			compatible = "android,firmware";

			vbmeta {
				compatible = "android,vbmeta";
				parts = "socko,odmko,boot,recovery,dtbo,l_modem,pm_sys,l_ldsp,l_gdsp";
			};
		};
	};

	thermal-zones {
		phandle = <0x159>;

		cpu-thmzone {
			polling-delay-passive = <0x64>;
			polling-delay = <0x3e8>;
			sustainable-power = <0xbb8>;
			thermal-sensors = <0xd2 0x0>;
			phandle = <0x15a>;

			trips {

				trip-point@0 {
					temperature = <0x11170>;
					hysteresis = <0x3e8>;
					type = "passive";
					phandle = <0x15b>;
				};

				trip-point@1 {
					temperature = <0x14c08>;
					hysteresis = <0x3e8>;
					type = "passive";
					phandle = <0xd3>;
				};

				bia_crit {
					temperature = <0x1adb0>;
					hysteresis = <0x7d0>;
					type = "critical";
					phandle = <0x15c>;
				};
			};

			cooling-maps {

				map0 {
					trip = <0xd3>;
					contribution = <0x400>;
					cooling-device = <0xd4 0xffffffff 0xffffffff>;
				};

				map1 {
					trip = <0xd3>;
					contribution = <0x2a2>;
					cooling-device = <0xd5 0xffffffff 0xffffffff>;
				};
			};
		};

		gpu-thmzone {
			polling-delay-passive = <0x0>;
			polling-delay = <0x0>;
			thermal-sensors = <0xd6 0x0>;
			phandle = <0x15d>;
		};

		board-thmzone {
			polling-delay-passive = <0x0>;
			polling-delay = <0x0>;
			thermal-sensors = <0xd7>;
			phandle = <0x15e>;
		};
	};

	cooling-devices {

		cluster0-cooling {
			compatible = "sprd,cluster-cooling";
			#cooling-cells = <0x2>;
			sprd,efuse-block7 = <0x7>;
			sprd,efuse-block15 = <0xf>;
			sprd,leak-core = <0x2 0x55 0x74d>;
			sprd,leak-cluster = <0x2 0x55 0x9dc>;
			sprd,core-temp-scale = <0x1d 0xfffff7cc 0x186a0 0xfff72660>;
			sprd,core-voltage-scale = <0xc9 0xffffff57 0x53 0xfffffff0>;
			sprd,cluster-temp-scale = <0x1d 0xfffff7cc 0x186a0 0xfff72660>;
			sprd,cluster-voltage-scale = <0xc9 0xffffff57 0x53 0xfffffff0>;
			sprd,efuse-switch = <0x0>;
			sprd,hotplug-period = <0xa>;
			sprd,min-cpufreq = <0xbb800>;
			sprd,min-cpunum = <0x4>;
			sprd,core-base = <0x960>;
			sprd,cluster-base = <0xf82>;
			sprd,dynamic-core = <0x3ef 0x3e8 0x3e8>;
			sprd,dynamic-cluster = <0x2eb 0x3e8 0x3e8>;
			phandle = <0xd4>;
		};

		cluster1-cooling {
			compatible = "sprd,cluster-cooling";
			#cooling-cells = <0x2>;
			sprd,efuse-block7 = <0x7>;
			sprd,efuse-block15 = <0xf>;
			sprd,leak-core = <0x8 0x55 0x7c0>;
			sprd,leak-cluster = <0x8 0x55 0x810>;
			sprd,core-temp-scale = <0x1d 0xfffff7cc 0x186a0 0xfff72660>;
			sprd,core-voltage-scale = <0xc9 0xffffff57 0x53 0xfffffff0>;
			sprd,cluster-temp-scale = <0x1d 0xfffff7cc 0x186a0 0xfff72660>;
			sprd,cluster-voltage-scale = <0xc9 0xffffff57 0x53 0xfffffff0>;
			sprd,efuse-switch = <0x0>;
			sprd,hotplug-period = <0xa>;
			sprd,min-cpufreq = <0xbb800>;
			sprd,min-cpunum = <0x0>;
			sprd,core-base = <0x105e>;
			sprd,cluster-base = <0xf82>;
			sprd,dynamic-core = <0x600 0x3e8 0x3e8>;
			sprd,dynamic-cluster = <0x2eb 0x3e8 0x3e8>;
			phandle = <0xd5>;
		};
	};

	gpu-cooling-devices {

		gpu-cooling0 {
			compatible = "sprd,mali-power-model";
			#cooling-cells = <0x2>;
			sprd,efuse-block7 = <0x7>;
			sprd,efuse-block15 = <0xf>;
			sprd,leak-core = <0x2 0x55 0x74d>;
			sprd,leak-cluster = <0x2 0x55 0x9dc>;
			sprd,temp-scale = <0x12c 0xffff8eb8 0x16c038 0xff2af4f0>;
			sprd,voltage-scale = <0xfffff9a3 0x19e3 0xffffe529 0x8ae>;
			sprd,hotplug-period = <0x0>;
			sprd,core-base = <0x3c6>;
			sprd,cluster-base = <0x3c6>;
			sprd,dynamic-core = <0x179e 0x300 0x384>;
			sprd,dynamic-cluster = <0x17b0 0x300 0x384>;
			phandle = <0x15f>;
		};
	};

	display-subsystem {
		compatible = "sprd,display-subsystem";
		ports = <0xd8>;
		gsp = <0xd9>;
	};

	scene-frequency {
		compatible = "sprd,dfs";
		freq-num = <0x8>;
		phandle = <0x160>;
	};

	reserved-memory {
		#address-cells = <0x2>;
		#size-cells = <0x2>;
		ranges;
		phandle = <0x161>;

		sipc-mem@87800000 {
			reg = <0x0 0x87800000 0x0 0x800000>;
			phandle = <0xdf>;
		};

		cp-modem@89600000 {
			reg = <0x0 0x89600000 0x0 0x5850000>;
			phandle = <0xdd>;
		};

		iq-mem@90000000 {
			compatible = "sprd,iq-mem";
			reg = <0x0 0x90000000 0x0 0x4000000>;
			phandle = <0xe2>;
		};

		sml-mem@94000000 {
			reg = <0x0 0x94000000 0x0 0x20000>;
			phandle = <0xe1>;
		};

		tos-mem@94020000 {
			reg = <0x0 0x94020000 0x0 0x1fe0000>;
			phandle = <0xe0>;
		};

		ramoops@fff80000 {
			compatible = "ramoops";
			reg = <0x0 0xfff80000 0x0 0x40000>;
			record-size = <0x8000>;
			console-size = <0x8000>;
			pmsg-size = <0x8000>;
			phandle = <0x162>;
		};

		wcn-mem@84000000 {
			reg = <0x0 0x84000000 0x0 0x300000>;
			phandle = <0xc0>;
		};

		gnss-mem@84300000 {
			reg = <0x0 0x84300000 0x0 0x15b000>;
			phandle = <0xc6>;
		};

		logobuffer@fd580000 {
			reg = <0x0 0xfd580000 0x0 0x7e9000>;
			phandle = <0x61>;
		};

		camera@fdd69000 {
			reg = <0x0 0xfdd69000 0x0 0xa00000>;
			phandle = <0xe4>;
		};

		framebuffer@fe769000 {
			reg = <0x0 0xfe769000 0x0 0x1817000>;
			phandle = <0xe3>;
		};
	};

	sprd-sensorhub {
		compatible = "sprd,sharkl3-sensorhub";
	};

	autotest {
		compatible = "sprd,autotest";
		sprd,pinctrl = <0xda>;
		phandle = <0x163>;
	};

	revo-dt-test {
		compatible = "revo,get_dts_pin_test";
		revo,gpio0 = <0x12 0x0 0x0>;
		revo,gpio63 = <0x12 0x3f 0x0>;
		revo,gpio64 = <0x12 0x40 0x0>;
		revo,gpio144 = <0x12 0x90 0x0>;
		revo,gpio145 = <0x12 0x91 0x0>;
		revo,gpio19 = <0x12 0x13 0x0>;
		revo,eic0 = <0x28 0x0 0x0>;
		revo,eic4 = <0x28 0x4 0x0>;
		revo,eic6 = <0x28 0x6 0x0>;
	};

	memory {
		device_type = "memory";
		reg = <0x0 0x80000000 0x0 0x80000000>;
		phandle = <0xdc>;
	};

	chosen {
		stdout-path = "/soc/ap-apb/serial@70100000";
		bootargs = "earlycon=sprd_serial,0x70100000,115200n8 console=ttyS1,115200n8 loglevel=1 init=/init root=/dev/ram0 rw androidboot.hardware=s9863a1h10 androidboot.dtbo_idx=0 printk.devkmsg=on androidboot.boot_devices=soc/soc:ap-ahb/20600000.sdio";
	};

	interrupt-controller {
		compatible = "android,CustomIPI";
		#interrupt-cells = <0x1>;
		interrupt-controller;
		phandle = <0xdb>;
	};

	trusty {
		compatible = "android,trusty-smc-v1";

		irq {
			compatible = "android,trusty-irq-v1";
			interrupt-templates = <0xdb 0x0 0x1 0x1 0x1 0x0 0x1 0x1 0x0 0x0>;
			interrupt-ranges = <0x0 0xf 0x0 0x10 0x1f 0x1 0x20 0xdf 0x2>;
		};

		virtio {
			compatible = "android,trusty-virtio-v1";
		};

		log {
			compatible = "android,trusty-log-v1";
		};
	};

	sprd-sysdump {
		memory-region = <0xdc>;
		memory-region-re = <0xdd 0xde 0xdf 0xc6 0xc0>;
		memory-region-se = <0xe0 0xe1>;
	};

	sprd-iq {
		compatible = "sprd,iq";
		sprd,region = <0xe2>;
		sprd,mapping-offs = <0x0>;
	};

	sprd-map-user {
		compatible = "sprd,map-user";
	};

	ion {
		compatible = "sprd,ion";
		#address-cells = <0x1>;
		#size-cells = <0x0>;
		phandle = <0x164>;

		heap@1 {
			reg = <0x1>;
			label = "carveout_mm";
			type = <0x2>;
		};

		heap@2 {
			reg = <0x2>;
			label = "carveout_fb";
			type = <0x2>;
			memory-region = <0xe3>;
		};

		heap@4 {
			reg = <0x4>;
			label = "carveout_camera";
			type = <0x2>;
			memory-region = <0xe4>;
		};
	};

	flash-gpio {
		compatible = "sprd,flash-gpio";
		flash-torch-en-gpios = <0x12 0x85 0x0>;
		flash-en-gpios = <0x12 0x84 0x0>;
		flash-torch-en-gpios-1 = <0x12 0x79 0x0>;
		flash-en-gpios-1 = <0x12 0x5d 0x0>;
	};

	gpio-keys {
		compatible = "gpio-keys";
		phandle = <0x165>;

		key-volumedown {
			label = "Volume Down Key";
			linux,code = <0x72>;
			gpios = <0x5c 0xa 0x0>;
			debounce-interval = <0x2>;
			wakeup-source;
		};

		key-volumeup {
			label = "Volume Up Key";
			linux,code = <0x73>;
			gpios = <0x12 0x7c 0x1>;
			debounce-interval = <0x2>;
			wakeup-source;
		};

		key-power {
			label = "Power Key";
			linux,code = <0x74>;
			gpios = <0x5c 0x1 0x1>;
			debounce-interval = <0x2>;
			wakeup-source;
		};
	};

	thermal-sensor {
		compatible = "generic-adc-thermal";
		#thermal-sensor-cells = <0x0>;
		io-channels = <0x22 0x1>;
		io-channel-names = "sensor-channel";
		temperature-lookup-table = <0xffff64c2 0x46b 0xffff8baf 0x456 0xffffb3e8 0x432 0xffffedb9 0x3d7 0x277e 0x346 0x60e5 0x28e 0xaf7a 0x19d 0xd677 0x13c 0xfd7f 0xee 0x12484 0xb2 0x14b93 0x85 0x172a3 0x64 0x199b0 0x4b 0x1c0c9 0x39 0x1e7c8 0x2b>;
		phandle = <0xd7>;
	};

	battery {
		compatible = "simple-battery";
		charge-full-design-microamp-hours = <0x493e00>;
		charge-term-current-microamp = <0x1fbd0>;
		constant_charge_voltage_max_microvolt = <0x435e18>;
		factory-internal-resistance-micro-ohms = <0x3bd08>;
		voltage-min-design-microvolt = <0x34a490>;
		ocv-capacity-celsius = <0x14>;
		ocv-capacity-table-0 = <0x428358 0x64 0x41bc20 0x5f 0x40d1c0 0x5a 0x3ff700 0x55 0x3f2410 0x50 0x3e58f0 0x4b 0x3da158 0x46 0x3ce1f0 0x41 0x3c5168 0x3c 0x3b9200 0x37 0x3ae620 0x32 0x3a7ca8 0x2d 0x3a2aa0 0x28 0x39ec20 0x23 0x39b570 0x1e 0x397ad8 0x19 0x392cb8 0x14 0x38d6c8 0xf 0x3855e0 0xa 0x382ae8 0x5 0x33e140 0x0>;
		charge-sdp-current-microamp = <0x7a120 0x7a120>;
		charge-dcp-current-microamp = <0x1e8480 0x1e8480>;
		charge-cdp-current-microamp = <0x1e8480 0x1e8480>;
		charge-unknown-current-microamp = <0x7a120 0x7a120>;
		phandle = <0x1a>;
	};

	charger-manager {
		compatible = "charger-manager";
		cm-name = "battery";
		cm-poll-mode = <0x2>;
		cm-poll-interval = <0x3a98>;
		cm-battery-stat = <0x2>;
		cm-fullbatt-vchkdrop-ms = <0x7530>;
		cm-fullbatt-vchkdrop-volt = <0xea60>;
		cm-fullbatt-voltage = <0x42ae50>;
		cm-fullbatt-current = <0x1d4c0>;
		cm-fullbatt-capacity = <0x64>;
		cm-num-chargers = <0x2>;
		cm-chargers = "fan54015_charger", "sc2721_charger";
		cm-fuel-gauge = "sc27xx-fgu";
		cm-battery-cold = <0xc8>;
		cm-battery-cold-in-minus;
		cm-battery-hot = <0x320>;
		cm-battery-temp-diff = <0x64>;
		cm-charging-max = <0x1499700>;
		cm-discharging-max = <0x2932e0>;
		cm-wdt-interval = <0x3c 0x0>;
		cm-shutdown-voltage = <0x2f4d60>;
		cm-tickle-time-out = <0x1e0>;
		cm-one-cap-time = <0x1e>;
		cm-charge-voltage-max = <0x632ea0>;
		cm-charge-voltage-drop = <0xaae60>;
		monitored-battery = <0x1a>;
		cm-capacity-track;
		phandle = <0x166>;

		regulator@0 {
			cm-regulator-name = "vddgen0";

			cable@0 {
				cm-cable-name = "USB";
				extcon = <0x1e>;
			};
		};
	};

	sprd-wlan {
		compatible = "sprd,sp9863a";
	};

	extcon-gpio {
		compatible = "linux,extcon-usb-gpio";
		vbus-gpio = <0x5c 0x0 0x0>;
		id-gpio = <0xe5 0x4 0x0>;
		phandle = <0x1b>;
	};

	fingerprint_blestech {
		compatible = "sprd,betterlife-fp";
		reset-gpio = <0x12 0x83 0x0>;
		int_gpio = <0x28 0xd 0x0>;
		phandle = <0x167>;
	};

	cdfinger_fingerprint {
		compatible = "cdfinger,fingerprint";
		fpreset-gpios = <0x12 0x83 0x0>;
		fpint-gpios = <0x28 0xd 0x0>;
		phandle = <0x168>;
	};

	sunwave-fp {
		compatible = "sunwave,fingerprint";
		sunwave,reset-gpio = <0x12 0x83 0x0>;
		sunwave,irq-gpio = <0x28 0xd 0x0>;
		phandle = <0x169>;
	};

	ma-fingerprint {
		compatible = "microarray,fingerprint";
		maint-gpios = <0x28 0xd 0x0>;
		phandle = <0x16a>;
	};

	fpsensor-fp {
		compatible = "fpsensor,fingerprint";
		fpreset-gpios = <0x12 0x83 0x0>;
		fpint-gpios = <0x28 0xd 0x0>;
		phandle = <0x16b>;
	};

	__symbols__ {
		soc = "/soc";
		modem_dbg_log = "/soc/modem-dbg-log@1000c000";
		ap_ahb_regs = "/soc/syscon@20e00000";
		pub_apb_regs = "/soc/syscon@300e0000";
		pub_ahb_regs = "/soc/syscon@300f0000";
		aon_mailbox = "/soc/mailbox@400a0000";
		aon_intc_regs = "/soc/syscon@40200000";
		pmu_apb_regs = "/soc/syscon@402b0000";
		disp_pd = "/soc/power-domain@402b0058";
		aon_apb_regs = "/soc/syscon@402e0000";
		anlg_phy_g1_regs = "/soc/syscon@40350000";
		anlg_phy_g2_regs = "/soc/syscon@40353000";
		anlg_phy_g4_regs = "/soc/syscon@40359000";
		anlg_phy_g5_regs = "/soc/syscon@4035c000";
		anlg_phy_g7_regs = "/soc/syscon@40363000";
		anlg_wrap_wcn_regs = "/soc/syscon@40366000";
		wcn_regs = "/soc/syscon@403a0000";
		mm_ahb_regs = "/soc/syscon@60800000";
		mm_vsp_ahb_regs = "/soc/syscon@62000000";
		ap_apb_regs = "/soc/syscon@71300000";
		ap_intc0_regs = "/soc/syscon@40500000";
		ap_intc1_regs = "/soc/syscon@40510000";
		ap_intc2_regs = "/soc/syscon@40520000";
		ap_intc3_regs = "/soc/syscon@40530000";
		ap_intc4_regs = "/soc/syscon@40540000";
		ap_intc5_regs = "/soc/syscon@40550000";
		uart0 = "/soc/ap-apb/serial@70000000";
		uart1 = "/soc/ap-apb/serial@70100000";
		uart2 = "/soc/ap-apb/serial@70200000";
		uart3 = "/soc/ap-apb/serial@70300000";
		uart4 = "/soc/ap-apb/serial@70400000";
		i2c0 = "/soc/ap-apb/i2c@70500000";
		sensor_main = "/soc/ap-apb/i2c@70500000/sensor-main@20";
		i2c1 = "/soc/ap-apb/i2c@70600000";
		sensor_sub = "/soc/ap-apb/i2c@70600000/sensor-sub@20";
		sensor_main2 = "/soc/ap-apb/i2c@70600000/sensor-main2@6C";
		i2c2 = "/soc/ap-apb/i2c@70700000";
		i2c3 = "/soc/ap-apb/i2c@70800000";
		i2c4 = "/soc/ap-apb/i2c@70900000";
		fan54015_chg = "/soc/ap-apb/i2c@70900000/charger@6a";
		vddvbus = "/soc/ap-apb/i2c@70900000/charger@6a/otg-vbus";
		flash_ic = "/soc/ap-apb/i2c@70900000/flash-ic@63";
		spi0 = "/soc/ap-apb/spi@70a00000";
		spi1 = "/soc/ap-apb/spi@70b00000";
		spi2 = "/soc/ap-apb/spi@70c00000";
		i2s0 = "/soc/ap-apb/i2s@70d00000";
		spi3 = "/soc/ap-apb/spi@71400000";
		i2c5 = "/soc/ap-apb/i2c@71500000";
		i2c6 = "/soc/ap-apb/i2c@71600000";
		ap_dma = "/soc/ap-ahb/dma-controller@20100000";
		usb = "/soc/ap-ahb/usb@20200000";
		hsphy = "/soc/ap-ahb/hsphy@20e00000";
		sdio3 = "/soc/ap-ahb/sdio@20600000";
		sdio0 = "/soc/ap-ahb/sdio@20300000";
		sprd_audio_codec_dig = "/soc/aon/audio-codec@40000000";
		vbc = "/soc/aon/vbc@40020000";
		aon_dma = "/soc/aon/dma-controller@40100000";
		eic_debounce = "/soc/aon/gpio@40210000";
		eic_latch = "/soc/aon/gpio@40210080";
		eic_async = "/soc/aon/gpio@402100a0";
		eic_sync = "/soc/aon/gpio@402100c0";
		aon_systimer = "/soc/aon/timer@40230000";
		aon_sysfrt = "/soc/aon/timer@40040000";
		ap_efuse = "/soc/aon/efuse@40240000";
		gthm_delta = "/soc/aon/efuse@40240000/gthm-delta@21";
		cthm_sign = "/soc/aon/efuse@40240000/cthm-sign@22";
		cthm_ratio = "/soc/aon/efuse@40240000/cthm-ratio@22";
		cthm_delta = "/soc/aon/efuse@40240000/cthm-delta@23";
		wcn_alpha = "/soc/aon/efuse@40240000/wcn-alpha@14";
		wcn_beta = "/soc/aon/efuse@40240000/wcn-beta@18";
		wcn_gamma = "/soc/aon/efuse@40240000/wcn-gamma@1c";
		wcn_delta = "/soc/aon/efuse@40240000/wcn-delta@20";
		dvfs_bin_dsu = "/soc/aon/efuse@40240000/dvfs-bin-dsu@a";
		dvfs_bin_cpu0 = "/soc/aon/efuse@40240000/dvfs-bin-cpu0@9";
		dvfs_bin_cpu1 = "/soc/aon/efuse@40240000/dvfs-bin-cpu1@9";
		pwms = "/soc/aon/pwm@40260000";
		pin_controller = "/soc/aon/pinctrl@402a0000";
		vbc_iis1_0 = "/soc/aon/pinctrl@402a0000/iismtx-inf0-8";
		ap_iis0_0 = "/soc/aon/pinctrl@402a0000/iismtx-inf0-0";
		ap_iis1_0 = "/soc/aon/pinctrl@402a0000/iismtx-inf0-1";
		tgdsp_iis0_0 = "/soc/aon/pinctrl@402a0000/iismtx-inf0-4";
		tgdsp_iis1_0 = "/soc/aon/pinctrl@402a0000/iismtx-inf0-5";
		pubcp_iis0_0 = "/soc/aon/pinctrl@402a0000/iismtx-inf0-3";
		vbc_iis1_3 = "/soc/aon/pinctrl@402a0000/iismtx-inf3-8";
		ap_iis0_3 = "/soc/aon/pinctrl@402a0000/iismtx-inf3-0";
		tgdsp_iis0_3 = "/soc/aon/pinctrl@402a0000/iismtx-inf3-4";
		tgdsp_iis1_3 = "/soc/aon/pinctrl@402a0000/iismtx-inf3-5";
		pubcp_iis0_3 = "/soc/aon/pinctrl@402a0000/iismtx-inf3-3";
		wcn_iis0_3 = "/soc/aon/pinctrl@402a0000/iismtx-inf3-11";
		vbc_iis1_4 = "/soc/aon/pinctrl@402a0000/iismtx-inf4-8";
		ap_iis0_4 = "/soc/aon/pinctrl@402a0000/iismtx-inf4-0";
		tgdsp_iis0_4 = "/soc/aon/pinctrl@402a0000/iismtx-inf4-4";
		tgdsp_iis1_4 = "/soc/aon/pinctrl@402a0000/iismtx-inf4-5";
		pubcp_iis0_4 = "/soc/aon/pinctrl@402a0000/iismtx-inf4-3";
		wcn_iis0_4 = "/soc/aon/pinctrl@402a0000/iismtx-inf4-11";
		iis_loop_3_4_enable = "/soc/aon/pinctrl@402a0000/iismtx-inf3-inf4-loop-1";
		iis_loop_3_4_disable = "/soc/aon/pinctrl@402a0000/iismtx-inf3-inf4-loop-0";
		ts_int_pullup = "/soc/aon/pinctrl@402a0000/ts_int_pullup";
		ts_int_nopull = "/soc/aon/pinctrl@402a0000/ts_int_nopull";
		ts_int_pulldown = "/soc/aon/pinctrl@402a0000/ts_int_pulldown";
		ts_reset_pullup = "/soc/aon/pinctrl@402a0000/ts_reset_pullup";
		ts_reset_pulldown = "/soc/aon/pinctrl@402a0000/ts_reset_pulldown";
		gpio_121 = "/soc/aon/pinctrl@402a0000/keyout0";
		gpio_122 = "/soc/aon/pinctrl@402a0000/keyout1";
		gpio_123 = "/soc/aon/pinctrl@402a0000/keyout2";
		gpio_124 = "/soc/aon/pinctrl@402a0000/keyin0";
		gpio_125 = "/soc/aon/pinctrl@402a0000/keyin1";
		gpio_126 = "/soc/aon/pinctrl@402a0000/keyin2";
		gpio_144 = "/soc/aon/pinctrl@402a0000/extint0";
		gpio_145 = "/soc/aon/pinctrl@402a0000/extint1";
		gpio_146 = "/soc/aon/pinctrl@402a0000/scl3";
		gpio_147 = "/soc/aon/pinctrl@402a0000/sda3";
		shutdown0 = "/soc/aon/pinctrl@402a0000/rfsen0";
		shutdown1 = "/soc/aon/pinctrl@402a0000/rfsck0";
		shutdown2 = "/soc/aon/pinctrl@402a0000/rfsda0";
		shutdown3 = "/soc/aon/pinctrl@402a0000/rfsen1";
		shutdown4 = "/soc/aon/pinctrl@402a0000/rfsck1";
		shutdown5 = "/soc/aon/pinctrl@402a0000/rfsda1";
		ap_gpio = "/soc/aon/gpio-controller@402c0000";
		gpu_thm = "/soc/aon/gpu-thm@402f0000";
		cpu_thm = "/soc/aon/cpu-thm@40390000";
		hwlock = "/soc/aon/hwspinlock@40060000";
		i2c7 = "/soc/aon/i2c@40080000";
		fan53555_dcdc = "/soc/aon/i2c@40080000/regulator@60";
		sprd_hwdvfs = "/soc/aon/hwdvfs@40300000";
		hwdvfs_cluster0 = "/soc/aon/hwdvfs@40300000/cluster@0";
		hwdvfs_cluster1 = "/soc/aon/hwdvfs@40300000/cluster@1";
		hwdvfs_dsu = "/soc/aon/hwdvfs@40300000/dsu@0";
		dcdc_ctrl0 = "/soc/aon/hwdvfs@40300000/dcdc-controller@0";
		dcdc_ctrl1 = "/soc/aon/hwdvfs@40300000/dcdc-controller@1";
		sprd_swdvfs = "/soc/aon/sprd-swdvfs";
		djtag = "/soc/aon/djtag@40340000";
		adi_bus = "/soc/aon/spi@41800000";
		sc2721_pmic = "/soc/aon/spi@41800000/pmic@0";
		pmic_eic = "/soc/aon/spi@41800000/pmic@0/gpio-controller@280";
		pmic_flash = "/soc/aon/spi@41800000/pmic@0/flash@2a8";
		fgu_calib = "/soc/aon/spi@41800000/pmic@0/efuse@300/calib@6";
		adc_bcal = "/soc/aon/spi@41800000/pmic@0/efuse@300/calib@24";
		adc_scal = "/soc/aon/spi@41800000/pmic@0/efuse@300/calib@26";
		cc_cal = "/soc/aon/spi@41800000/pmic@0/efuse@300/calib@1a";
		efuse_blk0 = "/soc/aon/spi@41800000/pmic@0/efuse@300/calib@0";
		efuse_blk14 = "/soc/aon/spi@41800000/pmic@0/efuse@300/calib@28";
		efuse_blk16 = "/soc/aon/spi@41800000/pmic@0/efuse@300/calib@2c";
		pmic_typec = "/soc/aon/spi@41800000/pmic@0/typec@380";
		pmic_adc = "/soc/aon/spi@41800000/pmic@0/adc@400";
		pmic_fgu = "/soc/aon/spi@41800000/pmic@0/fgu@a00";
		sprd_audio_codec_ana = "/soc/aon/spi@41800000/pmic@0/audio-codec@700";
		vddcpu = "/soc/aon/spi@41800000/pmic@0/power-controller@c00/DCDC_CPU";
		vddcore = "/soc/aon/spi@41800000/pmic@0/power-controller@c00/DCDC_CORE";
		vddmem = "/soc/aon/spi@41800000/pmic@0/power-controller@c00/DCDC_MEM";
		vddgen = "/soc/aon/spi@41800000/pmic@0/power-controller@c00/DCDC_GEN";
		vddcama = "/soc/aon/spi@41800000/pmic@0/power-controller@c00/LDO_VDDCAMA";
		vddcammot = "/soc/aon/spi@41800000/pmic@0/power-controller@c00/LDO_VDDCAMMOT";
		vddsim2 = "/soc/aon/spi@41800000/pmic@0/power-controller@c00/LDO_VDDSIM2";
		vddemmccore = "/soc/aon/spi@41800000/pmic@0/power-controller@c00/LDO_VDDEMMCCORE";
		vddsdcore = "/soc/aon/spi@41800000/pmic@0/power-controller@c00/LDO_VDDSDCORE";
		vddsdio = "/soc/aon/spi@41800000/pmic@0/power-controller@c00/LDO_VDDSDIO";
		vdd28 = "/soc/aon/spi@41800000/pmic@0/power-controller@c00/LDO_VDD28";
		vddwifipa = "/soc/aon/spi@41800000/pmic@0/power-controller@c00/LDO_VDDWIFIPA";
		vdddcxo = "/soc/aon/spi@41800000/pmic@0/power-controller@c00/LDO_VDDDCXO";
		vddusb33 = "/soc/aon/spi@41800000/pmic@0/power-controller@c00/LDO_VDDUSB33";
		vddcamd = "/soc/aon/spi@41800000/pmic@0/power-controller@c00/LDO_VDDCAMD";
		vddcon = "/soc/aon/spi@41800000/pmic@0/power-controller@c00/LDO_VDDCON";
		vddcamio = "/soc/aon/spi@41800000/pmic@0/power-controller@c00/LDO_VDDCAMIO";
		vdd18 = "/soc/aon/spi@41800000/pmic@0/power-controller@c00/LDO_VDD18";
		vddrf18 = "/soc/aon/spi@41800000/pmic@0/power-controller@c00/LDO_VDDRF18";
		vddrf125 = "/soc/aon/spi@41800000/pmic@0/power-controller@c00/LDO_VDDRF125";
		vddldomem = "/soc/aon/spi@41800000/pmic@0/power-controller@c00/LDO_VDDLDOMEM";
		vddkpled = "/soc/aon/spi@41800000/pmic@0/power-controller@c00/LDO_VDDKPLED";
		pmic_charger = "/soc/aon/spi@41800000/pmic@0/charger@ec0";
		cam_domain = "/soc/mm/cam-domain";
		gpu = "/soc/mm/gpu@60000000";
		dpu = "/soc/mm/dpu@63000000";
		dpu_port = "/soc/mm/dpu@63000000/port";
		dpu_out = "/soc/mm/dpu@63000000/port/endpoint";
		gsp_core0 = "/soc/mm/gsp@63000000";
		iommu_dispc = "/soc/mm/iommu@63000000";
		vsp = "/soc/mm/video-codec@62200000";
		iommu_vsp = "/soc/mm/iommu@62201000";
		jpg = "/soc/mm/jpeg-codec@62300000";
		iommu_jpg = "/soc/mm/iommu@62300000";
		dsi = "/soc/mm/dsi@63100000";
		dsi_out = "/soc/mm/dsi@63100000/ports/port@0/endpoint";
		dsi_in = "/soc/mm/dsi@63100000/ports/port@1/endpoint";
		panel = "/soc/mm/dsi@63100000/panel";
		panel_in = "/soc/mm/dsi@63100000/panel/port/endpoint";
		dphy = "/soc/mm/dphy";
		dphy_out = "/soc/mm/dphy/port@0/endpoint";
		dphy_in = "/soc/mm/dphy/port@1/endpoint";
		mipi_csi_phy0 = "/soc/mm/mipi-csi-phy0";
		mipi_csi_phy1 = "/soc/mm/mipi-csi-phy1";
		mipi_csi_phy2 = "/soc/mm/mipi-csi-phy2";
		mipi_csi_phy0_m = "/soc/mm/mipi-csi-phy0-s";
		mipi_csi_phy0_s = "/soc/mm/mipi-csi-phy0-m";
		mipi_csi_phy0_s1 = "/soc/mm/mipi-csi-phy0-m1";
		dcam = "/soc/mm/dcam@60a00000";
		iommu_dcam = "/soc/mm/iommu@60a00040";
		isp = "/soc/mm/isp@60b00000";
		iommu_isp = "/soc/mm/iommu@60b00000";
		csi0 = "/soc/mm/csi@60c00000";
		csi1 = "/soc/mm/csi@60d00000";
		csi2 = "/soc/mm/csi@60e00000";
		cpp = "/soc/mm/cpp@62400000";
		iommu_cpp = "/soc/mm/iommu@62400000";
		dmc_controller = "/soc/pub/dmc-controller@30000000";
		ptm_trace = "/soc/pub/ptm@30010000";
		dmc_mpu = "/soc/pub/dmc-mpu@300e0000";
		pmu_gate = "/soc/pmu-gate";
		pll = "/soc/pll";
		mpll = "/soc/mpll";
		rpll = "/soc/rpll";
		dpll = "/soc/dpll";
		ap_clk = "/soc/clock-controller@21500000";
		aon_clk = "/soc/clock-controller@402d0000";
		apahb_gate = "/soc/apahb-gate";
		aonapb_gate = "/soc/aonapb-gate";
		mm_clk = "/soc/clock-controller@60900000";
		mm_gate = "/soc/mm-gate";
		vspahb_gate = "/soc/vspahb-gate";
		apapb_gate = "/soc/apapb-gate";
		funnel_soc_out_port0 = "/soc/funnel@10001000/ports/port@0/endpoint";
		funnel_soc_in_port0 = "/soc/funnel@10001000/ports/port@1/endpoint";
		etb_in = "/soc/etb@10003000/port/endpoint";
		funnel_little_out_port0 = "/soc/funnel@12001000/ports/port@0/endpoint";
		funnel_little_in_port0 = "/soc/funnel@12001000/ports/port@1/endpoint";
		funnel_little_in_port1 = "/soc/funnel@12001000/ports/port@2/endpoint";
		funnel_little_in_port2 = "/soc/funnel@12001000/ports/port@3/endpoint";
		funnel_little_in_port3 = "/soc/funnel@12001000/ports/port@4/endpoint";
		etf_little_out = "/soc/etf@12002000/port@0/endpoint";
		etf_little_in = "/soc/etf@12002000/port@1/endpoint";
		etf_big_out = "/soc/etf@12003000/port@0/endpoint";
		etf_big_in = "/soc/etf@12003000/port@1/endpoint";
		funnel_ca55_out_port0 = "/soc/funnel@12004000/ports/port@0/endpoint";
		funnel_ca55_in_port0 = "/soc/funnel@12004000/ports/port@1/endpoint";
		funnel_ca55_in_port1 = "/soc/funnel@12004000/ports/port@2/endpoint";
		funnel_big_out_port0 = "/soc/funnel@12005000/ports/port@0/endpoint";
		funnel_big_in_port0 = "/soc/funnel@12005000/ports/port@1/endpoint";
		funnel_big_in_port1 = "/soc/funnel@12005000/ports/port@2/endpoint";
		funnel_big_in_port2 = "/soc/funnel@12005000/ports/port@3/endpoint";
		funnel_big_in_port3 = "/soc/funnel@12005000/ports/port@4/endpoint";
		etm0_out = "/soc/etm@13040000/port/endpoint";
		etm1_out = "/soc/etm@13140000/port/endpoint";
		etm2_out = "/soc/etm@13240000/port/endpoint";
		etm3_out = "/soc/etm@13340000/port/endpoint";
		etm4_out = "/soc/etm@13440000/port/endpoint";
		etm5_out = "/soc/etm@13540000/port/endpoint";
		etm6_out = "/soc/etm@13640000/port/endpoint";
		etm7_out = "/soc/etm@13740000/port/endpoint";
		ext_26m = "/ext-26m";
		ext_13m = "/ext-13m";
		ext_6m5 = "/ext-6m5";
		ext_4m3 = "/ext-4m3";
		ext_4m = "/ext-4m";
		ext_250k = "/ext-250k";
		ext_32k = "/ext-32k";
		ext_1k = "/ext-1k";
		ext_1m = "/ext-1m";
		ext_2m = "/ext-2m";
		ext_rc0_4m = "/ext-rc0-4m";
		clk_pad = "/clk-pad";
		rco_100m = "/rco-100m";
		sprd_pcm = "/sprd-pcm-audio";
		vaudio = "/vaudio";
		sprd_pcm_iis = "/sprd-pcm-iis";
		CPU0 = "/cpus/cpu@0";
		CPU1 = "/cpus/cpu@100";
		CPU2 = "/cpus/cpu@200";
		CPU3 = "/cpus/cpu@300";
		CPU4 = "/cpus/cpu@400";
		CPU5 = "/cpus/cpu@500";
		CPU6 = "/cpus/cpu@600";
		CPU7 = "/cpus/cpu@700";
		CPU_COST_0 = "/energy-costs/core-cost0";
		CPU_COST_1 = "/energy-costs/core-cost1";
		CLUSTER_COST_0 = "/energy-costs/cluster-cost0";
		CLUSTER_COST_1 = "/energy-costs/cluster-cost1";
		CORE_PD = "/idle-states/core_pd";
		cpufreq_clus0 = "/cpufreq-clus0";
		cpufreq_clus1 = "/cpufreq-clus1";
		cpufreq_fcm = "/cpufreq-fcm";
		gic = "/interrupt-controller@14000000";
		v2m_0 = "/interrupt-controller@14000000/v2m@0";
		power = "/power-debug";
		sprd_pwr_status0 = "/power-debug/pwr-status@bc";
		sprd_pwr_status1 = "/power-debug/pwr-status@c0";
		sprd_pwr_status2 = "/power-debug/pwr-status@c4";
		sprd_pwr_status3 = "/power-debug/pwr-status@48c";
		sprd_pwr_status4 = "/power-debug/pwr-status@490";
		sprd_pwr_status5 = "/power-debug/pwr-status@128";
		sprd_ap_intc0 = "/power-debug/ap-intc@0";
		sprd_ap_intc1 = "/power-debug/ap-intc@1";
		sprd_ap_intc2 = "/power-debug/ap-intc@2";
		sprd_ap_intc3 = "/power-debug/ap-intc@3";
		sprd_ap_intc4 = "/power-debug/ap-intc@4";
		sprd_ap_intc5 = "/power-debug/ap-intc@5";
		gsp = "/sprd-gsp";
		wcn_btwf = "/cpwcn_btwf";
		wcn_gnss = "/cpwcn_gnss";
		sipc2 = "/wcn_sipc/sipc@84180000";
		sipc3 = "/wcn_sipc/sipc@8441b000";
		scproc_pubpm = "/scproc-pubcp/scproc@800000";
		scproc_pubcp = "/scproc-pubcp/scproc@f000";
		sipc0 = "/sprd-sipc/sipc@87800000";
		sipc1 = "/sprd-sipc/sipc@d000";
		seth_ch7 = "/seth@0";
		seth_ch8 = "/seth@1";
		seth_ch9 = "/seth@2";
		seth_ch18 = "/seth@3";
		seth_ch19 = "/seth@4";
		seth_ch20 = "/seth@5";
		seth_ch24 = "/seth@6";
		seth_ch25 = "/seth@7";
		seth_ch26 = "/seth@8";
		seth_ch27 = "/seth@9";
		seth_ch28 = "/seth@10";
		seth_ch29 = "/seth@11";
		seth_ch30 = "/seth@12";
		seth_ch31 = "/seth@13";
		lcd_dummy_mipi_hd = "/lcds/lcd_dummy_mipi_hd";
		lcd_hx83102d_mipi = "/lcds/lcd_hx83102d_mipi";
		lcd_ft8006_mipi = "/lcds/lcd_ft8006_mipi";
		lcd_hx93102d_mipi = "/lcds/lcd_hx93102d_mipi";
		lcd_ili9882n_mipi = "/lcds/lcd_ili9882n_mipi";
		sprd_headset = "/sprd-headset";
		sound_vbc_r1p0v3_sprd_codec = "/sound@0";
		sound_sprd_ap_alliis = "/sound@1";
		thm_zone = "/thermal-zones";
		cpu_thmzone = "/thermal-zones/cpu-thmzone";
		cpu_threshold = "/thermal-zones/cpu-thmzone/trips/trip-point@0";
		cpu_target = "/thermal-zones/cpu-thmzone/trips/trip-point@1";
		cpu_crit = "/thermal-zones/cpu-thmzone/trips/bia_crit";
		gpu_thmzone = "/thermal-zones/gpu-thmzone";
		bd_thmzone = "/thermal-zones/board-thmzone";
		cluster0_cooling = "/cooling-devices/cluster0-cooling";
		cluster1_cooling = "/cooling-devices/cluster1-cooling";
		gpu_cooling0 = "/gpu-cooling-devices/gpu-cooling0";
		ddr_dfs = "/scene-frequency";
		reserved_memory = "/reserved-memory";
		smem_reserved = "/reserved-memory/sipc-mem@87800000";
		cp_reserved = "/reserved-memory/cp-modem@89600000";
		iq_reserved = "/reserved-memory/iq-mem@90000000";
		sml_reserved = "/reserved-memory/sml-mem@94000000";
		tos_reserved = "/reserved-memory/tos-mem@94020000";
		pstore_reserved = "/reserved-memory/ramoops@fff80000";
		wcn_reserved = "/reserved-memory/wcn-mem@84000000";
		gnss_reserved = "/reserved-memory/gnss-mem@84300000";
		logo_reserved = "/reserved-memory/logobuffer@fd580000";
		camera_reserved = "/reserved-memory/camera@fdd69000";
		fb_reserved = "/reserved-memory/framebuffer@fe769000";
		autotest = "/autotest";
		memory = "/memory";
		ipi = "/interrupt-controller";
		revo_ion = "/ion";
		gpio_keys = "/gpio-keys";
		tboard_thermistor = "/thermal-sensor";
		bat = "/battery";
		charger_manager = "/charger-manager";
		extcon_gpio = "/extcon-gpio";
		blestech_fp = "/fingerprint_blestech";
		cdfinger_fp = "/cdfinger_fingerprint";
		sunwave_fp = "/sunwave-fp";
		microarray_fp = "/ma-fingerprint";
		chipone_fp = "/fpsensor-fp";
	};
};
